VERSION ""

NS_ :

BS_:

BU_:

BO_ 2365446142 EJM1: 8 Vector__XXX
 SG_ Joystick1Button13PressedStatus : 62|2@1+ (1,0) [0|3] "" Vector__XXX
 SG_ Joystick1Button14PressedStatus : 60|2@1+ (1,0) [0|3] "" Vector__XXX
 SG_ Joystick1Button15PressedStatus : 58|2@1+ (1,0) [0|3] "" Vector__XXX
 SG_ Joystick1Button16PressedStatus : 56|2@1+ (1,0) [0|3] "" Vector__XXX
 SG_ Joystick1GripXAxisPosition : 6|10@1+ (0.1,0) [0|102] "%" Vector__XXX
 SG_ Joystick1GripYAxisPosition : 22|10@1+ (0.1,0) [0|102] "%" Vector__XXX
 SG_ Joystick1ThetaAxisPosition : 38|10@1+ (0.1,0) [0|102] "%" Vector__XXX
 SG_ Jst1GpYAxsLvFwdPstvPstStts : 20|2@1+ (1,0) [0|3] "" Vector__XXX
 SG_ Jst1TtAxsCtCwsNtvPstStts : 34|2@1+ (1,0) [0|3] "" Vector__XXX
 SG_ Jstk1GrpXAxsDtntPstnStts : 54|2@1+ (1,0) [0|3] "" Vector__XXX
 SG_ Jstk1GrpXAxsLvrLftNgtvPstnStts : 2|2@1+ (1,0) [0|3] "" Vector__XXX
 SG_ Jstk1GrpXAxsLvrRghtPstvPstnStts : 4|2@1+ (1,0) [0|3] "" Vector__XXX
 SG_ Jstk1GrpXAxsNtrlPstnStts : 0|2@1+ (1,0) [0|3] "" Vector__XXX
 SG_ Jstk1GrpYAxsDtntPstnStts : 52|2@1+ (1,0) [0|3] "" Vector__XXX
 SG_ Jstk1GrpYAxsLvrBkNgtvPstnStts : 18|2@1+ (1,0) [0|3] "" Vector__XXX
 SG_ Jstk1GrpYAxsNtrlPstnStts : 16|2@1+ (1,0) [0|3] "" Vector__XXX
 SG_ Jstk1ThtAxsClkwsPstvPstnStts : 36|2@1+ (1,0) [0|3] "" Vector__XXX
 SG_ Jstk1ThtAxsDtntPstnStts : 50|2@1+ (1,0) [0|3] "" Vector__XXX
 SG_ Jstk1ThtAxsNtrlPstnStts : 32|2@1+ (1,0) [0|3] "" Vector__XXX

BO_ 2365446398 BJM2: 8 Vector__XXX
 SG_ Joystick2Button10PressedStatus : 60|2@1+ (1,0) [0|3] "" Vector__XXX
 SG_ Joystick2Button11PressedStatus : 58|2@1+ (1,0) [0|3] "" Vector__XXX
 SG_ Joystick2Button12PressedStatus : 56|2@1+ (1,0) [0|3] "" Vector__XXX
 SG_ Joystick2Button1PressedStatus : 46|2@1+ (1,0) [0|3] "" Vector__XXX
 SG_ Joystick2Button2PressedStatus : 44|2@1+ (1,0) [0|3] "" Vector__XXX
 SG_ Joystick2Button3PressedStatus : 42|2@1+ (1,0) [0|3] "" Vector__XXX
 SG_ Joystick2Button4PressedStatus : 40|2@1+ (1,0) [0|3] "" Vector__XXX
 SG_ Joystick2Button5PressedStatus : 54|2@1+ (1,0) [0|3] "" Vector__XXX
 SG_ Joystick2Button6PressedStatus : 52|2@1+ (1,0) [0|3] "" Vector__XXX
 SG_ Joystick2Button7PressedStatus : 50|2@1+ (1,0) [0|3] "" Vector__XXX
 SG_ Joystick2Button8PressedStatus : 48|2@1+ (1,0) [0|3] "" Vector__XXX
 SG_ Joystick2Button9PressedStatus : 62|2@1+ (1,0) [0|3] "" Vector__XXX
 SG_ Joystick2XAxisPosition : 6|10@1+ (0.1,0) [0|102] "%" Vector__XXX
 SG_ Joystick2YAxisPosition : 22|10@1+ (0.1,0) [0|102] "%" Vector__XXX
 SG_ Jstk2XAxsDtntPstnStts : 38|2@1+ (1,0) [0|3] "" Vector__XXX
 SG_ Jstk2XAxsLvrLftNgtvPstnStts : 2|2@1+ (1,0) [0|3] "" Vector__XXX
 SG_ Jstk2XAxsLvrRghtPstvPstnStts : 4|2@1+ (1,0) [0|3] "" Vector__XXX
 SG_ Jstk2XAxsNtrlPstnStts : 0|2@1+ (1,0) [0|3] "" Vector__XXX
 SG_ Jstk2YAxsDtntPstnStts : 36|2@1+ (1,0) [0|3] "" Vector__XXX
 SG_ Jstk2YAxsLvrBkNgtvPstnStts : 18|2@1+ (1,0) [0|3] "" Vector__XXX
 SG_ Jstk2YAxsLvrFrwrdPstvPstnStts : 20|2@1+ (1,0) [0|3] "" Vector__XXX
 SG_ Jstk2YAxsNtrlPstnStts : 16|2@1+ (1,0) [0|3] "" Vector__XXX

BO_ 2365446654 EJM2: 8 Vector__XXX
 SG_ Joystick2Button13PressedStatus : 62|2@1+ (1,0) [0|3] "" Vector__XXX
 SG_ Joystick2Button14PressedStatus : 60|2@1+ (1,0) [0|3] "" Vector__XXX
 SG_ Joystick2Button15PressedStatus : 58|2@1+ (1,0) [0|3] "" Vector__XXX
 SG_ Joystick2Button16PressedStatus : 56|2@1+ (1,0) [0|3] "" Vector__XXX
 SG_ Joystick2GripXAxisPosition : 6|10@1+ (0.1,0) [0|102] "%" Vector__XXX
 SG_ Joystick2GripYAxisPosition : 22|10@1+ (0.1,0) [0|102] "%" Vector__XXX
 SG_ Joystick2ThetaAxisPosition : 38|10@1+ (0.1,0) [0|102] "%" Vector__XXX
 SG_ Jst2GpYAxsLvFwdPstvPstStts : 20|2@1+ (1,0) [0|3] "" Vector__XXX
 SG_ Jst2TtAxsCtCwsNtvPstStts : 34|2@1+ (1,0) [0|3] "" Vector__XXX
 SG_ Jstk2GrpXAxsDtntPstnStts : 54|2@1+ (1,0) [0|3] "" Vector__XXX
 SG_ Jstk2GrpXAxsLvrLftNgtvPstnStts : 2|2@1+ (1,0) [0|3] "" Vector__XXX
 SG_ Jstk2GrpXAxsLvrRghtPstvPstnStts : 4|2@1+ (1,0) [0|3] "" Vector__XXX
 SG_ Jstk2GrpXAxsNtrlPstnStts : 0|2@1+ (1,0) [0|3] "" Vector__XXX
 SG_ Jstk2GrpYAxsDtntPstnStts : 52|2@1+ (1,0) [0|3] "" Vector__XXX
 SG_ Jstk2GrpYAxsLvrBkNgtvPstnStts : 18|2@1+ (1,0) [0|3] "" Vector__XXX
 SG_ Jstk2GrpYAxsNtrlPstnStts : 16|2@1+ (1,0) [0|3] "" Vector__XXX
 SG_ Jstk2ThtAxsClkwsPstvPstnStts : 36|2@1+ (1,0) [0|3] "" Vector__XXX
 SG_ Jstk2ThtAxsDtntPstnStts : 50|2@1+ (1,0) [0|3] "" Vector__XXX
 SG_ Jstk2ThtAxsNtrlPstnStts : 32|2@1+ (1,0) [0|3] "" Vector__XXX

BO_ 2365446910 BJM3: 8 Vector__XXX
 SG_ Joystick3Button10PressedStatus : 60|2@1+ (1,0) [0|3] "" Vector__XXX
 SG_ Joystick3Button11PressedStatus : 58|2@1+ (1,0) [0|3] "" Vector__XXX
 SG_ Joystick3Button12PressedStatus : 56|2@1+ (1,0) [0|3] "" Vector__XXX
 SG_ Joystick3Button1PressedStatus : 46|2@1+ (1,0) [0|3] "" Vector__XXX
 SG_ Joystick3Button2PressedStatus : 44|2@1+ (1,0) [0|3] "" Vector__XXX
 SG_ Joystick3Button3PressedStatus : 42|2@1+ (1,0) [0|3] "" Vector__XXX
 SG_ Joystick3Button4PressedStatus : 40|2@1+ (1,0) [0|3] "" Vector__XXX
 SG_ Joystick3Button5PressedStatus : 54|2@1+ (1,0) [0|3] "" Vector__XXX
 SG_ Joystick3Button6PressedStatus : 52|2@1+ (1,0) [0|3] "" Vector__XXX
 SG_ Joystick3Button7PressedStatus : 50|2@1+ (1,0) [0|3] "" Vector__XXX
 SG_ Joystick3Button8PressedStatus : 48|2@1+ (1,0) [0|3] "" Vector__XXX
 SG_ Joystick3Button9PressedStatus : 62|2@1+ (1,0) [0|3] "" Vector__XXX
 SG_ Joystick3XAxisPosition : 6|10@1+ (0.1,0) [0|102] "%" Vector__XXX
 SG_ Joystick3YAxisPosition : 22|10@1+ (0.1,0) [0|102] "%" Vector__XXX
 SG_ Jstk3XAxsDtntPstnStts : 38|2@1+ (1,0) [0|3] "" Vector__XXX
 SG_ Jstk3XAxsLvrLftNgtvPstnStts : 2|2@1+ (1,0) [0|3] "" Vector__XXX
 SG_ Jstk3XAxsLvrRghtPstvPstnStts : 4|2@1+ (1,0) [0|3] "" Vector__XXX
 SG_ Jstk3XAxsNtrlPstnStts : 0|2@1+ (1,0) [0|3] "" Vector__XXX
 SG_ Jstk3YAxsDtntPstnStts : 36|2@1+ (1,0) [0|3] "" Vector__XXX
 SG_ Jstk3YAxsLvrBkNgtvPstnStts : 18|2@1+ (1,0) [0|3] "" Vector__XXX
 SG_ Jstk3YAxsLvrFrwrdPstvPstnStts : 20|2@1+ (1,0) [0|3] "" Vector__XXX
 SG_ Jstk3YAxsNtrlPstnStts : 16|2@1+ (1,0) [0|3] "" Vector__XXX

BO_ 2365447166 EJM3: 8 Vector__XXX
 SG_ Joystick3Button13PressedStatus : 62|2@1+ (1,0) [0|3] "" Vector__XXX
 SG_ Joystick3Button14PressedStatus : 60|2@1+ (1,0) [0|3] "" Vector__XXX
 SG_ Joystick3Button15PressedStatus : 58|2@1+ (1,0) [0|3] "" Vector__XXX
 SG_ Joystick3Button16PressedStatus : 56|2@1+ (1,0) [0|3] "" Vector__XXX
 SG_ Joystick3GripXAxisPosition : 6|10@1+ (0.1,0) [0|102] "%" Vector__XXX
 SG_ Joystick3GripYAxisPosition : 22|10@1+ (0.1,0) [0|102] "%" Vector__XXX
 SG_ Joystick3ThetaAxisPosition : 38|10@1+ (0.1,0) [0|102] "%" Vector__XXX
 SG_ Jst3GpYAxsLvFwdPstvPstStts : 20|2@1+ (1,0) [0|3] "" Vector__XXX
 SG_ Jst3TtAxsCtCwsNtvPstStts : 34|2@1+ (1,0) [0|3] "" Vector__XXX
 SG_ Jstk3GrpXAxsDtntPstnStts : 54|2@1+ (1,0) [0|3] "" Vector__XXX
 SG_ Jstk3GrpXAxsLvrLftNgtvPstnStts : 2|2@1+ (1,0) [0|3] "" Vector__XXX
 SG_ Jstk3GrpXAxsLvrRghtPstvPstnStts : 4|2@1+ (1,0) [0|3] "" Vector__XXX
 SG_ Jstk3GrpXAxsNtrlPstnStts : 0|2@1+ (1,0) [0|3] "" Vector__XXX
 SG_ Jstk3GrpYAxsDtntPstnStts : 52|2@1+ (1,0) [0|3] "" Vector__XXX
 SG_ Jstk3GrpYAxsLvrBkNgtvPstnStts : 18|2@1+ (1,0) [0|3] "" Vector__XXX
 SG_ Jstk3GrpYAxsNtrlPstnStts : 16|2@1+ (1,0) [0|3] "" Vector__XXX
 SG_ Jstk3ThtAxsClkwsPstvPstnStts : 36|2@1+ (1,0) [0|3] "" Vector__XXX
 SG_ Jstk3ThtAxsDtntPstnStts : 50|2@1+ (1,0) [0|3] "" Vector__XXX
 SG_ Jstk3ThtAxsNtrlPstnStts : 32|2@1+ (1,0) [0|3] "" Vector__XXX

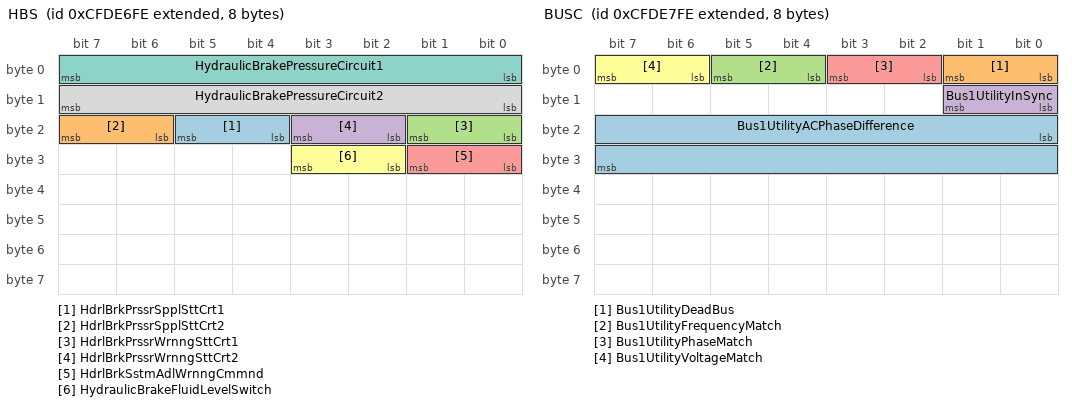
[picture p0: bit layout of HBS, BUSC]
BO_ 2365449982 HBS: 8 Vector__XXX
 SG_ HdrlBrkPrssrSpplSttCrt1 : 20|2@1+ (1,0) [0|3] "" Vector__XXX
 SG_ HdrlBrkPrssrSpplSttCrt2 : 22|2@1+ (1,0) [0|3] "" Vector__XXX
 SG_ HdrlBrkPrssrWrnngSttCrt1 : 16|2@1+ (1,0) [0|3] "" Vector__XXX
 SG_ HdrlBrkPrssrWrnngSttCrt2 : 18|2@1+ (1,0) [0|3] "" Vector__XXX
 SG_ HdrlBrkSstmAdlWrnngCmmnd : 24|2@1+ (1,0) [0|3] "" Vector__XXX
 SG_ HydraulicBrakeFluidLevelSwitch : 26|2@1+ (1,0) [0|3] "" Vector__XXX
 SG_ HydraulicBrakePressureCircuit1 : 0|8@1+ (100,0) [0|25000] "kPa" Vector__XXX
 SG_ HydraulicBrakePressureCircuit2 : 8|8@1+ (100,0) [0|25000] "kPa" Vector__XXX

BO_ 2365450238 BUSC: 8 Vector__XXX
 SG_ Bus1UtilityACPhaseDifference : 16|16@1+ (0.0078125,-200) [-200|301.99] "deg" Vector__XXX
 SG_ Bus1UtilityDeadBus : 0|2@1+ (1,0) [0|3] "" Vector__XXX
 SG_ Bus1UtilityFrequencyMatch : 4|2@1+ (1,0) [0|3] "" Vector__XXX
 SG_ Bus1UtilityInSync : 8|2@1+ (1,0) [0|3] "" Vector__XXX
 SG_ Bus1UtilityPhaseMatch : 2|2@1+ (1,0) [0|3] "" Vector__XXX
 SG_ Bus1UtilityVoltageMatch : 6|2@1+ (1,0) [0|3] "" Vector__XXX

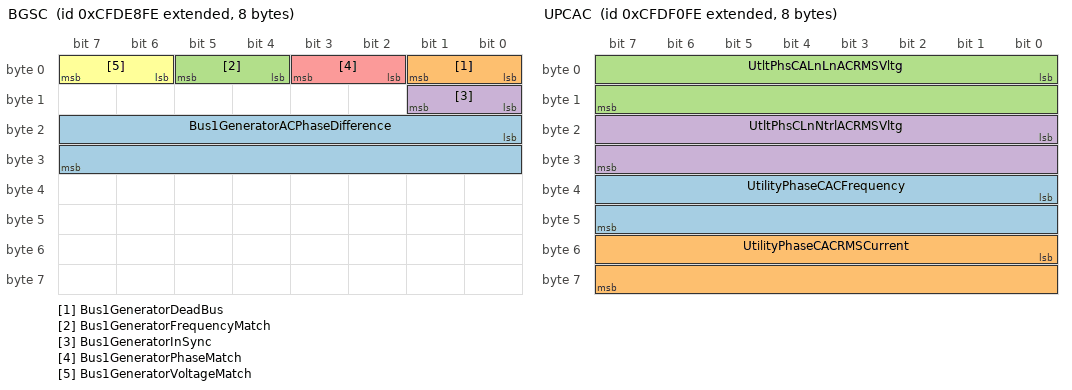
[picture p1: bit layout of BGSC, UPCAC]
BO_ 2365450494 BGSC: 8 Vector__XXX
 SG_ Bus1GeneratorACPhaseDifference : 16|16@1+ (0.0078125,-200) [-200|301.99] "deg" Vector__XXX
 SG_ Bus1GeneratorDeadBus : 0|2@1+ (1,0) [0|3] "" Vector__XXX
 SG_ Bus1GeneratorFrequencyMatch : 4|2@1+ (1,0) [0|3] "" Vector__XXX
 SG_ Bus1GeneratorInSync : 8|2@1+ (1,0) [0|3] "" Vector__XXX
 SG_ Bus1GeneratorPhaseMatch : 2|2@1+ (1,0) [0|3] "" Vector__XXX
 SG_ Bus1GeneratorVoltageMatch : 6|2@1+ (1,0) [0|3] "" Vector__XXX

BO_ 2365450750 BPCAC: 8 Vector__XXX
 SG_ Bs1PhsCLnNtrlACRMSVltg : 16|16@1+ (1,0) [0|64255] "V" Vector__XXX
 SG_ Bus1PhaseCACFrequency : 32|16@1+ (0.0078125,0) [0|501.9921875] "Hz" Vector__XXX
 SG_ Bus1PhaseCALineLineACRMSVoltage : 0|16@1+ (1,0) [0|64255] "V" Vector__XXX

BO_ 2365451006 BPBAC: 8 Vector__XXX
 SG_ Bs1PhsBLnNtrlACRMSVltg : 16|16@1+ (1,0) [0|64255] "V" Vector__XXX
 SG_ Bus1PhaseBACFrequency : 32|16@1+ (0.0078125,0) [0|501.9921875] "Hz" Vector__XXX
 SG_ Bus1PhaseBCLineLineACRMSVoltage : 0|16@1+ (1,0) [0|64255] "V" Vector__XXX

BO_ 2365451262 BPAAC: 8 Vector__XXX
 SG_ Bs1PhsALnNtrlACRMSVltg : 16|16@1+ (1,0) [0|64255] "V" Vector__XXX
 SG_ Bus1PhaseAACFrequency : 32|16@1+ (0.0078125,0) [0|501.9921875] "Hz" Vector__XXX
 SG_ Bus1PhaseABLineLineACRMSVoltage : 0|16@1+ (1,0) [0|64255] "V" Vector__XXX

BO_ 2365451518 BAAC: 8 Vector__XXX
 SG_ Bs1AvrgLnNtrlACRMSVltg : 16|16@1+ (1,0) [0|64255] "V" Vector__XXX
 SG_ Bus1AverageACFrequency : 32|16@1+ (0.0078125,0) [0|501.9921875] "Hz" Vector__XXX
 SG_ Bus1AverageLineLineACRMSVoltage : 0|16@1+ (1,0) [0|64255] "V" Vector__XXX

BO_ 2365451774 UTACE: 8 Vector__XXX
 SG_ UtilityTotalkWHoursExport : 0|32@1+ (1,0) [0|4211081215] "kWh" Vector__XXX
 SG_ UtilityTotalkWHoursImport : 32|32@1+ (1,0) [0|4211081215] "kWh" Vector__XXX

BO_ 2365452030 UPCACR: 8 Vector__XXX
 SG_ UtilityPhaseCPowerFactor : 32|16@1+ (0.00006103515625,-1) [-1|2.921814] "" Vector__XXX
 SG_ UtilityPhaseCPowerFactorLagging : 48|2@1+ (1,0) [0|3] "" Vector__XXX
 SG_ UtilityPhaseCReactivePower : 0|32@1+ (1,-2000000000) [-2000000000|2211081215] "VAr" Vector__XXX

BO_ 2365452286 UPCACP: 8 Vector__XXX
 SG_ UtilityPhaseCApparentPower : 32|32@1+ (1,-2000000000) [-2000000000|2211081215] "VA" Vector__XXX
 SG_ UtilityPhaseCRealPower : 0|32@1+ (1,-2000000000) [-2000000000|2211081215] "W" Vector__XXX

BO_ 2365452542 UPCAC: 8 Vector__XXX
 SG_ UtilityPhaseCACFrequency : 32|16@1+ (0.0078125,0) [0|501.9921875] "Hz" Vector__XXX
 SG_ UtilityPhaseCACRMSCurrent : 48|16@1+ (1,0) [0|64255] "A" Vector__XXX
 SG_ UtltPhsCALnLnACRMSVltg : 0|16@1+ (1,0) [0|64255] "V" Vector__XXX
 SG_ UtltPhsCLnNtrlACRMSVltg : 16|16@1+ (1,0) [0|64255] "V" Vector__XXX

BO_ 2365452798 UPBACR: 8 Vector__XXX
 SG_ UtilityPhaseBPowerFactor : 32|16@1+ (0.00006103515625,-1) [-1|2.921814] "" Vector__XXX
 SG_ UtilityPhaseBPowerFactorLagging : 48|2@1+ (1,0) [0|3] "" Vector__XXX
 SG_ UtilityPhaseBReactivePower : 0|32@1+ (1,-2000000000) [-2000000000|2211081215] "VAr" Vector__XXX

BO_ 2365453054 UPBACP: 8 Vector__XXX
 SG_ UtilityPhaseBApparentPower : 32|32@1+ (1,-2000000000) [-2000000000|2211081215] "VA" Vector__XXX
 SG_ UtilityPhaseBRealPower : 0|32@1+ (1,-2000000000) [-2000000000|2211081215] "W" Vector__XXX

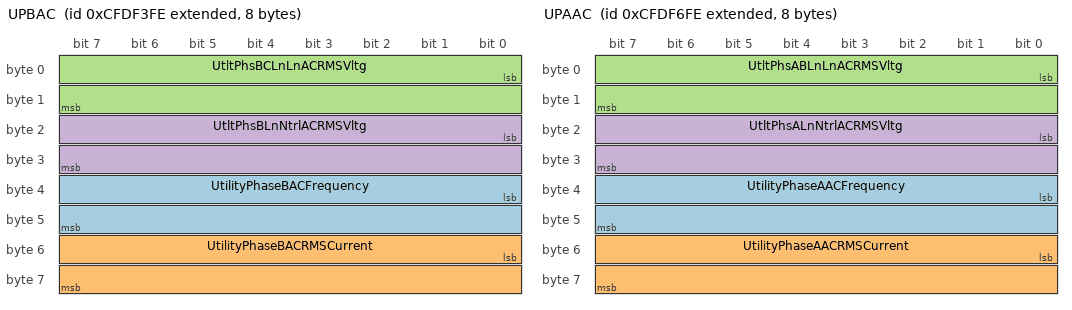
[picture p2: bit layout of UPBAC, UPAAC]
BO_ 2365453310 UPBAC: 8 Vector__XXX
 SG_ UtilityPhaseBACFrequency : 32|16@1+ (0.0078125,0) [0|501.9921875] "Hz" Vector__XXX
 SG_ UtilityPhaseBACRMSCurrent : 48|16@1+ (1,0) [0|64255] "A" Vector__XXX
 SG_ UtltPhsBCLnLnACRMSVltg : 0|16@1+ (1,0) [0|64255] "V" Vector__XXX
 SG_ UtltPhsBLnNtrlACRMSVltg : 16|16@1+ (1,0) [0|64255] "V" Vector__XXX

BO_ 2365453566 UPACCR: 8 Vector__XXX
 SG_ UtilityPhaseAPowerFactor : 32|16@1+ (0.00006103515625,-1) [-1|2.921814] "" Vector__XXX
 SG_ UtilityPhaseAPowerFactorLagging : 48|2@1+ (1,0) [0|3] "" Vector__XXX
 SG_ UtilityPhaseAReactivePower : 0|32@1+ (1,-2000000000) [-2000000000|2211081215] "VAr" Vector__XXX

BO_ 2365453822 UPAACP: 8 Vector__XXX
 SG_ UtilityPhaseAApparentPower : 32|32@1+ (1,-2000000000) [-2000000000|2211081215] "VA" Vector__XXX
 SG_ UtilityPhaseARealPower : 0|32@1+ (1,-2000000000) [-2000000000|2211081215] "W" Vector__XXX

BO_ 2365454078 UPAAC: 8 Vector__XXX
 SG_ UtilityPhaseAACFrequency : 32|16@1+ (0.0078125,0) [0|501.9921875] "Hz" Vector__XXX
 SG_ UtilityPhaseAACRMSCurrent : 48|16@1+ (1,0) [0|64255] "A" Vector__XXX
 SG_ UtltPhsABLnLnACRMSVltg : 0|16@1+ (1,0) [0|64255] "V" Vector__XXX
 SG_ UtltPhsALnNtrlACRMSVltg : 16|16@1+ (1,0) [0|64255] "V" Vector__XXX

BO_ 2365454334 UTACR: 8 Vector__XXX
 SG_ UtilityOverallPowerFactor : 32|16@1+ (0.00006103515625,-1) [-1|2.921814] "" Vector__XXX
 SG_ UtilityTotalReactivePower : 0|32@1+ (1,-2000000000) [-2000000000|2211081215] "VAr" Vector__XXX
 SG_ UtltOvrllPwrFtrLggng : 48|2@1+ (1,0) [0|3] "" Vector__XXX

BO_ 2365454590 UTACP: 8 Vector__XXX
 SG_ UtilityTotalApparentPower : 32|32@1+ (1,-2000000000) [-2000000000|2211081215] "VA" Vector__XXX
 SG_ UtilityTotalRealPower : 0|32@1+ (1,-2000000000) [-2000000000|2211081215] "W" Vector__XXX

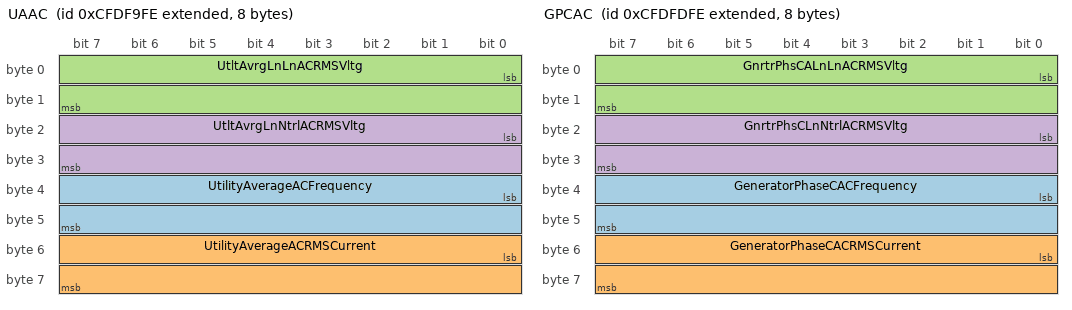
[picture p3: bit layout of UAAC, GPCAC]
BO_ 2365454846 UAAC: 8 Vector__XXX
 SG_ UtilityAverageACFrequency : 32|16@1+ (0.0078125,0) [0|501.9921875] "Hz" Vector__XXX
 SG_ UtilityAverageACRMSCurrent : 48|16@1+ (1,0) [0|64255] "A" Vector__XXX
 SG_ UtltAvrgLnLnACRMSVltg : 0|16@1+ (1,0) [0|64255] "V" Vector__XXX
 SG_ UtltAvrgLnNtrlACRMSVltg : 16|16@1+ (1,0) [0|64255] "V" Vector__XXX

BO_ 2365455102 GTACE: 8 Vector__XXX
 SG_ GeneratorTotalkWHoursExport : 0|32@1+ (1,0) [0|4211081215] "kWh" Vector__XXX
 SG_ GeneratorTotalkWHoursImport : 32|32@1+ (1,0) [0|4211081215] "kWh" Vector__XXX

BO_ 2365455358 GPCACR: 8 Vector__XXX
 SG_ GeneratorPhaseCPowerFactor : 32|16@1+ (0.00006103515625,-1) [-1|2.921814] "" Vector__XXX
 SG_ GeneratorPhaseCReactivePower : 0|32@1+ (1,-2000000000) [-2000000000|2211081215] "VAr" Vector__XXX
 SG_ GnrtrPhsCPwrFtrLggng : 48|2@1+ (1,0) [0|3] "" Vector__XXX

BO_ 2365455614 GPCACP: 8 Vector__XXX
 SG_ GeneratorPhaseCApparentPower : 32|32@1+ (1,-2000000000) [-2000000000|2211081215] "VA" Vector__XXX
 SG_ GeneratorPhaseCRealPower : 0|32@1+ (1,-2000000000) [-2000000000|2211081215] "W" Vector__XXX

BO_ 2365455870 GPCAC: 8 Vector__XXX
 SG_ GeneratorPhaseCACFrequency : 32|16@1+ (0.0078125,0) [0|501.9921875] "Hz" Vector__XXX
 SG_ GeneratorPhaseCACRMSCurrent : 48|16@1+ (1,0) [0|64255] "A" Vector__XXX
 SG_ GnrtrPhsCALnLnACRMSVltg : 0|16@1+ (1,0) [0|64255] "V" Vector__XXX
 SG_ GnrtrPhsCLnNtrlACRMSVltg : 16|16@1+ (1,0) [0|64255] "V" Vector__XXX

BO_ 2365456126 GPBACRP: 8 Vector__XXX
 SG_ GeneratorPhaseBPowerFactor : 32|16@1+ (0.00006103515625,-1) [-1|2.921814] "" Vector__XXX
 SG_ GeneratorPhaseBReactivePower : 0|32@1+ (1,-2000000000) [-2000000000|2211081215] "VAr" Vector__XXX
 SG_ GnrtrPhsBPwrFtrLggng : 48|2@1+ (1,0) [0|3] "" Vector__XXX

BO_ 2365456382 GPBACP: 8 Vector__XXX
 SG_ GeneratorPhaseBApparentPower : 32|32@1+ (1,-2000000000) [-2000000000|2211081215] "VA" Vector__XXX
 SG_ GeneratorPhaseBRealPower : 0|32@1+ (1,-2000000000) [-2000000000|2211081215] "W" Vector__XXX

BO_ 2365456894 GPAACR: 8 Vector__XXX
 SG_ GeneratorPhaseAPowerFactor : 32|16@1+ (0.00006103515625,-1) [-1|2.921814] "" Vector__XXX
 SG_ GeneratorPhaseAReactivePower : 0|32@1+ (1,-2000000000) [-2000000000|2211081215] "VAr" Vector__XXX
 SG_ GnrtrPhsAPwrFtrLggng : 48|2@1+ (1,0) [0|3] "" Vector__XXX

BO_ 2365457150 GPAACP: 8 Vector__XXX
 SG_ GeneratorPhaseAApparentPower : 32|32@1+ (1,-2000000000) [-2000000000|2211081215] "VA" Vector__XXX
 SG_ GeneratorPhaseARealPower : 0|32@1+ (1,-2000000000) [-2000000000|2211081215] "W" Vector__XXX

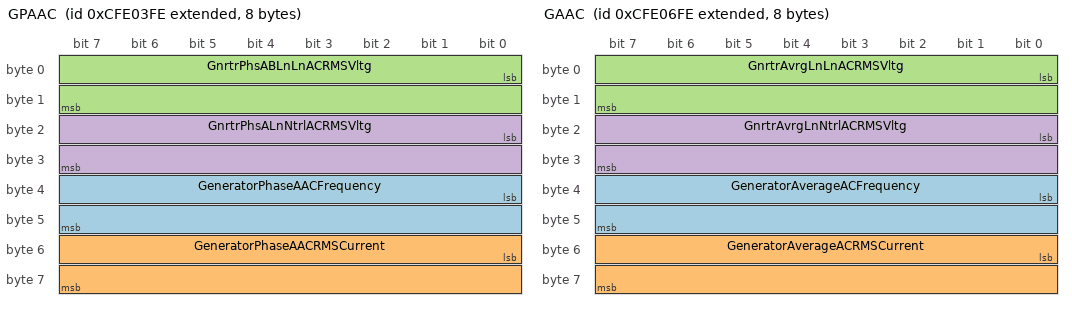
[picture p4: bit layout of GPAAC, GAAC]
BO_ 2365457406 GPAAC: 8 Vector__XXX
 SG_ GeneratorPhaseAACFrequency : 32|16@1+ (0.0078125,0) [0|501.9921875] "Hz" Vector__XXX
 SG_ GeneratorPhaseAACRMSCurrent : 48|16@1+ (1,0) [0|64255] "A" Vector__XXX
 SG_ GnrtrPhsABLnLnACRMSVltg : 0|16@1+ (1,0) [0|64255] "V" Vector__XXX
 SG_ GnrtrPhsALnNtrlACRMSVltg : 16|16@1+ (1,0) [0|64255] "V" Vector__XXX

BO_ 2365457662 GTACR: 8 Vector__XXX
 SG_ GeneratorOverallPowerFactor : 32|16@1+ (0.00006103515625,-1) [-1|2.921814] "" Vector__XXX
 SG_ GeneratorTotalReactivePower : 0|32@1+ (1,-2000000000) [-2000000000|2211081215] "VAr" Vector__XXX
 SG_ GnrtrOvrllPwrFtrLggng : 48|2@1+ (1,0) [0|3] "" Vector__XXX

BO_ 2365457918 GTACP: 8 Vector__XXX
 SG_ GeneratorTotalApparentPower : 32|32@1+ (1,-2000000000) [-2000000000|2211081215] "VA" Vector__XXX
 SG_ GeneratorTotalRealPower : 0|32@1+ (1,-2000000000) [-2000000000|2211081215] "W" Vector__XXX

BO_ 2365458174 GAAC: 8 Vector__XXX
 SG_ GeneratorAverageACFrequency : 32|16@1+ (0.0078125,0) [0|501.9921875] "Hz" Vector__XXX
 SG_ GeneratorAverageACRMSCurrent : 48|16@1+ (1,0) [0|64255] "A" Vector__XXX
 SG_ GnrtrAvrgLnLnACRMSVltg : 0|16@1+ (1,0) [0|64255] "V" Vector__XXX
 SG_ GnrtrAvrgLnNtrlACRMSVltg : 16|16@1+ (1,0) [0|64255] "V" Vector__XXX

BO_ 2365473278 LCMD: 8 Vector__XXX
 SG_ AlternateBeamHeadLightCommand : 2|2@1+ (1,0) [0|3] "" Vector__XXX
 SG_ BackUpLightandAlarmHornCommand : 16|2@1+ (1,0) [0|3] "" Vector__XXX
 SG_ CenterStopLightCommand : 18|2@1+ (1,0) [0|3] "" Vector__XXX
 SG_ HighBeamHeadLightCommand : 6|2@1+ (1,0) [0|3] "" Vector__XXX
 SG_ ImplementClearanceLightCommand : 24|2@1+ (1,0) [0|3] "" Vector__XXX
 SG_ ImplementMarkerLightCommand : 28|2@1+ (1,0) [0|3] "" Vector__XXX
 SG_ ImplementOEMOption1LightCommand : 50|2@1+ (1,0) [0|3] "" Vector__XXX
 SG_ ImplementOEMOption2LightCommand : 48|2@1+ (1,0) [0|3] "" Vector__XXX
 SG_ ImplementRearWorkLightCommand : 62|2@1+ (1,0) [0|3] "" Vector__XXX
 SG_ ImplmntLftFngWrkLghtCmmnd : 60|2@1+ (1,0) [0|3] "" Vector__XXX
 SG_ ImplmntLftFrwrdWrkLghtCmmnd : 54|2@1+ (1,0) [0|3] "" Vector__XXX
 SG_ ImplmntRghtFngWrkLghtCmmnd : 52|2@1+ (1,0) [0|3] "" Vector__XXX
 SG_ ImplmntRghtFrwrdWrkLghtCmmnd : 58|2@1+ (1,0) [0|3] "" Vector__XXX
 SG_ LeftStopLightCommand : 22|2@1+ (1,0) [0|3] "" Vector__XXX
 SG_ LeftTurnSignalLightsCommand : 14|2@1+ (1,0) [0|3] "" Vector__XXX
 SG_ LightingDataRequestCommand : 56|2@1+ (1,0) [0|3] "" Vector__XXX
 SG_ LowBeamHeadLightCommand : 4|2@1+ (1,0) [0|3] "" Vector__XXX
 SG_ RearFogLightCommand : 32|2@1+ (1,0) [0|3] "" Vector__XXX
 SG_ RightStopLightCommand : 20|2@1+ (1,0) [0|3] "" Vector__XXX
 SG_ RightTurnSignalLightsCommand : 12|2@1+ (1,0) [0|3] "" Vector__XXX
 SG_ RotatingBeaconLightCommand : 10|2@1+ (1,0) [0|3] "" Vector__XXX
 SG_ RunningLightCommand : 0|2@1+ (1,0) [0|3] "" Vector__XXX
 SG_ TractorClearanceLightCommand : 26|2@1+ (1,0) [0|3] "" Vector__XXX
 SG_ TractorFrontFogLightsCommand : 8|2@1+ (1,0) [0|3] "" Vector__XXX
 SG_ TractorMarkerLightCommand : 30|2@1+ (1,0) [0|3] "" Vector__XXX
 SG_ TrtrFrntHghMntdWrkLghtsCmmnd : 46|2@1+ (1,0) [0|3] "" Vector__XXX
 SG_ TrtrFrntLwMntdWrkLghtsCmmnd : 44|2@1+ (1,0) [0|3] "" Vector__XXX
 SG_ TrtrRrHghMntdWrkLghtsCmmnd : 38|2@1+ (1,0) [0|3] "" Vector__XXX
 SG_ TrtrRrLwMntdWrkLghtsCmmnd : 36|2@1+ (1,0) [0|3] "" Vector__XXX
 SG_ TrtrSdHghMntdWrkLghtsCmmnd : 42|2@1+ (1,0) [0|3] "" Vector__XXX
 SG_ TrtrSdLwMntdWrkLghtsCmmnd : 40|2@1+ (1,0) [0|3] "" Vector__XXX
 SG_ TrtrUndrsdMntdWrkLghtsCmmnd : 34|2@1+ (1,0) [0|3] "" Vector__XXX

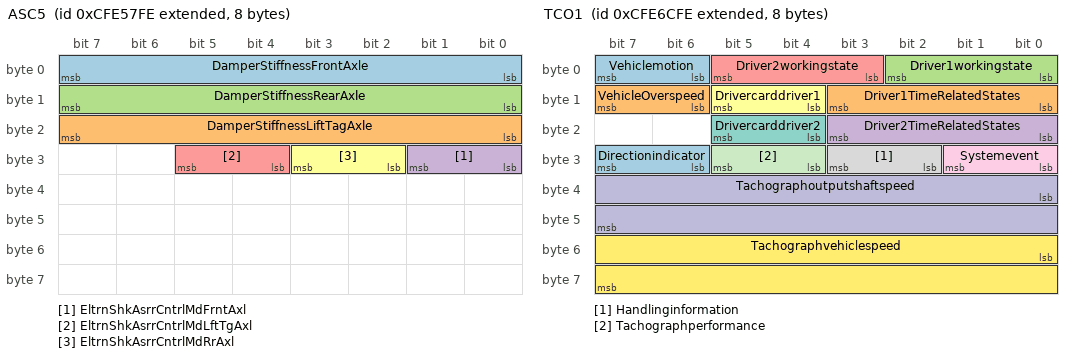
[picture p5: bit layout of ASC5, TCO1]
BO_ 2365478910 ASC5: 8 Vector__XXX
 SG_ DamperStiffnessFrontAxle : 0|8@1+ (0.4,0) [0|100] "%" Vector__XXX
 SG_ DamperStiffnessLiftTagAxle : 16|8@1+ (0.4,0) [0|100] "%" Vector__XXX
 SG_ DamperStiffnessRearAxle : 8|8@1+ (0.4,0) [0|100] "%" Vector__XXX
 SG_ EltrnShkAsrrCntrlMdFrntAxl : 24|2@1+ (1,0) [0|3] "" Vector__XXX
 SG_ EltrnShkAsrrCntrlMdLftTgAxl : 28|2@1+ (1,0) [0|3] "" Vector__XXX
 SG_ EltrnShkAsrrCntrlMdRrAxl : 26|2@1+ (1,0) [0|3] "" Vector__XXX

BO_ 2365479678 ASC1: 8 Vector__XXX
 SG_ AboveNominalLevelFrontAxle : 12|2@1+ (1,0) [0|3] "" Vector__XXX
 SG_ AboveNominalLevelRearAxle : 14|2@1+ (1,0) [0|3] "" Vector__XXX
 SG_ AllwLvlCntrlDrngBrkngStts : 52|2@1+ (1,0) [0|3] "" Vector__XXX
 SG_ BelowNominalLevelFrontAxle : 8|2@1+ (1,0) [0|3] "" Vector__XXX
 SG_ BelowNominalLevelRearAxle : 10|2@1+ (1,0) [0|3] "" Vector__XXX
 SG_ DoorRelease : 36|2@1+ (1,0) [0|3] "" Vector__XXX
 SG_ FrontAxleinBumperRange : 40|2@1+ (1,0) [0|3] "" Vector__XXX
 SG_ KneelingInformation : 24|4@1+ (1,0) [0|15] "" Vector__XXX
 SG_ LevelControlMode : 28|4@1+ (1,0) [0|15] "" Vector__XXX
 SG_ LiftAxle1Position : 38|2@1+ (1,0) [0|3] "" Vector__XXX
 SG_ LiftAxle2Position : 46|2@1+ (1,0) [0|3] "" Vector__XXX
 SG_ LiftingControlModeFrontAxle : 20|2@1+ (1,0) [0|3] "" Vector__XXX
 SG_ LiftingControlModeRearAxle : 22|2@1+ (1,0) [0|3] "" Vector__XXX
 SG_ LoweringControlModeFrontAxle : 16|2@1+ (1,0) [0|3] "" Vector__XXX
 SG_ LoweringControlModeRearAxle : 18|2@1+ (1,0) [0|3] "" Vector__XXX
 SG_ Memorylevel : 60|4@1+ (1,0) [0|15] "" Vector__XXX
 SG_ NominalLevelFrontAxle : 0|4@1+ (1,0) [0|15] "" Vector__XXX
 SG_ NominalLevelRearAxle : 4|4@1+ (1,0) [0|15] "" Vector__XXX
 SG_ RearAxleinBumperRange : 42|2@1+ (1,0) [0|3] "" Vector__XXX
 SG_ SecurityDevice : 32|2@1+ (1,0) [0|3] "" Vector__XXX
 SG_ SpdDpndntLvlCntrlStts : 54|2@1+ (1,0) [0|3] "" Vector__XXX
 SG_ SspnsnCntrlRfslInfrmtn : 56|4@1+ (1,0) [0|15] "" Vector__XXX
 SG_ SuspensionRemoteControl1 : 48|2@1+ (1,0) [0|3] "" Vector__XXX
 SG_ SuspensionRemotecontrol2 : 50|2@1+ (1,0) [0|3] "" Vector__XXX
 SG_ VehicleMotionInhibit : 34|2@1+ (1,0) [0|3] "" Vector__XXX

BO_ 2365484286 TCO1: 8 Vector__XXX
 SG_ Directionindicator : 30|2@1+ (1,0) [0|3] "" Vector__XXX
 SG_ Driver1TimeRelatedStates : 8|4@1+ (1,0) [0|15] "" Vector__XXX
 SG_ Driver1workingstate : 0|3@1+ (1,0) [0|7] "" Vector__XXX
 SG_ Driver2TimeRelatedStates : 16|4@1+ (1,0) [0|15] "" Vector__XXX
 SG_ Driver2workingstate : 3|3@1+ (1,0) [0|7] "" Vector__XXX
 SG_ Drivercarddriver1 : 12|2@1+ (1,0) [0|3] "" Vector__XXX
 SG_ Drivercarddriver2 : 20|2@1+ (1,0) [0|3] "" Vector__XXX
 SG_ Handlinginformation : 26|2@1+ (1,0) [0|3] "" Vector__XXX
 SG_ Systemevent : 24|2@1+ (1,0) [0|3] "" Vector__XXX
 SG_ Tachographoutputshaftspeed : 32|16@1+ (0.125,0) [0|8031.875] "rpm" Vector__XXX
 SG_ Tachographperformance : 28|2@1+ (1,0) [0|3] "" Vector__XXX
 SG_ Tachographvehiclespeed : 48|16@1+ (0.00390625,0) [0|250.996] "km/h" Vector__XXX
 SG_ Vehiclemotion : 6|2@1+ (1,0) [0|3] "" Vector__XXX
 SG_ VehicleOverspeed : 14|2@1+ (1,0) [0|3] "" Vector__XXX

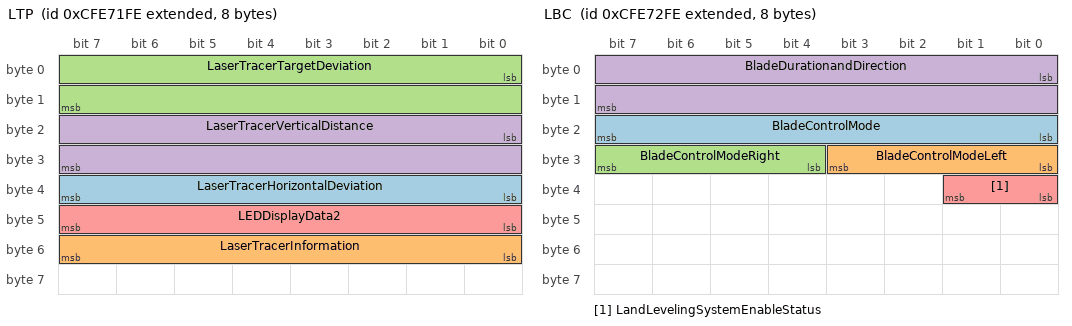
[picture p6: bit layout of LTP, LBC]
BO_ 2365485566 LTP: 8 Vector__XXX
 SG_ LaserTracerHorizontalDeviation : 32|8@1+ (1,0) [0|250] "%" Vector__XXX
 SG_ LaserTracerInformation : 48|8@1+ (1,0) [0|255] "" Vector__XXX
 SG_ LaserTracerTargetDeviation : 0|16@1+ (0.1,-3200) [-3200|3225.5] "mm" Vector__XXX
 SG_ LaserTracerVerticalDistance : 16|16@1+ (0.1,0) [0|6425.5] "mm" Vector__XXX
 SG_ LEDDisplayData2 : 40|8@1+ (1,0) [0|255] "" Vector__XXX

BO_ 2365485822 LBC: 8 Vector__XXX
 SG_ BladeControlMode : 16|8@1+ (1,0) [0|255] "" Vector__XXX
 SG_ BladeControlModeLeft : 24|4@1+ (1,0) [0|15] "" Vector__XXX
 SG_ BladeControlModeRight : 28|4@1+ (1,0) [0|15] "" Vector__XXX
 SG_ BladeDurationandDirection : 0|16@1+ (0.1,-3276.8) [-3276.8|3148.7] "s" Vector__XXX
 SG_ LandLevelingSystemEnableStatus : 32|2@1+ (1,0) [0|3] "" Vector__XXX

BO_ 2365486078 LMP: 8 Vector__XXX
 SG_ MastPosition : 0|16@1+ (0.1,-3200) [-3200|3225.5] "mm" Vector__XXX

BO_ 2365486334 LSP: 8 Vector__XXX
 SG_ BldHghtStPntHghRsltn : 16|32@1+ (0.0000001,-209.7152) [-209.7152|211.3929215] "m" Vector__XXX
 SG_ ModifyLevelingSystemSetPoint : 0|16@1+ (0.1,-3200) [-3200|3225.5] "mm" Vector__XXX

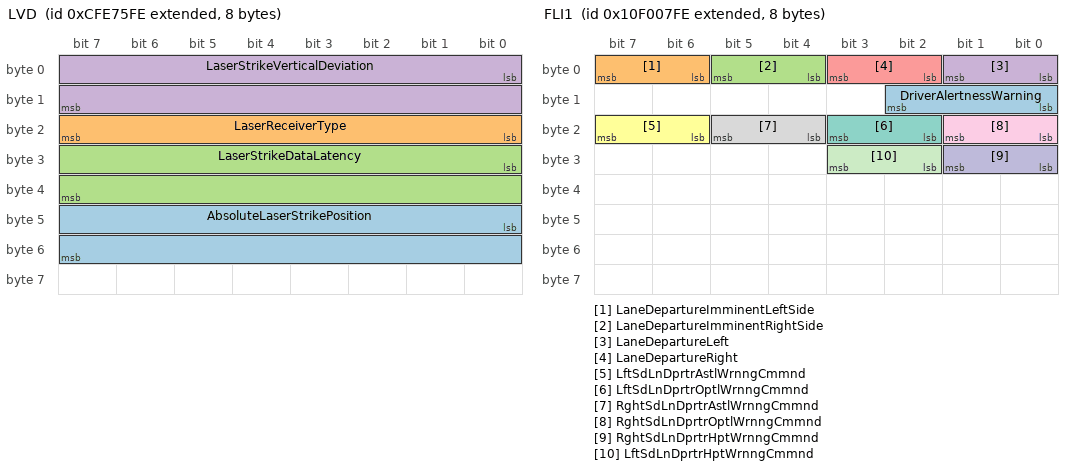
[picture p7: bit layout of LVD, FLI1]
BO_ 2365486590 LVD: 8 Vector__XXX
 SG_ AbsoluteLaserStrikePosition : 40|16@1+ (0.1,0) [0|6425.5] "mm" Vector__XXX
 SG_ LaserReceiverType : 16|8@1+ (1,0) [0|250] "count" Vector__XXX
 SG_ LaserStrikeDataLatency : 24|16@1+ (0.0000512,0) [0|3.289856] "s" Vector__XXX
 SG_ LaserStrikeVerticalDeviation : 0|16@1+ (0.1,-3200) [-3200|3225.5] "mm" Vector__XXX

BO_ 2431649790 FLI1: 8 Vector__XXX
 SG_ DriverAlertnessWarning : 8|3@1+ (1,0) [0|7] "" Vector__XXX
 SG_ LaneDepartureImminentLeftSide : 6|2@1+ (1,0) [0|3] "" Vector__XXX
 SG_ LaneDepartureImminentRightSide : 4|2@1+ (1,0) [0|3] "" Vector__XXX
 SG_ LaneDepartureLeft : 0|2@1+ (1,0) [0|3] "" Vector__XXX
 SG_ LaneDepartureRight : 2|2@1+ (1,0) [0|3] "" Vector__XXX
 SG_ LftSdLnDprtrAstlWrnngCmmnd : 22|2@1+ (1,0) [0|3] "" Vector__XXX
 SG_ LftSdLnDprtrOptlWrnngCmmnd : 18|2@1+ (1,0) [0|3] "" Vector__XXX
 SG_ RghtSdLnDprtrAstlWrnngCmmnd : 20|2@1+ (1,0) [0|3] "" Vector__XXX
 SG_ RghtSdLnDprtrOptlWrnngCmmnd : 16|2@1+ (1,0) [0|3] "" Vector__XXX
 SG_ RghtSdLnDprtrHptWrnngCmmnd : 24|2@1+ (1,0) [0|3] "" Vector__XXX
 SG_ LftSdLnDprtrHptWrnngCmmnd : 26|2@1+ (1,0) [0|3] "" Vector__XXX

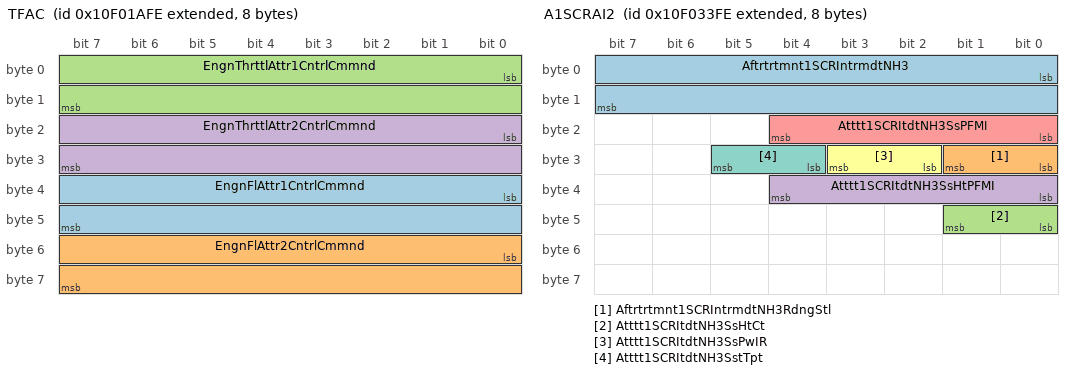
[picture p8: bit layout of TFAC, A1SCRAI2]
BO_ 2431654654 TFAC: 8 Vector__XXX
 SG_ EngnFlAttr1CntrlCmmnd : 32|16@1+ (0.0025,0) [0|160.6375] "%" Vector__XXX
 SG_ EngnFlAttr2CntrlCmmnd : 48|16@1+ (0.0025,0) [0|160.6375] "%" Vector__XXX
 SG_ EngnThrttlAttr1CntrlCmmnd : 0|16@1+ (0.0025,0) [0|160.6375] "%" Vector__XXX
 SG_ EngnThrttlAttr2CntrlCmmnd : 16|16@1+ (0.0025,0) [0|160.6375] "%" Vector__XXX

BO_ 2431661054 A1SCRAI2: 8 Vector__XXX
 SG_ Aftrtrtmnt1SCRIntrmdtNH3 : 0|16@1+ (0.1,-200) [-200|6225.5] "ppm" Vector__XXX
 SG_ Aftrtrtmnt1SCRIntrmdtNH3RdngStl : 24|2@1+ (1,0) [0|3] "" Vector__XXX
 SG_ Atttt1SCRItdtNH3SsHtCt : 40|2@1+ (1,0) [0|3] "" Vector__XXX
 SG_ Atttt1SCRItdtNH3SsHtPFMI : 32|5@1+ (1,0) [0|31] "binary" Vector__XXX
 SG_ Atttt1SCRItdtNH3SsPFMI : 16|5@1+ (1,0) [0|31] "binary" Vector__XXX
 SG_ Atttt1SCRItdtNH3SsPwIR : 26|2@1+ (1,0) [0|3] "" Vector__XXX
 SG_ Atttt1SCRItdtNH3SstTpt : 28|2@1+ (1,0) [0|3] "" Vector__XXX

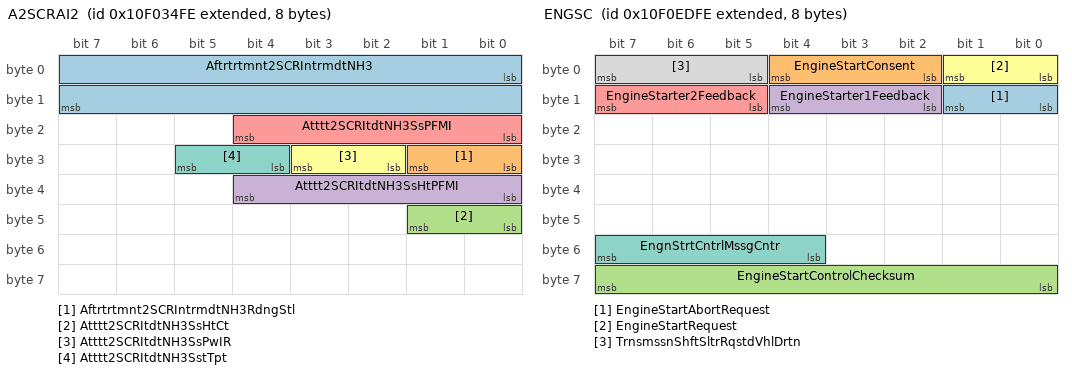
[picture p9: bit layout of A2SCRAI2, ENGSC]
BO_ 2431661310 A2SCRAI2: 8 Vector__XXX
 SG_ Aftrtrtmnt2SCRIntrmdtNH3 : 0|16@1+ (0.1,-200) [-200|6225.5] "ppm" Vector__XXX
 SG_ Aftrtrtmnt2SCRIntrmdtNH3RdngStl : 24|2@1+ (1,0) [0|3] "" Vector__XXX
 SG_ Atttt2SCRItdtNH3SsHtCt : 40|2@1+ (1,0) [0|3] "" Vector__XXX
 SG_ Atttt2SCRItdtNH3SsHtPFMI : 32|5@1+ (1,0) [0|31] "binary" Vector__XXX
 SG_ Atttt2SCRItdtNH3SsPFMI : 16|5@1+ (1,0) [0|31] "binary" Vector__XXX
 SG_ Atttt2SCRItdtNH3SsPwIR : 26|2@1+ (1,0) [0|3] "" Vector__XXX
 SG_ Atttt2SCRItdtNH3SstTpt : 28|2@1+ (1,0) [0|3] "" Vector__XXX

BO_ 2431708670 ENGSC: 8 Vector__XXX
 SG_ EngineStartAbortRequest : 8|2@1+ (1,0) [0|3] "" Vector__XXX
 SG_ EngineStartConsent : 2|3@1+ (1,0) [0|7] "" Vector__XXX
 SG_ EngineStartControlChecksum : 56|8@1+ (1,0) [0|255] "count" Vector__XXX
 SG_ EngineStarter1Feedback : 10|3@1+ (1,0) [0|7] "" Vector__XXX
 SG_ EngineStarter2Feedback : 13|3@1+ (1,0) [0|7] "" Vector__XXX
 SG_ EngineStartRequest : 0|2@1+ (1,0) [0|3] "" Vector__XXX
 SG_ EngnStrtCntrlMssgCntr : 52|4@1+ (1,0) [0|15] "" Vector__XXX
 SG_ TrnsmssnShftSltrRqstdVhlDrtn : 5|3@1+ (1,0) [0|7] "" Vector__XXX

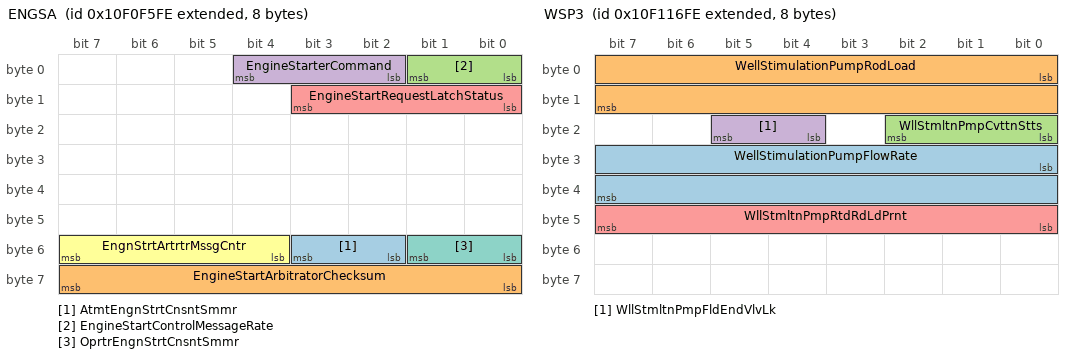
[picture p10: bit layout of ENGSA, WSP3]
BO_ 2431710718 ENGSA: 8 Vector__XXX
 SG_ AtmtEngnStrtCnsntSmmr : 50|2@1+ (1,0) [0|3] "" Vector__XXX
 SG_ EngineStartArbitratorChecksum : 56|8@1+ (1,0) [0|255] "count" Vector__XXX
 SG_ EngineStartControlMessageRate : 0|2@1+ (1,0) [0|3] "" Vector__XXX
 SG_ EngineStarterCommand : 2|3@1+ (1,0) [0|7] "" Vector__XXX
 SG_ EngineStartRequestLatchStatus : 8|4@1+ (1,0) [0|15] "" Vector__XXX
 SG_ EngnStrtArtrtrMssgCntr : 52|4@1+ (1,0) [0|15] "" Vector__XXX
 SG_ OprtrEngnStrtCnsntSmmr : 48|2@1+ (1,0) [0|3] "" Vector__XXX

BO_ 2431717886 GFP3: 8 Vector__XXX
 SG_ EngnFlVlv1DffrntlPrssrHghRsltn : 0|16@1+ (0.0078125,-100) [-100|401.99] "kPa" Vector__XXX
 SG_ EngnGssFlSpplFltrDffrntlPrssr : 16|16@1+ (0.0078125,-100) [-100|401.99] "kPa" Vector__XXX
 SG_ EngnGssFlSpplFltrIntkPrssr : 32|16@1+ (0.5,0) [0|32127.5] "kPa" Vector__XXX

BO_ 2431719166 WSP3: 8 Vector__XXX
 SG_ WellStimulationPumpFlowRate : 24|16@1+ (0.5,0) [0|32127.5] "l/min" Vector__XXX
 SG_ WellStimulationPumpRodLoad : 0|16@1+ (5,0) [0|321275] "kN" Vector__XXX
 SG_ WllStmltnPmpCvttnStts : 16|3@1+ (1,0) [0|7] "" Vector__XXX
 SG_ WllStmltnPmpFldEndVlvLk : 20|2@1+ (1,0) [0|3] "" Vector__XXX
 SG_ WllStmltnPmpRtdRdLdPrnt : 40|8@1+ (0.5,0) [0|125] "%" Vector__XXX

BO_ 2432471038 AF3: 8 Vector__XXX
 SG_ EngnFlVprzr1DshrgTmprtr : 16|8@1+ (1,-40) [-40|210] "degC" Vector__XXX
 SG_ EngnGssFlSpplPrssr1ExtnddRng : 0|16@1+ (0.00390625,0) [0|250.996] "MPa" Vector__XXX
 SG_ GssFlAmltrTmprtr : 24|8@1+ (1,-40) [-40|210] "degC" Vector__XXX
 SG_ EGssFSppPssRtCtCd : 32|16@1+ (0.0025,0) [0|160.6375] "%" Vector__XXX

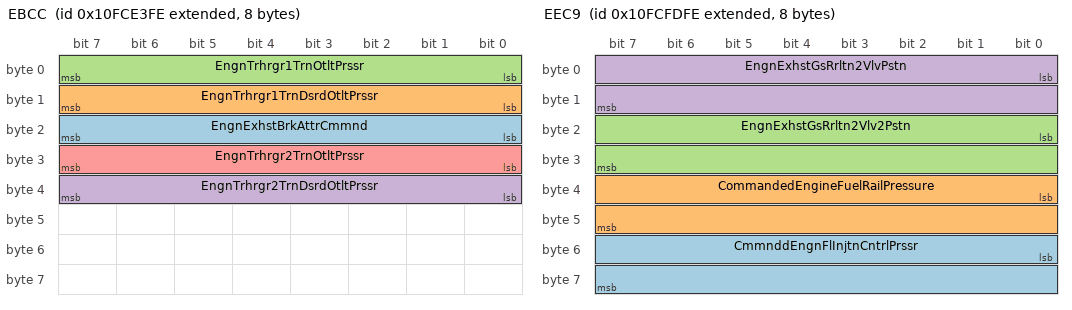
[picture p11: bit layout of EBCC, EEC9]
BO_ 2432492542 EBCC: 8 Vector__XXX
 SG_ EngnExhstBrkAttrCmmnd : 16|8@1+ (0.4,0) [0|100] "%" Vector__XXX
 SG_ EngnTrhrgr1TrnDsrdOtltPrssr : 8|8@1+ (2,0) [0|500] "kPa" Vector__XXX
 SG_ EngnTrhrgr1TrnOtltPrssr : 0|8@1+ (2,0) [0|500] "kPa" Vector__XXX
 SG_ EngnTrhrgr2TrnDsrdOtltPrssr : 32|8@1+ (2,0) [0|500] "kPa" Vector__XXX
 SG_ EngnTrhrgr2TrnOtltPrssr : 24|8@1+ (2,0) [0|500] "kPa" Vector__XXX

BO_ 2432499198 EEC9: 8 Vector__XXX
 SG_ CmmnddEngnFlInjtnCntrlPrssr : 48|16@1+ (0.00390625,0) [0|250.996] "MPa" Vector__XXX
 SG_ CommandedEngineFuelRailPressure : 32|16@1+ (0.00390625,0) [0|250.996] "MPa" Vector__XXX
 SG_ EngnExhstGsRrltn2Vlv2Pstn : 16|16@1+ (0.0025,0) [0|160.6375] "%" Vector__XXX
 SG_ EngnExhstGsRrltn2VlvPstn : 0|16@1+ (0.0025,0) [0|160.6375] "%" Vector__XXX

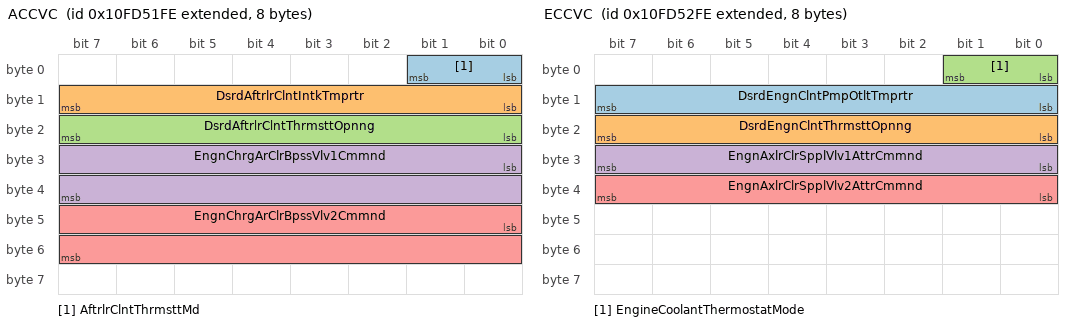
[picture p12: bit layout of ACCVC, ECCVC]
BO_ 2432520702 ACCVC: 8 Vector__XXX
 SG_ AftrlrClntThrmsttMd : 0|2@1+ (1,0) [0|3] "" Vector__XXX
 SG_ DsrdAftrlrClntIntkTmprtr : 8|8@1+ (1,-40) [-40|210] "degC" Vector__XXX
 SG_ DsrdAftrlrClntThrmsttOpnng : 16|8@1+ (0.4,0) [0|100] "%" Vector__XXX
 SG_ EngnChrgArClrBpssVlv1Cmmnd : 24|16@1+ (0.0025,0) [0|160.6375] "%" Vector__XXX
 SG_ EngnChrgArClrBpssVlv2Cmmnd : 40|16@1+ (0.0025,0) [0|160.6375] "%" Vector__XXX

BO_ 2432520958 ECCVC: 8 Vector__XXX
 SG_ DsrdEngnClntPmpOtltTmprtr : 8|8@1+ (1,-40) [-40|210] "degC" Vector__XXX
 SG_ DsrdEngnClntThrmsttOpnng : 16|8@1+ (0.4,0) [0|100] "%" Vector__XXX
 SG_ EngineCoolantThermostatMode : 0|2@1+ (1,0) [0|3] "" Vector__XXX
 SG_ EngnAxlrClrSpplVlv1AttrCmmnd : 24|8@1+ (0.4,0) [0|100] "%" Vector__XXX
 SG_ EngnAxlrClrSpplVlv2AttrCmmnd : 32|8@1+ (0.4,0) [0|100] "%" Vector__XXX

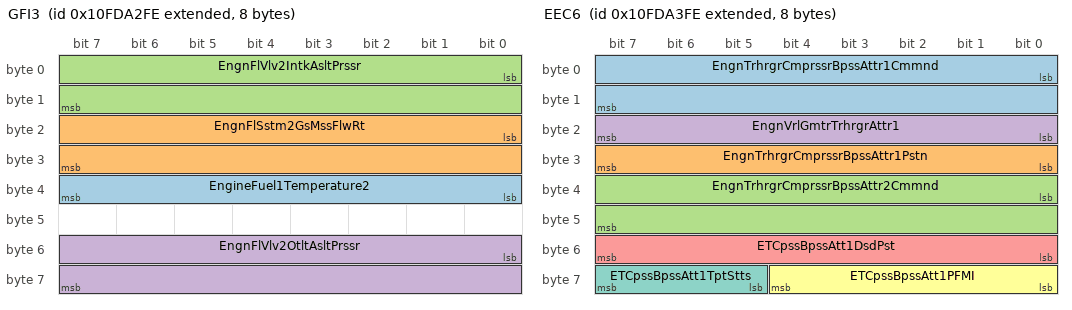
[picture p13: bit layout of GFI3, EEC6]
BO_ 2432541438 GFI3: 8 Vector__XXX
 SG_ EngineFuel1Temperature2 : 32|8@1+ (1,-40) [-40|210] "degC" Vector__XXX
 SG_ EngnFlSstm2GsMssFlwRt : 16|16@1+ (0.05,0) [0|3212.75] "kg/h" Vector__XXX
 SG_ EngnFlVlv2IntkAsltPrssr : 0|16@1+ (0.1,0) [0|6425.5] "kPa" Vector__XXX
 SG_ EngnFlVlv2OtltAsltPrssr : 48|16@1+ (0.1,0) [0|6425.5] "kPa" Vector__XXX

BO_ 2432541694 EEC6: 8 Vector__XXX
 SG_ EngnTrhrgrCmprssrBpssAttr1Cmmnd : 0|16@1+ (0.0025,0) [0|160.6375] "%" Vector__XXX
 SG_ EngnTrhrgrCmprssrBpssAttr1Pstn : 24|8@1+ (0.4,0) [0|100] "%" Vector__XXX
 SG_ EngnTrhrgrCmprssrBpssAttr2Cmmnd : 32|16@1+ (0.0025,0) [0|160.6375] "%" Vector__XXX
 SG_ EngnVrlGmtrTrhrgrAttr1 : 16|8@1+ (0.4,0) [0|100] "%" Vector__XXX
 SG_ ETCpssBpssAtt1DsdPst : 48|8@1+ (0.4,0) [0|100] "%" Vector__XXX
 SG_ ETCpssBpssAtt1PFMI : 56|5@1+ (1,0) [0|31] "binary" Vector__XXX
 SG_ ETCpssBpssAtt1TptStts : 61|3@1+ (1,0) [0|7] "" Vector__XXX

BO_ 2432593918 ACC1: 8 Vector__XXX
 SG_ ACCDistanceAlertSignal : 52|2@1+ (1,0) [0|3] "" Vector__XXX
 SG_ ACCSystemShutoffWarning : 50|2@1+ (1,0) [0|3] "" Vector__XXX
 SG_ ACCTargetDetected : 48|2@1+ (1,0) [0|3] "" Vector__XXX
 SG_ AdaptiveCruiseControlMode : 24|3@1+ (1,0) [0|7] "" Vector__XXX
 SG_ AdaptiveCruiseControlSetSpeed : 16|8@1+ (1,0) [0|250] "km/h" Vector__XXX
 SG_ Adptvrsntrlstdstnmd : 27|3@1+ (1,0) [0|7] "" Vector__XXX
 SG_ Distancetoforwardvehicle : 8|8@1+ (1,0) [0|250] "m" Vector__XXX
 SG_ ForwardCollisionWarning : 54|2@1+ (1,0) [0|3] "" Vector__XXX
 SG_ Roadcurvature : 32|16@1+ (0.0078125,-250) [-250|251.992] "1/km" Vector__XXX
 SG_ Speedofforwardvehicle : 0|8@1+ (1,0) [0|250] "km/h" Vector__XXX

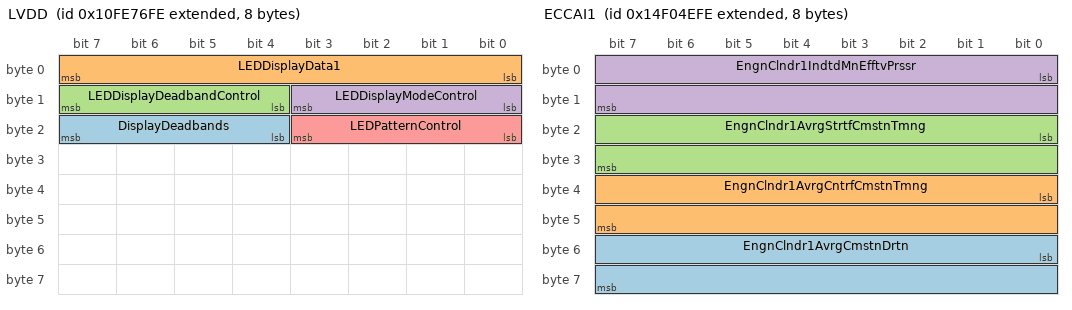
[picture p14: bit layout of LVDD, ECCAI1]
BO_ 2432595710 LVDD: 8 Vector__XXX
 SG_ DisplayDeadbands : 20|4@1+ (1,0) [0|15] "" Vector__XXX
 SG_ LEDDisplayData1 : 0|8@1+ (1,0) [0|255] "" Vector__XXX
 SG_ LEDDisplayDeadbandControl : 12|4@1+ (1,0) [0|15] "" Vector__XXX
 SG_ LEDDisplayModeControl : 8|4@1+ (1,0) [0|15] "" Vector__XXX
 SG_ LEDPatternControl : 16|4@1+ (1,0) [0|15] "" Vector__XXX

BO_ 2498776830 ECCAI1: 8 Vector__XXX
 SG_ EngnClndr1AvrgCmstnDrtn : 48|16@1+ (0.0078125,0) [0|501.99] "deg" Vector__XXX
 SG_ EngnClndr1AvrgCntrfCmstnTmng : 32|16@1+ (0.0078125,-250) [-250|250.992] "deg" Vector__XXX
 SG_ EngnClndr1AvrgStrtfCmstnTmng : 16|16@1+ (0.0078125,-250) [-250|250.992] "deg" Vector__XXX
 SG_ EngnClndr1IndtdMnEfftvPrssr : 0|16@1+ (0.0001220703125,-1) [-1|6.84362793] "MPa" Vector__XXX

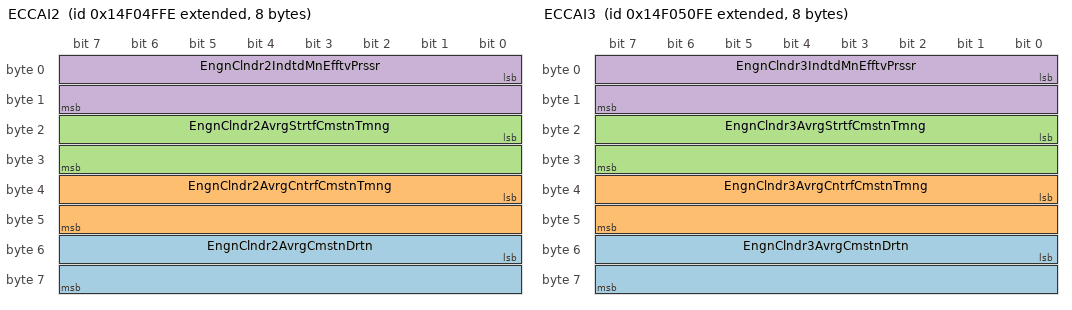
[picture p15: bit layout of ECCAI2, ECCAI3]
BO_ 2498777086 ECCAI2: 8 Vector__XXX
 SG_ EngnClndr2AvrgCmstnDrtn : 48|16@1+ (0.0078125,0) [0|501.99] "deg" Vector__XXX
 SG_ EngnClndr2AvrgCntrfCmstnTmng : 32|16@1+ (0.0078125,-250) [-250|250.992] "deg" Vector__XXX
 SG_ EngnClndr2AvrgStrtfCmstnTmng : 16|16@1+ (0.0078125,-250) [-250|250.992] "deg" Vector__XXX
 SG_ EngnClndr2IndtdMnEfftvPrssr : 0|16@1+ (0.0001220703125,-1) [-1|6.84362793] "MPa" Vector__XXX

BO_ 2498777342 ECCAI3: 8 Vector__XXX
 SG_ EngnClndr3AvrgCmstnDrtn : 48|16@1+ (0.0078125,0) [0|501.99] "deg" Vector__XXX
 SG_ EngnClndr3AvrgCntrfCmstnTmng : 32|16@1+ (0.0078125,-250) [-250|250.992] "deg" Vector__XXX
 SG_ EngnClndr3AvrgStrtfCmstnTmng : 16|16@1+ (0.0078125,-250) [-250|250.992] "deg" Vector__XXX
 SG_ EngnClndr3IndtdMnEfftvPrssr : 0|16@1+ (0.0001220703125,-1) [-1|6.84362793] "MPa" Vector__XXX

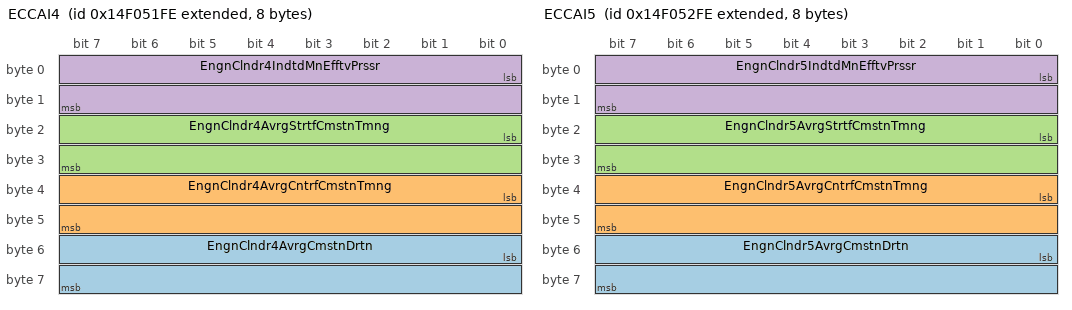
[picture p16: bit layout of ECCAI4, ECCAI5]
BO_ 2498777598 ECCAI4: 8 Vector__XXX
 SG_ EngnClndr4AvrgCmstnDrtn : 48|16@1+ (0.0078125,0) [0|501.99] "deg" Vector__XXX
 SG_ EngnClndr4AvrgCntrfCmstnTmng : 32|16@1+ (0.0078125,-250) [-250|250.992] "deg" Vector__XXX
 SG_ EngnClndr4AvrgStrtfCmstnTmng : 16|16@1+ (0.0078125,-250) [-250|250.992] "deg" Vector__XXX
 SG_ EngnClndr4IndtdMnEfftvPrssr : 0|16@1+ (0.0001220703125,-1) [-1|6.84362793] "MPa" Vector__XXX

BO_ 2498777854 ECCAI5: 8 Vector__XXX
 SG_ EngnClndr5AvrgCmstnDrtn : 48|16@1+ (0.0078125,0) [0|501.99] "deg" Vector__XXX
 SG_ EngnClndr5AvrgCntrfCmstnTmng : 32|16@1+ (0.0078125,-250) [-250|250.992] "deg" Vector__XXX
 SG_ EngnClndr5AvrgStrtfCmstnTmng : 16|16@1+ (0.0078125,-250) [-250|250.992] "deg" Vector__XXX
 SG_ EngnClndr5IndtdMnEfftvPrssr : 0|16@1+ (0.0001220703125,-1) [-1|6.84362793] "MPa" Vector__XXX

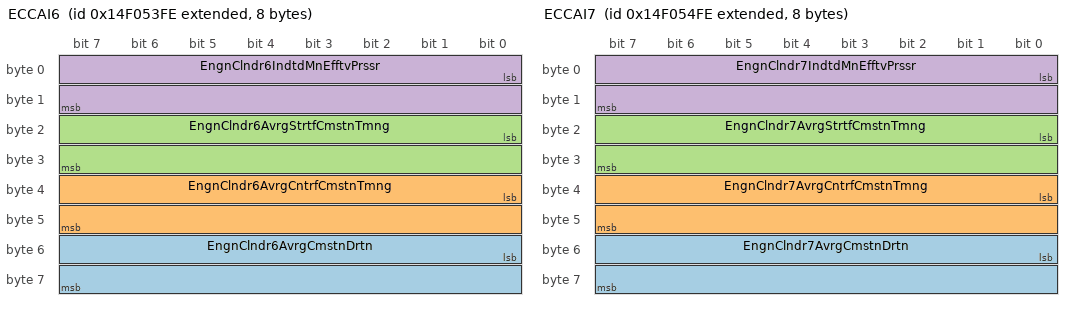
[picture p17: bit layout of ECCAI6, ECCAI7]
BO_ 2498778110 ECCAI6: 8 Vector__XXX
 SG_ EngnClndr6AvrgCmstnDrtn : 48|16@1+ (0.0078125,0) [0|501.99] "deg" Vector__XXX
 SG_ EngnClndr6AvrgCntrfCmstnTmng : 32|16@1+ (0.0078125,-250) [-250|250.992] "deg" Vector__XXX
 SG_ EngnClndr6AvrgStrtfCmstnTmng : 16|16@1+ (0.0078125,-250) [-250|250.992] "deg" Vector__XXX
 SG_ EngnClndr6IndtdMnEfftvPrssr : 0|16@1+ (0.0001220703125,-1) [-1|6.84362793] "MPa" Vector__XXX

BO_ 2498778366 ECCAI7: 8 Vector__XXX
 SG_ EngnClndr7AvrgCmstnDrtn : 48|16@1+ (0.0078125,0) [0|501.99] "deg" Vector__XXX
 SG_ EngnClndr7AvrgCntrfCmstnTmng : 32|16@1+ (0.0078125,-250) [-250|250.992] "deg" Vector__XXX
 SG_ EngnClndr7AvrgStrtfCmstnTmng : 16|16@1+ (0.0078125,-250) [-250|250.992] "deg" Vector__XXX
 SG_ EngnClndr7IndtdMnEfftvPrssr : 0|16@1+ (0.0001220703125,-1) [-1|6.84362793] "MPa" Vector__XXX

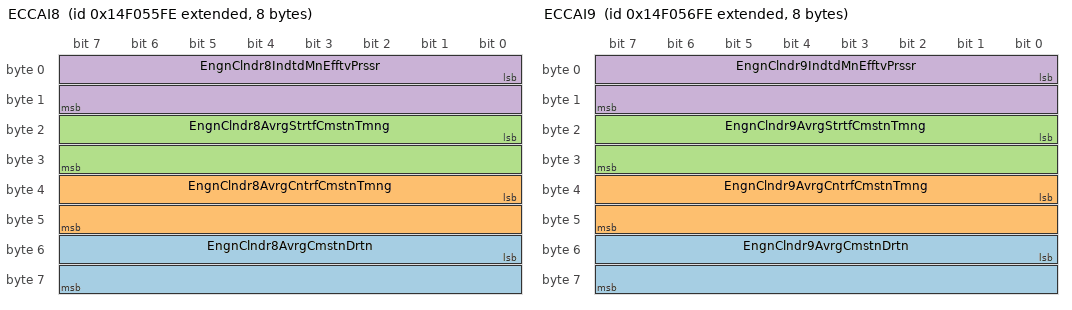
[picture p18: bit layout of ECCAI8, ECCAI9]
BO_ 2498778622 ECCAI8: 8 Vector__XXX
 SG_ EngnClndr8AvrgCmstnDrtn : 48|16@1+ (0.0078125,0) [0|501.99] "deg" Vector__XXX
 SG_ EngnClndr8AvrgCntrfCmstnTmng : 32|16@1+ (0.0078125,-250) [-250|250.992] "deg" Vector__XXX
 SG_ EngnClndr8AvrgStrtfCmstnTmng : 16|16@1+ (0.0078125,-250) [-250|250.992] "deg" Vector__XXX
 SG_ EngnClndr8IndtdMnEfftvPrssr : 0|16@1+ (0.0001220703125,-1) [-1|6.84362793] "MPa" Vector__XXX

BO_ 2498778878 ECCAI9: 8 Vector__XXX
 SG_ EngnClndr9AvrgCmstnDrtn : 48|16@1+ (0.0078125,0) [0|501.99] "deg" Vector__XXX
 SG_ EngnClndr9AvrgCntrfCmstnTmng : 32|16@1+ (0.0078125,-250) [-250|250.992] "deg" Vector__XXX
 SG_ EngnClndr9AvrgStrtfCmstnTmng : 16|16@1+ (0.0078125,-250) [-250|250.992] "deg" Vector__XXX
 SG_ EngnClndr9IndtdMnEfftvPrssr : 0|16@1+ (0.0001220703125,-1) [-1|6.84362793] "MPa" Vector__XXX

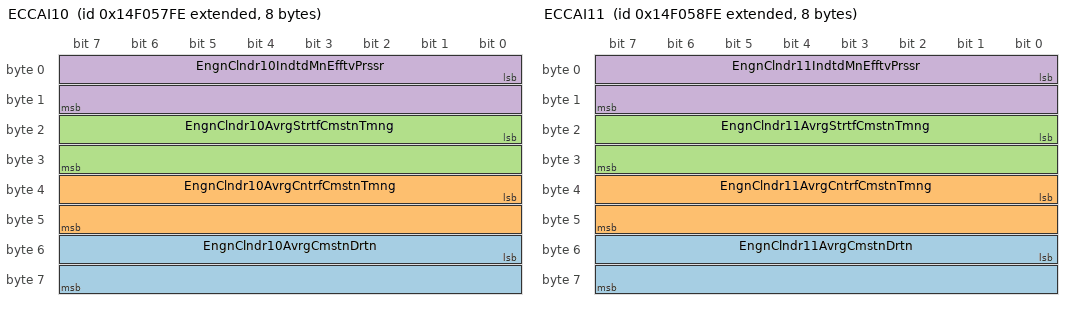
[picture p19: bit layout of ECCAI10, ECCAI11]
BO_ 2498779134 ECCAI10: 8 Vector__XXX
 SG_ EngnClndr10AvrgCmstnDrtn : 48|16@1+ (0.0078125,0) [0|501.99] "deg" Vector__XXX
 SG_ EngnClndr10AvrgCntrfCmstnTmng : 32|16@1+ (0.0078125,-250) [-250|250.992] "deg" Vector__XXX
 SG_ EngnClndr10AvrgStrtfCmstnTmng : 16|16@1+ (0.0078125,-250) [-250|250.992] "deg" Vector__XXX
 SG_ EngnClndr10IndtdMnEfftvPrssr : 0|16@1+ (0.0001220703125,-1) [-1|6.84362793] "MPa" Vector__XXX

BO_ 2498779390 ECCAI11: 8 Vector__XXX
 SG_ EngnClndr11AvrgCmstnDrtn : 48|16@1+ (0.0078125,0) [0|501.99] "deg" Vector__XXX
 SG_ EngnClndr11AvrgCntrfCmstnTmng : 32|16@1+ (0.0078125,-250) [-250|250.992] "deg" Vector__XXX
 SG_ EngnClndr11AvrgStrtfCmstnTmng : 16|16@1+ (0.0078125,-250) [-250|250.992] "deg" Vector__XXX
 SG_ EngnClndr11IndtdMnEfftvPrssr : 0|16@1+ (0.0001220703125,-1) [-1|6.84362793] "MPa" Vector__XXX

BO_ 2498779646 ECCAI12: 8 Vector__XXX
 SG_ EngnClndr12AvrgCmstnDrtn : 48|16@1+ (0.0078125,0) [0|501.99] "deg" Vector__XXX
 SG_ EngnClndr12AvrgCntrfCmstnTmng : 32|16@1+ (0.0078125,-250) [-250|250.992] "deg" Vector__XXX
 SG_ EngnClndr12AvrgStrtfCmstnTmng : 16|16@1+ (0.0078125,-250) [-250|250.992] "deg" Vector__XXX
 SG_ EngnClndr12IndtdMnEfftvPrssr : 0|16@1+ (0.0001220703125,-1) [-1|6.84362793] "MPa" Vector__XXX

BO_ 2498779902 ECCAI13: 8 Vector__XXX
 SG_ EngnClndr13AvrgCmstnDrtn : 48|16@1+ (0.0078125,0) [0|501.99] "deg" Vector__XXX
 SG_ EngnClndr13AvrgCntrfCmstnTmng : 32|16@1+ (0.0078125,-250) [-250|250.992] "deg" Vector__XXX
 SG_ EngnClndr13AvrgStrtfCmstnTmng : 16|16@1+ (0.0078125,-250) [-250|250.992] "deg" Vector__XXX
 SG_ EngnClndr13IndtdMnEfftvPrssr : 0|16@1+ (0.0001220703125,-1) [-1|6.84362793] "MPa" Vector__XXX

BO_ 2498780158 ECCAI14: 8 Vector__XXX
 SG_ EngnClndr14AvrgCmstnDrtn : 48|16@1+ (0.0078125,0) [0|501.99] "deg" Vector__XXX
 SG_ EngnClndr14AvrgCntrfCmstnTmng : 32|16@1+ (0.0078125,-250) [-250|250.992] "deg" Vector__XXX
 SG_ EngnClndr14AvrgStrtfCmstnTmng : 16|16@1+ (0.0078125,-250) [-250|250.992] "deg" Vector__XXX
 SG_ EngnClndr14IndtdMnEfftvPrssr : 0|16@1+ (0.0001220703125,-1) [-1|6.84362793] "MPa" Vector__XXX

BO_ 2498780414 ECCAI15: 8 Vector__XXX
 SG_ EngnClndr15AvrgCmstnDrtn : 48|16@1+ (0.0078125,0) [0|501.99] "deg" Vector__XXX
 SG_ EngnClndr15AvrgCntrfCmstnTmng : 32|16@1+ (0.0078125,-250) [-250|250.992] "deg" Vector__XXX
 SG_ EngnClndr15AvrgStrtfCmstnTmng : 16|16@1+ (0.0078125,-250) [-250|250.992] "deg" Vector__XXX
 SG_ EngnClndr15IndtdMnEfftvPrssr : 0|16@1+ (0.0001220703125,-1) [-1|6.84362793] "MPa" Vector__XXX

BO_ 2498780670 ECCAI16: 8 Vector__XXX
 SG_ EngnClndr16AvrgCmstnDrtn : 48|16@1+ (0.0078125,0) [0|501.99] "deg" Vector__XXX
 SG_ EngnClndr16AvrgCntrfCmstnTmng : 32|16@1+ (0.0078125,-250) [-250|250.992] "deg" Vector__XXX
 SG_ EngnClndr16AvrgStrtfCmstnTmng : 16|16@1+ (0.0078125,-250) [-250|250.992] "deg" Vector__XXX
 SG_ EngnClndr16IndtdMnEfftvPrssr : 0|16@1+ (0.0001220703125,-1) [-1|6.84362793] "MPa" Vector__XXX

BO_ 2498780926 ECCAI17: 8 Vector__XXX
 SG_ EngnClndr17AvrgCmstnDrtn : 48|16@1+ (0.0078125,0) [0|501.99] "deg" Vector__XXX
 SG_ EngnClndr17AvrgCntrfCmstnTmng : 32|16@1+ (0.0078125,-250) [-250|250.992] "deg" Vector__XXX
 SG_ EngnClndr17AvrgStrtfCmstnTmng : 16|16@1+ (0.0078125,-250) [-250|250.992] "deg" Vector__XXX
 SG_ EngnClndr17IndtdMnEfftvPrssr : 0|16@1+ (0.0001220703125,-1) [-1|6.84362793] "MPa" Vector__XXX

BO_ 2498781182 ECCAI18: 8 Vector__XXX
 SG_ EngnClndr18AvrgCmstnDrtn : 48|16@1+ (0.0078125,0) [0|501.99] "deg" Vector__XXX
 SG_ EngnClndr18AvrgCntrfCmstnTmng : 32|16@1+ (0.0078125,-250) [-250|250.992] "deg" Vector__XXX
 SG_ EngnClndr18AvrgStrtfCmstnTmng : 16|16@1+ (0.0078125,-250) [-250|250.992] "deg" Vector__XXX
 SG_ EngnClndr18IndtdMnEfftvPrssr : 0|16@1+ (0.0001220703125,-1) [-1|6.84362793] "MPa" Vector__XXX

BO_ 2498781438 ECCAI19: 8 Vector__XXX
 SG_ EngnClndr19AvrgCmstnDrtn : 48|16@1+ (0.0078125,0) [0|501.99] "deg" Vector__XXX
 SG_ EngnClndr19AvrgCntrfCmstnTmng : 32|16@1+ (0.0078125,-250) [-250|250.992] "deg" Vector__XXX
 SG_ EngnClndr19AvrgStrtfCmstnTmng : 16|16@1+ (0.0078125,-250) [-250|250.992] "deg" Vector__XXX
 SG_ EngnClndr19IndtdMnEfftvPrssr : 0|16@1+ (0.0001220703125,-1) [-1|6.84362793] "MPa" Vector__XXX

BO_ 2498781694 ECCAI20: 8 Vector__XXX
 SG_ EngnClndr20AvrgCmstnDrtn : 48|16@1+ (0.0078125,0) [0|501.99] "deg" Vector__XXX
 SG_ EngnClndr20AvrgCntrfCmstnTmng : 32|16@1+ (0.0078125,-250) [-250|250.992] "deg" Vector__XXX
 SG_ EngnClndr20AvrgStrtfCmstnTmng : 16|16@1+ (0.0078125,-250) [-250|250.992] "deg" Vector__XXX
 SG_ EngnClndr20IndtdMnEfftvPrssr : 0|16@1+ (0.0001220703125,-1) [-1|6.84362793] "MPa" Vector__XXX

CM_ BO_ 2365446142 "Extended Joystick Message 1";
CM_ SG_ 2365446142 Joystick1Button13PressedStatus "Joystick 1 Button 13 Pressed Status: Reports when the joystick button has been pressed.00b = Button not pressed01b = Button pressed10b = Error Indicator11b = Not Available";
CM_ SG_ 2365446142 Joystick1Button14PressedStatus "Joystick 1 Button 14 Pressed Status: Reports when the joystick button has been pressed.00b = Button not pressed01b = Button pressed10b = Error Indicator11b = Not Available";
CM_ SG_ 2365446142 Joystick1Button15PressedStatus "Joystick 1 Button 15 Pressed Status: Reports when the joystick button has been pressed.00b = Button not pressed01b = Button pressed10b = Error Indicator11b = Not Available";
CM_ SG_ 2365446142 Joystick1Button16PressedStatus "Joystick 1 Button 16 Pressed Status: Reports when the joystick button has been pressed.00b = Button not pressed01b = Button pressed10b = Error Indicator11b = Not Available";
CM_ SG_ 2365446142 Joystick1GripXAxisPosition "Joystick 1 Grip X-Axis Position: The position of the joystick grip in the relative motion of travel from the neutral position.  Position value of 0 is Neutral and position value 1000 (100%) is the end of linear zone.  Value of 1022 indicates an error...";
CM_ SG_ 2365446142 Joystick1GripYAxisPosition "Joystick 1 Grip Y-Axis Position: The position of the joystick grip in the relative motion of travel from the neutral position.  Position value of 0 is Neutral and position value 1000 (100%) is the end of linear zone.  Value of 1022 indicates an error...";
CM_ SG_ 2365446142 Joystick1ThetaAxisPosition "Joystick 1 Theta-Axis Position: The position of the joystick in the relative motion of travel from the neutral position.  Position value of 0 is Neutral and position value 1000 (100%) is the end of linear zone.  Value of 1022 indicates an error has o...";
CM_ SG_ 2365446142 Jst1GpYAxsLvFwdPstvPstStts "Joystick 1 Grip Y-Axis Lever Forward Positive Position Status: Reports when the current joystick grip position is on the positive travel side (forward, right, clockwise, up) relative to the neutral position for that axis of travel. 00b = Not on Posit...";
CM_ SG_ 2365446142 Jst1TtAxsCtCwsNtvPstStts "Joystick 1 Theta-Axis Counter Clockwise Negative Position Status: Reports when the current joystick position is on the negative travel side (back, left, counterclockwise, down) relative to the neutral position for that axis of travel. 00b = Not on ne...";
CM_ SG_ 2365446142 Jstk1GrpXAxsDtntPstnStts "Joystick 1 Grip X-Axis Detent Position Status: Reports when the current joystick grip position is in the detent position for that axis of travel.00b = Not in the Detent Position01b = In the Detent Position10b = Error Indicator11b = Not Available...";
CM_ SG_ 2365446142 Jstk1GrpXAxsLvrLftNgtvPstnStts "Joystick 1 Grip X-Axis Lever Left Negative Position Status: Reports when the current joystick grip position is on the negative travel side (back, left, counterclockwise, down) relative to the neutral position for that axis of travel. 00b = Not on neg...";
CM_ SG_ 2365446142 Jstk1GrpXAxsLvrRghtPstvPstnStts "Joystick 1 Grip X-Axis Lever Right Positive Position Status: Reports when the current joystick grip position is on the positive travel side (forward, right, clockwise, up) relative to the neutral position for that axis of travel. 00b = Not on Positiv...";
CM_ SG_ 2365446142 Jstk1GrpXAxsNtrlPstnStts "Joystick 1 Grip X-Axis Neutral Position Status: Reports when the current joystick grip position is in the neutral position for that axis of travel.  The neutral position measurement must be determined from some mechanism other than the axis position ...";
CM_ SG_ 2365446142 Jstk1GrpYAxsDtntPstnStts "Joystick 1 Grip Y-Axis Detent Position Status: Reports when the current joystick grip position is in the detent position for that axis of travel.00b = Not in the Detent Position01b = In the Detent Position10b = Error Indicator11b = Not Available...";
CM_ SG_ 2365446142 Jstk1GrpYAxsLvrBkNgtvPstnStts "Joystick 1 Grip Y-Axis Lever Back Negative Position Status: Reports when the current joystick grip position is on the negative travel side (back, left, counterclockwise, down) relative to the neutral position for that axis of travel. 00b = Not on neg...";
CM_ SG_ 2365446142 Jstk1GrpYAxsNtrlPstnStts "Joystick 1 Grip Y-Axis Neutral Position Status: Reports when the current joystick grip position is in the neutral position for that axis of travel.  The neutral position measurement must be determined from some mechanism other than the axis position ...";
CM_ SG_ 2365446142 Jstk1ThtAxsClkwsPstvPstnStts "Joystick 1 Theta-Axis Clockwise Positive Position Status: Reports when the current joystick position is on the positive travel side (forward, right, clockwise, up) relative to the neutral position for that axis of travel. 00b = Not on Positive side o...";
CM_ SG_ 2365446142 Jstk1ThtAxsDtntPstnStts "Joystick 1 Theta-Axis Detent Position Status: Reports when the current joystick position is in the detent position for that axis of travel.00b = Not in the Detent Position01b = In the Detent Position10b = Error Indicator11b = Not Available";
CM_ SG_ 2365446142 Jstk1ThtAxsNtrlPstnStts "Joystick 1 Theta-Axis Neutral Position Status: Reports when the current joystick position is in the neutral position for that axis of travel.  The neutral position measurement must be determined from some mechanism other than the axis position measur...";
CM_ BO_ 2365446398 "Basic Joystick Message 2";
CM_ SG_ 2365446398 Joystick2Button10PressedStatus "Joystick 2 Button 10 Pressed Status: Reports when the joystick button has been pressed.00b = Button not pressed01b = Button pressed10b = Error Indicator11b = Not Available";
CM_ SG_ 2365446398 Joystick2Button11PressedStatus "Joystick 2 Button 11 Pressed Status: Reports when the joystick button has been pressed.00b = Button not pressed01b = Button pressed10b = Error Indicator11b = Not Available";
CM_ SG_ 2365446398 Joystick2Button12PressedStatus "Joystick 2 Button 12 Pressed Status: Reports when the joystick button has been pressed.00b = Button not pressed01b = Button pressed10b = Error Indicator11b = Not Available";
CM_ SG_ 2365446398 Joystick2Button1PressedStatus "Joystick 2 Button 1 Pressed Status: Reports when the joystick button has been pressed.00b = Button not pressed01b = Button pressed10b = Error Indicator11b = Not Available";
CM_ SG_ 2365446398 Joystick2Button2PressedStatus "Joystick 2 Button 2 Pressed Status: Reports when the joystick button has been pressed.00b = Button not pressed01b = Button pressed10b = Error Indicator11b = Not Available";
CM_ SG_ 2365446398 Joystick2Button3PressedStatus "Joystick 2 Button 3 Pressed Status: Reports when the joystick button has been pressed.00b = Button not pressed01b = Button pressed10b = Error Indicator11b = Not Available";
CM_ SG_ 2365446398 Joystick2Button4PressedStatus "Joystick 2 Button 4 Pressed Status: Reports when the joystick button has been pressed.00b = Button not pressed01b = Button pressed10b = Error Indicator11b = Not Available";
CM_ SG_ 2365446398 Joystick2Button5PressedStatus "Joystick 2 Button 5 Pressed Status: Reports when the joystick button has been pressed.00b = Button not pressed01b = Button pressed10b = Error Indicator11b = Not Available";
CM_ SG_ 2365446398 Joystick2Button6PressedStatus "Joystick 2 Button 6 Pressed Status: Reports when the joystick button has been pressed.00b = Button not pressed01b = Button pressed10b = Error Indicator11b = Not Available";
CM_ SG_ 2365446398 Joystick2Button7PressedStatus "Joystick 2 Button 7 Pressed Status: Reports when the joystick button has been pressed.00b = Button not pressed01b = Button pressed10b = Error Indicator11b = Not Available";
CM_ SG_ 2365446398 Joystick2Button8PressedStatus "Joystick 2 Button 8 Pressed Status: Reports when the joystick button has been pressed.00b = Button not pressed01b = Button pressed10b = Error Indicator11b = Not Available";
CM_ SG_ 2365446398 Joystick2Button9PressedStatus "Joystick 2 Button 9 Pressed Status: Reports when the joystick button has been pressed.00b = Button not pressed01b = Button pressed10b = Error Indicator11b = Not Available";
CM_ SG_ 2365446398 Joystick2XAxisPosition "Joystick 2 X-Axis Position: The position of the joystick in the relative motion of travel from the neutral position.  Position value of 0 is Neutral and position value 1000 (100%) is the end of linear zone.  Value of 1022 indicates an error has occur...";
CM_ SG_ 2365446398 Joystick2YAxisPosition "Joystick 2 Y-Axis Position: The position of the joystick in the relative motion of travel from the neutral position.  Position value of 0 is Neutral and position value 1000 (100%) is the end of linear zone.  Value of 1022 indicates an error has occur...";
CM_ SG_ 2365446398 Jstk2XAxsDtntPstnStts "Joystick 2 X-Axis Detent Position Status: Reports when the current joystick position is in the detent position for that axis of travel.00b = Not in the Detent Position01b = In the Detent Position10b = Error Indicator11b = Not Available";
CM_ SG_ 2365446398 Jstk2XAxsLvrLftNgtvPstnStts "Joystick 2 X-Axis Lever Left Negative Position Status: Reports when the current joystick position is on the negative travel side (back, left, counterclockwise, down) relative to the neutral position for that axis of travel. 00b = Not on negative side...";
CM_ SG_ 2365446398 Jstk2XAxsLvrRghtPstvPstnStts "Joystick 2 X-Axis Lever Right Positive Position Status: Reports when the current joystick position is on the positive travel side (forward, right, clockwise, up) relative to the neutral position for that axis of travel. 00b = Not on Positive side of ...";
CM_ SG_ 2365446398 Jstk2XAxsNtrlPstnStts "Joystick 2 X-Axis Neutral Position Status: Reports when the current joystick position is in the neutral position for that axis of travel.  The neutral position measurement must be determined from some mechanism other than the axis position measuremen...";
CM_ SG_ 2365446398 Jstk2YAxsDtntPstnStts "Joystick 2 Y-Axis Detent Position Status: Reports when the current joystick position is in the detent position for that axis of travel.00b = Not in the Detent Position01b = In the Detent Position10b = Error Indicator11b = Not Available";
CM_ SG_ 2365446398 Jstk2YAxsLvrBkNgtvPstnStts "Joystick 2 Y-Axis Lever Back Negative Position Status: Reports when the current joystick position is on the negative travel side (back, left, counterclockwise, down) relative to the neutral position for that axis of travel. 00b = Not on negative side...";
CM_ SG_ 2365446398 Jstk2YAxsLvrFrwrdPstvPstnStts "Joystick 2 Y-Axis Lever Forward Positive Position Status: Reports when the current joystick position is on the positive travel side (forward, right, clockwise, up) relative to the neutral position for that axis of travel. 00b = Not on Positive side o...";
CM_ SG_ 2365446398 Jstk2YAxsNtrlPstnStts "Joystick 2 Y-Axis Neutral Position Status: Reports when the current joystick position is in the neutral position for that axis of travel.  The neutral position measurement must be determined from some mechanism other than the axis position measuremen...";
CM_ BO_ 2365446654 "Extended Joystick Message 2";
CM_ SG_ 2365446654 Joystick2Button13PressedStatus "Joystick 2 Button 13 Pressed Status: Reports when the joystick button has been pressed.00b = Button not pressed01b = Button pressed10b = Error Indicator11b = Not Available";
CM_ SG_ 2365446654 Joystick2Button14PressedStatus "Joystick 2 Button 14 Pressed Status: Reports when the joystick button has been pressed.00b = Button not pressed01b = Button pressed10b = Error Indicator11b = Not Available";
CM_ SG_ 2365446654 Joystick2Button15PressedStatus "Joystick 2 Button 15 Pressed Status: Reports when the joystick button has been pressed.00b = Button not pressed01b = Button pressed10b = Error Indicator11b = Not Available";
CM_ SG_ 2365446654 Joystick2Button16PressedStatus "Joystick 2 Button 16 Pressed Status: Reports when the joystick button has been pressed.00b = Button not pressed01b = Button pressed10b = Error Indicator11b = Not Available";
CM_ SG_ 2365446654 Joystick2GripXAxisPosition "Joystick 2 Grip X-Axis Position: The position of the joystick grip in the relative motion of travel from the neutral position.  Position value of 0 is Neutral and position value 1000 (100%) is the end of linear zone.  Value of 1022 indicates an error...";
CM_ SG_ 2365446654 Joystick2GripYAxisPosition "Joystick 2 Grip Y-Axis Position: The position of the joystick grip in the relative motion of travel from the neutral position.  Position value of 0 is Neutral and position value 1000 (100%) is the end of linear zone.  Value of 1022 indicates an error...";
CM_ SG_ 2365446654 Joystick2ThetaAxisPosition "Joystick 2 Theta-Axis Position: The position of the joystick in the relative motion of travel from the neutral position.  Position value of 0 is Neutral and position value 1000 (100%) is the end of linear zone.  Value of 1022 indicates an error has o...";
CM_ SG_ 2365446654 Jst2GpYAxsLvFwdPstvPstStts "Joystick 2 Grip Y-Axis Lever Forward Positive Position Status: Reports when the current joystick grip position is on the positive travel side (forward, right, clockwise, up) relative to the neutral position for that axis of travel. 00b = Not on Posit...";
CM_ SG_ 2365446654 Jst2TtAxsCtCwsNtvPstStts "Joystick 2 Theta-Axis Counter Clockwise Negative Position Status: Reports when the current joystick position is on the negative travel side (back, left, counterclockwise, down) relative to the neutral position for that axis of travel. 00b = Not on ne...";
CM_ SG_ 2365446654 Jstk2GrpXAxsDtntPstnStts "Joystick 2 Grip X-Axis Detent Position Status: Reports when the current joystick grip position is in the detent position for that axis of travel.00b = Not in the Detent Position01b = In the Detent Position10b = Error Indicator11b = Not Available...";
CM_ SG_ 2365446654 Jstk2GrpXAxsLvrLftNgtvPstnStts "Joystick 2 Grip X-Axis Lever Left Negative Position Status: Reports when the current joystick grip position is on the negative travel side (back, left, counterclockwise, down) relative to the neutral position for that axis of travel. 00b = Not on neg...";
CM_ SG_ 2365446654 Jstk2GrpXAxsLvrRghtPstvPstnStts "Joystick 2 Grip X-Axis Lever Right Positive Position Status: Reports when the current joystick grip position is on the positive travel side (forward, right, clockwise, up) relative to the neutral position for that axis of travel. 00b = Not on Positiv...";
CM_ SG_ 2365446654 Jstk2GrpXAxsNtrlPstnStts "Joystick 2 Grip X-Axis Neutral Position Status: Reports when the current joystick grip position is in the neutral position for that axis of travel.  The neutral position measurement must be determined from some mechanism other than the axis position ...";
CM_ SG_ 2365446654 Jstk2GrpYAxsDtntPstnStts "Joystick 2 Grip Y-Axis Detent Position Status: Reports when the current joystick grip position is in the detent position for that axis of travel.00b = Not in the Detent Position01b = In the Detent Position10b = Error Indicator11b = Not Available...";
CM_ SG_ 2365446654 Jstk2GrpYAxsLvrBkNgtvPstnStts "Joystick 2 Grip Y-Axis Lever Back Negative Position Status: Reports when the current joystick grip position is on the negative travel side (back, left, counterclockwise, down) relative to the neutral position for that axis of travel. 00b = Not on neg...";
CM_ SG_ 2365446654 Jstk2GrpYAxsNtrlPstnStts "Joystick 2 Grip Y-Axis Neutral Position Status: Reports when the current joystick grip position is in the neutral position for that axis of travel.  The neutral position measurement must be determined from some mechanism other than the axis position ...";
CM_ SG_ 2365446654 Jstk2ThtAxsClkwsPstvPstnStts "Joystick 2 Theta-Axis Clockwise Positive Position Status: Reports when the current joystick position is on the positive travel side (forward, right, clockwise, up) relative to the neutral position for that axis of travel. 00b = Not on Positive side o...";
CM_ SG_ 2365446654 Jstk2ThtAxsDtntPstnStts "Joystick 2 Theta-Axis Detent Position Status: Reports when the current joystick position is in the detent position for that axis of travel.00b = Not in the Detent Position01b = In the Detent Position10b = Error Indicator11b = Not Available";
CM_ SG_ 2365446654 Jstk2ThtAxsNtrlPstnStts "Joystick 2 Theta-Axis Neutral Position Status: Reports when the current joystick position is in the neutral position for that axis of travel.  The neutral position measurement must be determined from some mechanism other than the axis position measur...";
CM_ BO_ 2365446910 "Basic Joystick Message 3";
CM_ SG_ 2365446910 Joystick3Button10PressedStatus "Joystick 3 Button 10 Pressed Status: Reports when the joystick button has been pressed.00b = Button not pressed01b = Button pressed10b = Error Indicator11b = Not Available";
CM_ SG_ 2365446910 Joystick3Button11PressedStatus "Joystick 3 Button 11 Pressed Status: Reports when the joystick button has been pressed.00b = Button not pressed01b = Button pressed10b = Error Indicator11b = Not Available";
CM_ SG_ 2365446910 Joystick3Button12PressedStatus "Joystick 3 Button 12 Pressed Status: Reports when the joystick button has been pressed.00b = Button not pressed01b = Button pressed10b = Error Indicator11b = Not Available";
CM_ SG_ 2365446910 Joystick3Button1PressedStatus "Joystick 3 Button 1 Pressed Status: Reports when the joystick button has been pressed.00b = Button not pressed01b = Button pressed10b = Error Indicator11b = Not Available";
CM_ SG_ 2365446910 Joystick3Button2PressedStatus "Joystick 3 Button 2 Pressed Status: Reports when the joystick button has been pressed.00b = Button not pressed01b = Button pressed10b = Error Indicator11b = Not Available";
CM_ SG_ 2365446910 Joystick3Button3PressedStatus "Joystick 3 Button 3 Pressed Status: Reports when the joystick button has been pressed.00b = Button not pressed01b = Button pressed10b = Error Indicator11b = Not Available";
CM_ SG_ 2365446910 Joystick3Button4PressedStatus "Joystick 3 Button 4 Pressed Status: Reports when the joystick button has been pressed.00b = Button not pressed01b = Button pressed10b = Error Indicator11b = Not Available";
CM_ SG_ 2365446910 Joystick3Button5PressedStatus "Joystick 3 Button 5 Pressed Status: Reports when the joystick button has been pressed.00b = Button not pressed01b = Button pressed10b = Error Indicator11b = Not Available";
CM_ SG_ 2365446910 Joystick3Button6PressedStatus "Joystick 3 Button 6 Pressed Status: Reports when the joystick button has been pressed.00b = Button not pressed01b = Button pressed10b = Error Indicator11b = Not Available";
CM_ SG_ 2365446910 Joystick3Button7PressedStatus "Joystick 3 Button 7 Pressed Status: Reports when the joystick button has been pressed.00b = Button not pressed01b = Button pressed10b = Error Indicator11b = Not Available";
CM_ SG_ 2365446910 Joystick3Button8PressedStatus "Joystick 3 Button 8 Pressed Status: Reports when the joystick button has been pressed.00b = Button not pressed01b = Button pressed10b = Error Indicator11b = Not Available";
CM_ SG_ 2365446910 Joystick3Button9PressedStatus "Joystick 3 Button 9 Pressed Status: Reports when the joystick button has been pressed.00b = Button not pressed01b = Button pressed10b = Error Indicator11b = Not Available";
CM_ SG_ 2365446910 Joystick3XAxisPosition "Joystick 3 X-Axis Position: The position of the joystick in the relative motion of travel from the neutral position.  Position value of 0 is Neutral and position value 1000 (100%) is the end of linear zone.  Value of 1022 indicates an error has occur...";
CM_ SG_ 2365446910 Joystick3YAxisPosition "Joystick 3 Y-Axis Position: The position of the joystick in the relative motion of travel from the neutral position.  Position value of 0 is Neutral and position value 1000 (100%) is the end of linear zone.  Value of 1022 indicates an error has occur...";
CM_ SG_ 2365446910 Jstk3XAxsDtntPstnStts "Joystick 3 X-Axis Detent Position Status: Reports when the current joystick position is in the detent position for that axis of travel.00b = Not in the Detent Position01b = In the Detent Position10b = Error Indicator11b = Not Available";
CM_ SG_ 2365446910 Jstk3XAxsLvrLftNgtvPstnStts "Joystick 3 X-Axis Lever Left Negative Position Status: Reports when the current joystick position is on the negative travel side (back, left, counterclockwise, down) relative to the neutral position for that axis of travel. 00b = Not on negative side...";
CM_ SG_ 2365446910 Jstk3XAxsLvrRghtPstvPstnStts "Joystick 3 X-Axis Lever Right Positive Position Status: Reports when the current joystick position is on the positive travel side (forward, right, clockwise, up) relative to the neutral position for that axis of travel. 00b = Not on Positive side of ...";
CM_ SG_ 2365446910 Jstk3XAxsNtrlPstnStts "Joystick 3 X-Axis Neutral Position Status: Reports when the current joystick position is in the neutral position for that axis of travel.  The neutral position measurement must be determined from some mechanism other than the axis position measuremen...";
CM_ SG_ 2365446910 Jstk3YAxsDtntPstnStts "Joystick 3 Y-Axis Detent Position Status: Reports when the current joystick position is in the detent position for that axis of travel.00b = Not in the Detent Position01b = In the Detent Position10b = Error Indicator11b = Not Available";
CM_ SG_ 2365446910 Jstk3YAxsLvrBkNgtvPstnStts "Joystick 3 Y-Axis Lever Back Negative Position Status: Reports when the current joystick position is on the negative travel side (back, left, counterclockwise, down) relative to the neutral position for that axis of travel. 00b = Not on negative side...";
CM_ SG_ 2365446910 Jstk3YAxsLvrFrwrdPstvPstnStts "Joystick 3 Y-Axis Lever Forward Positive Position Status: Reports when the current joystick position is on the positive travel side (forward, right, clockwise, up) relative to the neutral position for that axis of travel. 00b = Not on Positive side o...";
CM_ SG_ 2365446910 Jstk3YAxsNtrlPstnStts "Joystick 3 Y-Axis Neutral Position Status: Reports when the current joystick position is in the neutral position for that axis of travel.  The neutral position measurement must be determined from some mechanism other than the axis position measuremen...";
CM_ BO_ 2365447166 "Extended Joystick Message 3";
CM_ SG_ 2365447166 Joystick3Button13PressedStatus "Joystick 3 Button 13 Pressed Status: Reports when the joystick button has been pressed.00b = Button not pressed01b = Button pressed10b = Error Indicator11b = Not Available";
CM_ SG_ 2365447166 Joystick3Button14PressedStatus "Joystick 3 Button 14 Pressed Status: Reports when the joystick button has been pressed.00b = Button not pressed01b = Button pressed10b = Error Indicator11b = Not Available";
CM_ SG_ 2365447166 Joystick3Button15PressedStatus "Joystick 3 Button 15 Pressed Status: Reports when the joystick button has been pressed.00b = Button not pressed01b = Button pressed10b = Error Indicator11b = Not Available";
CM_ SG_ 2365447166 Joystick3Button16PressedStatus "Joystick 3 Button 16 Pressed Status: Reports when the joystick button has been pressed.00b = Button not pressed01b = Button pressed10b = Error Indicator11b = Not Available";
CM_ SG_ 2365447166 Joystick3GripXAxisPosition "Joystick 3 Grip X-Axis Position: The position of the joystick grip in the relative motion of travel from the neutral position.  Position value of 0 is Neutral and position value 1000 (100%) is the end of linear zone.  Value of 1022 indicates an error...";
CM_ SG_ 2365447166 Joystick3GripYAxisPosition "Joystick 3 Grip Y-Axis Position: The position of the joystick grip in the relative motion of travel from the neutral position.  Position value of 0 is Neutral and position value 1000 (100%) is the end of linear zone.  Value of 1022 indicates an error...";
CM_ SG_ 2365447166 Joystick3ThetaAxisPosition "Joystick 3 Theta-Axis Position: The position of the joystick in the relative motion of travel from the neutral position.  Position value of 0 is Neutral and position value 1000 (100%) is the end of linear zone.  Value of 1022 indicates an error has o...";
CM_ SG_ 2365447166 Jst3GpYAxsLvFwdPstvPstStts "Joystick 3 Grip Y-Axis Lever Forward Positive Position Status: Reports when the current joystick grip position is on the positive travel side (forward, right, clockwise, up) relative to the neutral position for that axis of travel. 00b = Not on Posit...";
CM_ SG_ 2365447166 Jst3TtAxsCtCwsNtvPstStts "Joystick 3 Theta-Axis Counter Clockwise Negative Position Status: Reports when the current joystick position is on the negative travel side (back, left, counterclockwise, down) relative to the neutral position for that axis of travel. 00b = Not on ne...";
CM_ SG_ 2365447166 Jstk3GrpXAxsDtntPstnStts "Joystick 3 Grip X-Axis Detent Position Status: Reports when the current joystick grip position is in the detent position for that axis of travel.00b = Not in the Detent Position01b = In the Detent Position10b = Error Indicator11b = Not Available...";
CM_ SG_ 2365447166 Jstk3GrpXAxsLvrLftNgtvPstnStts "Joystick 3 Grip X-Axis Lever Left Negative Position Status: Reports when the current joystick grip position is on the negative travel side (back, left, counterclockwise, down) relative to the neutral position for that axis of travel. 00b = Not on neg...";
CM_ SG_ 2365447166 Jstk3GrpXAxsLvrRghtPstvPstnStts "Joystick 3 Grip X-Axis Lever Right Positive Position Status: Reports when the current joystick grip position is on the positive travel side (forward, right, clockwise, up) relative to the neutral position for that axis of travel. 00b = Not on Positiv...";
CM_ SG_ 2365447166 Jstk3GrpXAxsNtrlPstnStts "Joystick 3 Grip X-Axis Neutral Position Status: Reports when the current joystick grip position is in the neutral position for that axis of travel.  The neutral position measurement must be determined from some mechanism other than the axis position ...";
CM_ SG_ 2365447166 Jstk3GrpYAxsDtntPstnStts "Joystick 3 Grip Y-Axis Detent Position Status: Reports when the current joystick grip position is in the detent position for that axis of travel.00b = Not in the Detent Position01b = In the Detent Position10b = Error Indicator11b = Not Available...";
CM_ SG_ 2365447166 Jstk3GrpYAxsLvrBkNgtvPstnStts "Joystick 3 Grip Y-Axis Lever Back Negative Position Status: Reports when the current joystick grip position is on the negative travel side (back, left, counterclockwise, down) relative to the neutral position for that axis of travel. 00b = Not on neg...";
CM_ SG_ 2365447166 Jstk3GrpYAxsNtrlPstnStts "Joystick 3 Grip Y-Axis Neutral Position Status: Reports when the current joystick grip position is in the neutral position for that axis of travel.  The neutral position measurement must be determined from some mechanism other than the axis position ...";
CM_ SG_ 2365447166 Jstk3ThtAxsClkwsPstvPstnStts "Joystick 3 Theta-Axis Clockwise Positive Position Status: Reports when the current joystick position is on the positive travel side (forward, right, clockwise, up) relative to the neutral position for that axis of travel. 00b = Not on Positive side o...";
CM_ SG_ 2365447166 Jstk3ThtAxsDtntPstnStts "Joystick 3 Theta-Axis Detent Position Status: Reports when the current joystick position is in the detent position for that axis of travel.00b = Not in the Detent Position01b = In the Detent Position10b = Error Indicator11b = Not Available";
CM_ SG_ 2365447166 Jstk3ThtAxsNtrlPstnStts "Joystick 3 Theta-Axis Neutral Position Status: Reports when the current joystick position is in the neutral position for that axis of travel.  The neutral position measurement must be determined from some mechanism other than the axis position measur...";
CM_ BO_ 2365449982 "Hydraulic Braking System";
CM_ SG_ 2365449982 HdrlBrkPrssrSpplSttCrt1 "Hydraulic Brake Pressure Supply State Circuit 1: Signal which indicates whether the hydraulic brake pressure supply of circuit 1 is reliable; that is, able to support continued braking.00b = Supply is not reliable01b = Supply is reliable10b = Error i...";
CM_ SG_ 2365449982 HdrlBrkPrssrSpplSttCrt2 "Hydraulic Brake Pressure Supply State Circuit 2: Signal which indicates whether the hydraulic brake pressure supply of circuit 2 is reliable; that is, able to support continued braking.00b = Supply is not reliable01b = Supply is reliable10b = Error i...";
CM_ SG_ 2365449982 HdrlBrkPrssrWrnngSttCrt1 "Hydraulic Brake Pressure Warning State Circuit 1: Signal which indicates whether the hydraulic brake pressure of circuit 1 is below the warning level00b = Pressure level sufficient01b = Pressure level below warning level10b = Error indicator11b = Not...";
CM_ SG_ 2365449982 HdrlBrkPrssrWrnngSttCrt2 "Hydraulic Brake Pressure Warning State Circuit 2: Signal which indicates whether the hydraulic brake pressure of circuit 2 is below the warning level00b = Pressure level sufficient01b = Pressure level below warning level10b = Error indicator11b = Not...";
CM_ SG_ 2365449982 HdrlBrkSstmAdlWrnngCmmnd "Hydraulic Brake System Audible Warning Command: Signal which commands an audible warning by the hydraulic braking system.00b = Audible warning off01b = Audible warning on10b = Reserved11b = Don't care";
CM_ SG_ 2365449982 HydraulicBrakeFluidLevelSwitch "Hydraulic Brake Fluid Level Switch: Signal which indicates whether the hydraulic fluid level in the reservoir(s) is sufficient.00b = Fluid level is not sufficient01b = Fluid level is sufficient10b = Error indicator11b = Not available";
CM_ SG_ 2365449982 HydraulicBrakePressureCircuit1 "Hydraulic Brake Pressure Circuit 1: Gage hydraulic pressure in circuit 1 of the hydraulic brake system";
CM_ SG_ 2365449982 HydraulicBrakePressureCircuit2 "Hydraulic Brake Pressure Circuit 2: Gage hydraulic pressure in circuit 2 of the hydraulic brake system";
CM_ BO_ 2365450238 "Bus #1/Utility Sync Check Status";
CM_ SG_ 2365450238 Bus1UtilityACPhaseDifference "Bus #1/Utility AC Phase Difference: The phase difference between the Bus #1 voltage and Utility voltage.";
CM_ SG_ 2365450238 Bus1UtilityDeadBus "Bus #1/Utility Dead Bus: Indicator of whether Bus #1 is considered dead for closing to the utility. This indicator will be based on parameters such as Bus #1 Voltage and dead bus threshold values.00b = Bus is not dead01b = Bus is dead10b = Error11b =...";
CM_ SG_ 2365450238 Bus1UtilityFrequencyMatch "Bus #1/Utility Frequency Match: Indicator of whether frequency difference between Bus #1 and Utility is adequate for paralleling. This indicator will be based on the measured AC frequencies qualified using parameters such as Frequency Tolerance, Phas...";
CM_ SG_ 2365450238 Bus1UtilityInSync "Bus #1/Utility In Sync: Indicator of whether Bus #1 and Utility are properly synchronized for paralleling. This indicator will be based on parameters such as Voltage Match, Frequency Match, and Phase Match.00b = Not synchronized01b = Synchronized10b ...";
CM_ SG_ 2365450238 Bus1UtilityPhaseMatch "Bus #1/Utility Phase Match: Indicator of whether phase difference between Bus #1 and Utility is adequate for paralleling. This indicator will be based on the measured AC phase difference qualified using parameters such as Phase Tolerance and Dwell Ti...";
CM_ SG_ 2365450238 Bus1UtilityVoltageMatch "Bus #1/Utility Voltage Match: Indicator of whether voltage difference between Bus #1 and Utility is adequate for paralleling. This indicator will be based on the measured AC voltages qualified using parameters such as Voltage Tolerance.00b = Voltages...";
CM_ BO_ 2365450494 "Bus #1/Generator Sync Check Status";
CM_ SG_ 2365450494 Bus1GeneratorACPhaseDifference "Bus #1/Generator AC Phase Difference: The phase difference between the Bus #1 voltage and Generator voltage.";
CM_ SG_ 2365450494 Bus1GeneratorDeadBus "Bus #1/Generator Dead Bus: Indicator of whether Bus #1 is considered dead for closing to the generator. This indicator will be based on parameters such as Bus #1 Voltage and dead bus threshold values.00b = Bus is not dead01b = Bus is dead10b = Error1...";
CM_ SG_ 2365450494 Bus1GeneratorFrequencyMatch "Bus #1/Generator Frequency Match: Indicator of whether frequency difference between Bus #1 and Generator is adequate for paralleling. This indicator will be based on the measured AC frequencies qualified using parameters such as Frequency Tolerance, ...";
CM_ SG_ 2365450494 Bus1GeneratorInSync "Bus #1/Generator In Sync: Indicator of whether Bus #1 and Generator are properly synchronized for paralleling. This indicator will be based on parameters such as Voltage Match, Frequency Match, and Phase Match.00b = Not synchronized01b = Synchronized...";
CM_ SG_ 2365450494 Bus1GeneratorPhaseMatch "Bus #1/Generator Phase Match: Indicator of whether phase difference between Bus #1 and Generator is adequate for paralleling. This indicator will be based on the measured AC phase difference qualified using parameters such as Phase Tolerance and Dwel...";
CM_ SG_ 2365450494 Bus1GeneratorVoltageMatch "Bus #1/Generator Voltage Match: Indicator of whether voltage difference between Bus #1 and Generator is adequate for paralleling. This indicator will be based on the measured AC voltages qualified using parameters such as Voltage Tolerance.00b = Volt...";
CM_ BO_ 2365450750 "Bus #1 Phase C  Basic AC Quantities";
CM_ SG_ 2365450750 Bs1PhsCLnNtrlACRMSVltg "Bus #1 Phase C Line-Neutral AC RMS Voltage: Line to Neutral RMS voltage measured at bus #1 phase C.";
CM_ SG_ 2365450750 Bus1PhaseCACFrequency "Bus #1 Phase C AC Frequency: AC frequency measured at bus #1 phase C.";
CM_ SG_ 2365450750 Bus1PhaseCALineLineACRMSVoltage "Bus #1 Phase CA Line-Line AC RMS Voltage: Line to Line RMS voltage measured at bus #1 phase CA.";
CM_ BO_ 2365451006 "Bus #1 Phase B  Basic AC Quantities";
CM_ SG_ 2365451006 Bs1PhsBLnNtrlACRMSVltg "Bus #1 Phase B Line-Neutral AC RMS Voltage: Line to Neutral RMS voltage measured at bus #1 phase B.";
CM_ SG_ 2365451006 Bus1PhaseBACFrequency "Bus #1 Phase B AC Frequency: AC frequency measured at bus #1 phase B.";
CM_ SG_ 2365451006 Bus1PhaseBCLineLineACRMSVoltage "Bus #1 Phase BC Line-Line AC RMS Voltage: Line to Line RMS voltage measured at bus #1 phase BC.";
CM_ BO_ 2365451262 "Bus #1 Phase A  Basic AC Quantities";
CM_ SG_ 2365451262 Bs1PhsALnNtrlACRMSVltg "Bus #1 Phase A Line-Neutral AC RMS Voltage: Line to Neutral RMS voltage measured at bus #1 phase A.";
CM_ SG_ 2365451262 Bus1PhaseAACFrequency "Bus #1 Phase A AC Frequency: AC frequency measured at bus #1 phase A.";
CM_ SG_ 2365451262 Bus1PhaseABLineLineACRMSVoltage "Bus #1 Phase AB Line-Line AC RMS Voltage: Line to Line RMS voltage measured at bus #1 phase AB.";
CM_ BO_ 2365451518 "Bus #1 Average Basic AC Quantities";
CM_ SG_ 2365451518 Bs1AvrgLnNtrlACRMSVltg "Bus #1 Average Line-Neutral AC RMS Voltage: The average Line to Neutral AC RMS voltage measured at bus #1 .";
CM_ SG_ 2365451518 Bus1AverageACFrequency "Bus #1 Average AC Frequency: Average AC frequency measured at bus #1.";
CM_ SG_ 2365451518 Bus1AverageLineLineACRMSVoltage "Bus #1 Average Line-Line AC RMS Voltage: Average Line to Line RMS voltage measured at bus #1 .";
CM_ BO_ 2365451774 "Utility Total AC Energy";
CM_ SG_ 2365451774 UtilityTotalkWHoursExport "Utility Total kW Hours Export: The total kilowatt-hours that have been exported by the utility incomer.";
CM_ SG_ 2365451774 UtilityTotalkWHoursImport "Utility Total kW Hours Import: The total kilowatt-hours that have been imported by the utility incomer.";
CM_ BO_ 2365452030 "Utility Phase C AC Reactive Power";
CM_ SG_ 2365452030 UtilityPhaseCPowerFactor "Utility Phase C Power Factor: The power factor of phases C of the utility incomer.";
CM_ SG_ 2365452030 UtilityPhaseCPowerFactorLagging "Utility Phase C Power Factor Lagging: Lead/lag status for utility incomer phase C power factor.00b = Leading01b = Lagging10b = Error11b = Not Available or Not Installed";
CM_ SG_ 2365452030 UtilityPhaseCReactivePower "Utility Phase C Reactive Power: The reactive power delivered by phase C of the utility incomer";
CM_ BO_ 2365452286 "Utility Phase C AC Power";
CM_ SG_ 2365452286 UtilityPhaseCApparentPower "Utility Phase C Apparent Power: The apparent power delivered by phase C of the utility incomer.";
CM_ SG_ 2365452286 UtilityPhaseCRealPower "Utility Phase C Real Power: The real power delivered by phase C of the utility incomer.";
CM_ BO_ 2365452542 "Utility Phase C AC Basic Quantities";
CM_ SG_ 2365452542 UtilityPhaseCACFrequency "Utility Phase C AC Frequency: AC frequency measured at the utility incomer phase C.";
CM_ SG_ 2365452542 UtilityPhaseCACRMSCurrent "Utility Phase C AC RMS Current: RMS current measured at the utility incomer phase C.";
CM_ SG_ 2365452542 UtltPhsCALnLnACRMSVltg "Utility Phase CA Line-Line AC RMS Voltage: Line to Line RMS voltage measured at the utility incomer phase CA.";
CM_ SG_ 2365452542 UtltPhsCLnNtrlACRMSVltg "Utility Phase C Line-Neutral AC RMS Voltage: Line to Neutral RMS voltage measured at the utility incomer phase C.";
CM_ BO_ 2365452798 "Utility Phase B AC Reactive Power";
CM_ SG_ 2365452798 UtilityPhaseBPowerFactor "Utility Phase B Power Factor: The power factor of phases B of the utility incomer.";
CM_ SG_ 2365452798 UtilityPhaseBPowerFactorLagging "Utility Phase B Power Factor Lagging: Lead/lag status for utility incomer phase B power factor.00b = Leading01b = Lagging10b = Error11b = Not Available or Not Installed";
CM_ SG_ 2365452798 UtilityPhaseBReactivePower "Utility Phase B Reactive Power: The reactive power delivered by phase B of the utility incomer";
CM_ BO_ 2365453054 "Utility Phase B AC Power";
CM_ SG_ 2365453054 UtilityPhaseBApparentPower "Utility Phase B Apparent Power: The apparent power delivered by phase B of the utility incomer.";
CM_ SG_ 2365453054 UtilityPhaseBRealPower "Utility Phase B Real Power: The real power delivered by phase B of the utility incomer.";
CM_ BO_ 2365453310 "Utility Phase B AC Basic Quantities";
CM_ SG_ 2365453310 UtilityPhaseBACFrequency "Utility Phase B AC Frequency: AC frequency measured at the utility incomer phase B.";
CM_ SG_ 2365453310 UtilityPhaseBACRMSCurrent "Utility Phase B AC RMS Current: RMS current measured at the utility incomer phase B.";
CM_ SG_ 2365453310 UtltPhsBCLnLnACRMSVltg "Utility Phase BC Line-Line AC RMS Voltage: Line to Line RMS voltage measured at the utility incomer phase BC.";
CM_ SG_ 2365453310 UtltPhsBLnNtrlACRMSVltg "Utility Phase B Line-Neutral AC RMS Voltage: Line to Neutral RMS voltage measured at the utility incomer phase B.";
CM_ BO_ 2365453566 "Utility Phase A AC Reactive Power";
CM_ SG_ 2365453566 UtilityPhaseAPowerFactor "Utility Phase A Power Factor: The power factor of phase A of the utility incomer.";
CM_ SG_ 2365453566 UtilityPhaseAPowerFactorLagging "Utility Phase A Power Factor Lagging: Lead/lag status for utility incomer phase A power factor.00b = Leading01b = Lagging10b = Error11b = Not Available or Not Installed";
CM_ SG_ 2365453566 UtilityPhaseAReactivePower "Utility Phase A Reactive Power: The reactive power delivered by phase A of the utility incomer";
CM_ BO_ 2365453822 "Utility Phase A AC Power";
CM_ SG_ 2365453822 UtilityPhaseAApparentPower "Utility Phase A Apparent Power: The apparent power delivered by phase A of the utility incomer.";
CM_ SG_ 2365453822 UtilityPhaseARealPower "Utility Phase A Real Power: The real power delivered by phase A of the utility incomer.";
CM_ BO_ 2365454078 "Utility Phase A Basic AC Quantities";
CM_ SG_ 2365454078 UtilityPhaseAACFrequency "Utility Phase A AC Frequency: AC frequency measured at the utility incomer phase A.";
CM_ SG_ 2365454078 UtilityPhaseAACRMSCurrent "Utility Phase A AC RMS Current: RMS current measured at the utility incomer phase A.";
CM_ SG_ 2365454078 UtltPhsABLnLnACRMSVltg "Utility Phase AB Line-Line AC RMS Voltage: Line to Line RMS voltage measured at the utility incomer phase AB.";
CM_ SG_ 2365454078 UtltPhsALnNtrlACRMSVltg "Utility Phase A Line-Neutral AC RMS Voltage: Line to Neutral RMS voltage measured at the utility incomer phase A.";
CM_ BO_ 2365454334 "Utility Total AC Reactive Power";
CM_ SG_ 2365454334 UtilityOverallPowerFactor "Utility Overall Power Factor: The average power factor of the utility incomer.";
CM_ SG_ 2365454334 UtilityTotalReactivePower "Utility Total Reactive Power: The total reactive power delivered by the utility incomer";
CM_ SG_ 2365454334 UtltOvrllPwrFtrLggng "Utility Overall Power Factor Lagging: Lead/lag status for utility incomer average power factor.00b = Leading01b = Lagging10b = Error11b = Not Available or Not Installed";
CM_ BO_ 2365454590 "Utility Total AC Power";
CM_ SG_ 2365454590 UtilityTotalApparentPower "Utility Total Apparent Power: The total apparent power delivered by the utility incomer.";
CM_ SG_ 2365454590 UtilityTotalRealPower "Utility Total Real Power: Total real power delivered by the utility incomer.";
CM_ BO_ 2365454846 "Utility Average Basic AC Quantities";
CM_ SG_ 2365454846 UtilityAverageACFrequency "Utility Average AC Frequency: Average AC frequency measured at the utility incomer.";
CM_ SG_ 2365454846 UtilityAverageACRMSCurrent "Utility Average AC RMS Current: Average RMS current measured at the utility incomer.";
CM_ SG_ 2365454846 UtltAvrgLnLnACRMSVltg "Utility Average Line-Line AC RMS Voltage: Average Line to Line RMS voltage measured at the utility incomer .";
CM_ SG_ 2365454846 UtltAvrgLnNtrlACRMSVltg "Utility Average Line-Neutral AC RMS Voltage: The average Line to Neutral AC RMS voltage measured at the utility incomer .";
CM_ BO_ 2365455102 "Generator Total AC Energy";
CM_ SG_ 2365455102 GeneratorTotalkWHoursExport "Generator Total kW Hours Export: The total kilowatt-hours that have been exported by the generator.";
CM_ SG_ 2365455102 GeneratorTotalkWHoursImport "Generator Total kW Hours Import: The total kilowatt-hours that have been imported by the generator.";
CM_ BO_ 2365455358 "Generator Phase C AC Reactive Power";
CM_ SG_ 2365455358 GeneratorPhaseCPowerFactor "Generator Phase C Power Factor: The power factor of phases C of the generator.";
CM_ SG_ 2365455358 GeneratorPhaseCReactivePower "Generator Phase C Reactive Power: The reactive power delivered by phase C of the generator";
CM_ SG_ 2365455358 GnrtrPhsCPwrFtrLggng "Generator Phase C Power Factor Lagging: Lead/lag status for generator phase C power factor.00b = Leading01b = Lagging10b = Error11b = Not Available or Not Installed";
CM_ BO_ 2365455614 "Generator Phase C AC Power";
CM_ SG_ 2365455614 GeneratorPhaseCApparentPower "Generator Phase C Apparent Power: The apparent power delivered by phase C of the generator.";
CM_ SG_ 2365455614 GeneratorPhaseCRealPower "Generator Phase C Real Power: The real power delivered by phase C of the generator.";
CM_ BO_ 2365455870 "Generator Phase C Basic AC Quantities";
CM_ SG_ 2365455870 GeneratorPhaseCACFrequency "Generator Phase C AC Frequency: AC frequency measured at the generator phase C output.";
CM_ SG_ 2365455870 GeneratorPhaseCACRMSCurrent "Generator Phase C AC RMS Current: RMS current measured at the generator phase C output.";
CM_ SG_ 2365455870 GnrtrPhsCALnLnACRMSVltg "Generator Phase CA Line-Line AC RMS Voltage: Line to Line RMS voltage measured at the generator phase CA output.";
CM_ SG_ 2365455870 GnrtrPhsCLnNtrlACRMSVltg "Generator Phase C Line-Neutral AC RMS Voltage: Line to Neutral RMS voltage measured at the generator phase C output.";
CM_ BO_ 2365456126 "Generator Phase B AC Reactive Power";
CM_ SG_ 2365456126 GeneratorPhaseBPowerFactor "Generator Phase B Power Factor: The power factor of phases B of the generator.";
CM_ SG_ 2365456126 GeneratorPhaseBReactivePower "Generator Phase B Reactive Power: The reactive power delivered by phase B of the generator";
CM_ SG_ 2365456126 GnrtrPhsBPwrFtrLggng "Generator Phase B Power Factor Lagging: Lead/lag status for generator phase B power factor.00b = Leading01b = Lagging10b = Error11b = Not Available or Not Installed";
CM_ BO_ 2365456382 "Generator Phase B AC Power";
CM_ SG_ 2365456382 GeneratorPhaseBApparentPower "Generator Phase B Apparent Power: The apparent power delivered by phase B of the generator.";
CM_ SG_ 2365456382 GeneratorPhaseBRealPower "Generator Phase B Real Power: The real power delivered by phase B of the generator.";
CM_ BO_ 2365456894 "Generator Phase A AC Reactive Power";
CM_ SG_ 2365456894 GeneratorPhaseAPowerFactor "Generator Phase A Power Factor: The power factor of phase A of the generator.";
CM_ SG_ 2365456894 GeneratorPhaseAReactivePower "Generator Phase A Reactive Power: The reactive power delivered by phase A of the generator";
CM_ SG_ 2365456894 GnrtrPhsAPwrFtrLggng "Generator Phase A Power Factor Lagging: Lead/lag status for generator phase A power factor.00b = Leading01b = Lagging10b = Error11b = Not Available or Not Installed";
CM_ BO_ 2365457150 "Generator Phase A AC Power";
CM_ SG_ 2365457150 GeneratorPhaseAApparentPower "Generator Phase A Apparent Power: The apparent power delivered by phase A of the generator.";
CM_ SG_ 2365457150 GeneratorPhaseARealPower "Generator Phase A Real Power: The real power delivered by phase A of the generator.";
CM_ BO_ 2365457406 "Generator Phase A Basic AC Quantities";
CM_ SG_ 2365457406 GeneratorPhaseAACFrequency "Generator Phase A AC Frequency: AC frequency measured at the generator phase A output.";
CM_ SG_ 2365457406 GeneratorPhaseAACRMSCurrent "Generator Phase A AC RMS Current: RMS current measured at the generator phase A output.";
CM_ SG_ 2365457406 GnrtrPhsABLnLnACRMSVltg "Generator Phase AB Line-Line AC RMS Voltage: Line to Line RMS voltage measured at the generator phase AB output.";
CM_ SG_ 2365457406 GnrtrPhsALnNtrlACRMSVltg "Generator Phase A Line-Neutral AC RMS Voltage: Line to Neutral RMS voltage measured at the generator phase A output.";
CM_ BO_ 2365457662 "Generator Total AC Reactive Power";
CM_ SG_ 2365457662 GeneratorOverallPowerFactor "Generator Overall Power Factor: The average power factor of the generator.";
CM_ SG_ 2365457662 GeneratorTotalReactivePower "Generator Total Reactive Power: The total reactive power delivered by the generator";
CM_ SG_ 2365457662 GnrtrOvrllPwrFtrLggng "Generator Overall Power Factor Lagging: Lead/lag status for generator average power factor.00b = Leading01b = Lagging10b = Error11b = Not Available or Not Installed";
CM_ BO_ 2365457918 "Generator Total AC Power";
CM_ SG_ 2365457918 GeneratorTotalApparentPower "Generator Total Apparent Power: The total apparent power delivered by the generator.";
CM_ SG_ 2365457918 GeneratorTotalRealPower "Generator Total Real Power: Total real power delivered by the generator.";
CM_ BO_ 2365458174 "Generator Average Basic AC Quantities";
CM_ SG_ 2365458174 GeneratorAverageACFrequency "Generator Average AC Frequency: Average AC frequency measured at the generator output.";
CM_ SG_ 2365458174 GeneratorAverageACRMSCurrent "Generator Average AC RMS Current: Average RMS current measured at the generator output.";
CM_ SG_ 2365458174 GnrtrAvrgLnLnACRMSVltg "Generator Average Line-Line AC RMS Voltage: Average Line to Line RMS voltage measured at the generator output.";
CM_ SG_ 2365458174 GnrtrAvrgLnNtrlACRMSVltg "Generator Average Line-Neutral AC RMS Voltage: The average Line to Neutral AC RMS voltage measured at the Generator output.";
CM_ BO_ 2365473278 "Lighting Command";
CM_ SG_ 2365473278 AlternateBeamHeadLightCommand "Alternate Beam Head Light Command: Command to activate or de-activate the tractor alternate head lights (only low beam is available on alternate head lights).  The alternate position lights are intended for use with loader and snow plows that tend to...";
CM_ SG_ 2365473278 BackUpLightandAlarmHornCommand "Back Up Light and Alarm Horn Command: Command to activate or de-activate the back up lights and/ or associated alarm if required00b = De-activate01b = Activate10b = Reserved11b = Don't Care";
CM_ SG_ 2365473278 CenterStopLightCommand "Center Stop Light Command: Command to activate or de-activate the tractor and implement center stop light00b = De-activate01b = Activate10b = Reserved11b = Don't Care";
CM_ SG_ 2365473278 HighBeamHeadLightCommand "High Beam Head Light Command: Command to activate or de-activate the tractor high beam head light lamps. 00b = De-activate01b = Activate10b = Reserved11b = Don't Care";
CM_ SG_ 2365473278 ImplementClearanceLightCommand "Implement Clearance Light Command: Command to activate or de-activate the implement high mounted clearance and lights.  00b = De-activate01b = Activate10b = Reserved11b = Don't Care";
CM_ SG_ 2365473278 ImplementMarkerLightCommand "Implement Marker Light Command: Command to activate or de-activate implement front position lights, rear red tail lights, side amber running lights, license plate lights and instrument and switch back lights.  00b = De-activate01b = Activate10b = Res...";
CM_ SG_ 2365473278 ImplementOEMOption1LightCommand "Implement OEM Option 1 Light Command: Command to activate or de-activate an implement OEM option 1 light.  This is provided to meet special needs on implements, such as tank inspection or filling lights.00b = De-activate01b = Activate10b = Reserved11...";
CM_ SG_ 2365473278 ImplementOEMOption2LightCommand "Implement OEM Option 2 Light Command: Command to activate or de-activate an implement OEM option 2 light.  This is provided to meet special needs on implements, such as tank inspection or filling lights.00b = De-activate01b = Activate10b = Reserved11...";
CM_ SG_ 2365473278 ImplementRearWorkLightCommand "Implement Rear Work Light Command: Command to activate or de-activate implement rear work lights.  (This is also the same as Reversing Lights for truck applications.)  00b = De-activate01b = Activate10b = Reserved11b = Don't Care";
CM_ SG_ 2365473278 ImplmntLftFngWrkLghtCmmnd "Implement Left Facing Work Light Command: Command to activate or de-activate the left facing work lights toward the left end of the implement.00b = De-activate01b = Activate10b = Reserved11b = Don't Care";
CM_ SG_ 2365473278 ImplmntLftFrwrdWrkLghtCmmnd "Implement Left Forward Work Light Command: Command to activate or de-activate work lights mounted on an implement to illuminate beyond left end of the implement.00b = De-activate01b = Activate10b = Reserved11b = Don't Care";
CM_ SG_ 2365473278 ImplmntRghtFngWrkLghtCmmnd "Implement Right Facing Work Light Command: Command to activate or de-activate work lights mounted on an implement to illuminate beyond right end of the implement.00b = De-activate01b = Activate10b = Reserved11b = Don't Care";
CM_ SG_ 2365473278 ImplmntRghtFrwrdWrkLghtCmmnd "Implement Right Forward Work Light Command: Command to activate or de-activate the forward facing work lights toward the right end of the implement.00b = De-activate01b = Activate10b = Reserved11b = Don't Care";
CM_ SG_ 2365473278 LeftStopLightCommand "Left Stop Light Command: Command to activate or de-activate the tractor and implement left stop lights00b = De-activate01b = Activate10b = Reserved11b = Don't Care";
CM_ SG_ 2365473278 LeftTurnSignalLightsCommand "Left Turn Signal Lights Command: Command to activate or de-activate left turn signal lights on the tractor and all connected implements00b = De-activate01b = Activate10b = Reserved11b = Don't Care";
CM_ SG_ 2365473278 LightingDataRequestCommand "Lighting Data Request Command: Command to provide a response of the light state00b = De-activate01b = Activate10b = Reserved11b = Don't Care";
CM_ SG_ 2365473278 LowBeamHeadLightCommand "Low Beam Head Light Command: Command to activate or de-activate the tractor low beam head light lamps. 00b = De-activate01b = Activate10b = Reserved11b = Don't Care";
CM_ SG_ 2365473278 RearFogLightCommand "Rear Fog Light Command: Command to activate or de-activate tractor or implement rear fog lights.  00b = De-activate01b = Activate10b = Reserved11b = Don't Care";
CM_ SG_ 2365473278 RightStopLightCommand "Right Stop Light Command: Command to activate or de-activate the tractor and implement right stop light00b = De-activate01b = Activate10b = Reserved11b = Don't Care";
CM_ SG_ 2365473278 RightTurnSignalLightsCommand "Right Turn Signal Lights Command: Command to activate or de-activate right turn signal lights on the tractor and all connected implements00b = De-activate01b = Activate10b = Reserved11b = Don't Care";
CM_ SG_ 2365473278 RotatingBeaconLightCommand "Rotating Beacon Light Command: Command to activate or de-activate slow moving vehicle indicator lights on tractor and/or implements.  Activation of the slow moving vehicle lights implies that the controller should manipulate the lighting as appropria...";
CM_ SG_ 2365473278 RunningLightCommand "Running Light Command: Command to activate or de-activate the tractor or powered vehicle running lights.  Usually only used for on road vehicles.00b = De-activate01b = Activate10b = Reserved11b = Don't Care";
CM_ SG_ 2365473278 TractorClearanceLightCommand "Tractor Clearance Light Command: Command to activate or de-activate the tractor high mounted clearance and center ID lights00b = De-activate01b = Activate10b = Reserved11b = Don't Care";
CM_ SG_ 2365473278 TractorFrontFogLightsCommand "Tractor Front Fog Lights Command: Command to activate or de-activate tractor front fog lights.00b = De-activate01b = Activate10b = Reserved11b = Don't Care";
CM_ SG_ 2365473278 TractorMarkerLightCommand "Tractor Marker Light Command: Command to activate or de-activate tractor and implement front position lights, rear red tail lights, side amber running lights, license plate lights and instrument and switch back lights.  00b = De-activate01b = Activat...";
CM_ SG_ 2365473278 TrtrFrntHghMntdWrkLghtsCmmnd "Tractor Front High Mounted Work Lights Command: Command to activate or de-activate the tractor front high mounted work lights.00b = De-activate01b = Activate10b = Reserved11b = Don't Care";
CM_ SG_ 2365473278 TrtrFrntLwMntdWrkLghtsCmmnd "Tractor Front Low Mounted Work Lights Command: Command to activate or de-activate the tractor front low mounted work lights.00b = De-activate01b = Activate10b = Reserved11b = Don't Care";
CM_ SG_ 2365473278 TrtrRrHghMntdWrkLghtsCmmnd "Tractor Rear High Mounted Work Lights Command: Command to activate or de-activate the tractor rear high  mounted work lights.00b = De-activate01b = Activate10b = Reserved11b = Don't Care";
CM_ SG_ 2365473278 TrtrRrLwMntdWrkLghtsCmmnd "Tractor Rear Low Mounted Work Lights Command: Command to activate or de-activate the tractor rear low  mounted work lights.00b = De-activate01b = Activate10b = Reserved11b = Don't Care";
CM_ SG_ 2365473278 TrtrSdHghMntdWrkLghtsCmmnd "Tractor Side High Mounted Work Lights Command: Command to activate or de-activate the tractor side high mounted work lights.00b = De-activate01b = Activate10b = Reserved11b = Don't Care";
CM_ SG_ 2365473278 TrtrSdLwMntdWrkLghtsCmmnd "Tractor Side Low Mounted Work Lights Command: Command to activate or de-activate the tractor side low mounted work lights.00b = De-activate01b = Activate10b = Reserved11b = Don't Care";
CM_ SG_ 2365473278 TrtrUndrsdMntdWrkLghtsCmmnd "Tractor Underside Mounted Work Lights Command: Command to activate or de-activate the tractor underside mounted work lights.00b = De-activate01b = Activate10b = Reserved11b = Don't Care";
CM_ BO_ 2365478910 "Air Suspension Control 5";
CM_ SG_ 2365478910 DamperStiffnessFrontAxle "Damper Stiffness Front Axle: Damper stiffness information of the shock absorber control at the front axle";
CM_ SG_ 2365478910 DamperStiffnessLiftTagAxle "Damper Stiffness Lift / Tag Axle: Damper stiffness information of the shock absorber control at the lift of tag axle";
CM_ SG_ 2365478910 DamperStiffnessRearAxle "Damper Stiffness Rear Axle: Damper stiffness information of the shock absorber control at the rear axle";
CM_ SG_ 2365478910 EltrnShkAsrrCntrlMdFrntAxl "Electronic Shock Absorber Control Mode -  Front Axle: Signal which indicates the current mode of operation of the electronic shock absorber control at the front axle.00b = Normal operation dampers passive01b = Normal operation dampers active10b = Err...";
CM_ SG_ 2365478910 EltrnShkAsrrCntrlMdLftTgAxl "Electronic Shock Absorber Control Mode - Lift/Tag Axle: Signal which indicates the current mode of operation of the electronic shock absorber control at the lift/tag axle.00b = Normal operation dampers passive01b = Normal operation dampers active10b ...";
CM_ SG_ 2365478910 EltrnShkAsrrCntrlMdRrAxl "Electronic Shock Absorber Control Mode - Rear Axle: Signal which indicates the current mode of operation of the electronic shock absorber control at the rear axle.00b = Normal operation dampers passive01b = Normal operation dampers active10b = Error1...";
CM_ BO_ 2365479678 "Air Suspension Control 1";
CM_ SG_ 2365479678 AboveNominalLevelFrontAxle "Above Nominal Level Front Axle: Signal which indicates whether the actual height of the front axle is above the nominal (desired) level of the front axle. For explanations of nominal level see SPN 1734 - Nominal Level Front Axle.00b = Not above01b = ...";
CM_ SG_ 2365479678 AboveNominalLevelRearAxle "Above Nominal Level Rear Axle: Signal which indicates whether the actual height of the rear axle is above the nominal (desired) level of the rear axle. For explanations of nominal level see parameter SPN 1734 - Nominal Level Front Axle.00b = Not abov...";
CM_ SG_ 2365479678 AllwLvlCntrlDrngBrkngStts "Allow Level Control During Braking Status: This parameter indicates if the function Allow Level Control During Braking is active. Functions is activated by SPN 5293.00b = Deactivated01b = Activated10b = Reserved11b = Don't care/take no action...";
CM_ SG_ 2365479678 BelowNominalLevelFrontAxle "Below Nominal Level Front Axle: Signal which indicates whether the actual height of the front axle is below the nominal (desired) level for the front axle. For explanations of nominal level see parameter SPN 1734 - Nominal Level Front Axle.00b = Not ...";
CM_ SG_ 2365479678 BelowNominalLevelRearAxle "Below Nominal Level Rear Axle: Signal which indicates whether the actual height of the rear axle is below the nominal (desired) level for the rear axle. For explanations of nominal level see SPN 1734 - Nominal Level Front Axle.00b = Not below01b = Be...";
CM_ SG_ 2365479678 DoorRelease "Door Release: Signal which indicates that the doors may be opened. [Please note: doors instead of door!]In case a kneeling request is active the ASC indicates during lowering the vehicle doors shall not be opened as a security information until the k...";
CM_ SG_ 2365479678 FrontAxleinBumperRange "Front Axle in Bumper Range: Signal which indicates that the vehicle height at the front axle (SPNs 1721 and 1722) is within the bumper range.00b = Actual level out of bumper range01b = Actual level within bumper range10b = Error11b = Not available...";
CM_ SG_ 2365479678 KneelingInformation "Kneeling Information: Signal which indicates the actual level change in case of kneeling function0000b = Not active,(i.e. the kneeling function is not active)0001b = Lowering active,(i.e. the vehicle is lowered due to a kneeling request)0010b = Kneel...";
CM_ SG_ 2365479678 LevelControlMode "Level Control Mode: Signal which indicates the actual control mode of the air suspension system0000b = Normal operation; i.e. the system performs a pure control of the vehicle height0001b = Traction help (load transfer); i.e. the driven axle is loade...";
CM_ SG_ 2365479678 LiftAxle1Position "Lift Axle 1 Position: Signal which indicates the position / load condition of lift axle / tag axle 1.   Numbering of lift/tag axles starts at front axle.  See SPN 6843 for more detail.00b = Lift axle position down / tag axle laden01b = Lift axle posi...";
CM_ SG_ 2365479678 LiftAxle2Position "Lift Axle 2 Position: Signal which indicates the position / load condition of lift axle / tag axle #2.   Numbering of lift/tag axles starts at front axle.  See SPN 6844 for more detail.00b = Lift axle position down / tag axle laden01b = Lift axle pos...";
CM_ SG_ 2365479678 LiftingControlModeFrontAxle "Lifting Control Mode Front Axle: Signal which indicates the actual lifting level change at the front axle00b = Lifting not active01b = Lifting active10b = Error11b = Not available";
CM_ SG_ 2365479678 LiftingControlModeRearAxle "Lifting Control Mode Rear Axle: Signal which indicates the actual lifting level change at the rear axle00b = Lifting not active01b = Lifting active10b = Error11b = Not available";
CM_ SG_ 2365479678 LoweringControlModeFrontAxle "Lowering Control Mode Front Axle: Signal which indicates the actual lowering level change at the front axle00b = Lowering not active01b = Lowering active10b = Error11b = Not available";
CM_ SG_ 2365479678 LoweringControlModeRearAxle "Lowering Control Mode Rear Axle: Signal which indicates the actual lowering level change at the rear axle00b = Lowering not active01b = Lowering active10b = Error11b = Not available";
CM_ SG_ 2365479678 Memorylevel "Memory level: Signal which indicates that the air suspension control has memory levels selected or stored.Response to memory level request in ASC2 (byte 8.5). If the request was executed the respective status will be set. If the request was not execu...";
CM_ SG_ 2365479678 NominalLevelFrontAxle "Nominal Level Front Axle: Signal which indicates the nominal (desired) height of the front axle to be controlled by the suspension system.These heights are discrete levels.  They are the upper level, lower level, normal level 1, normal level 2, norma...";
CM_ SG_ 2365479678 NominalLevelRearAxle "Nominal Level Rear Axle: Signal which indicates the nominal (desired) height of the rear axle to be controlled by the suspension system.For further explanations see SPN 1734 - Nominal Level Front Axle.0000b = Level not specified,(i.e. the nominal lev...";
CM_ SG_ 2365479678 RearAxleinBumperRange "Rear Axle in Bumper Range: Signal which indicates that the vehicle height at the rear axle (SPNs 1723 and 1724) is within the bumper range.00b = Actual level out of bumper range01b = Actual level within bumper range10b = Error11b = Not available...";
CM_ SG_ 2365479678 SecurityDevice "Security Device: The signal which indicates the status of the security device.  An example of a security device is a curbstone feeler installed beneath the doors of a bus. If the security device becomes active during kneeling the kneeling process (lo...";
CM_ SG_ 2365479678 SpdDpndntLvlCntrlStts "Speed Dependant Level Control Status: This parameter indicates if the function Speed Dependant Level Control is active. The function is activated by SPN 5295.00b = Inactive01b = Active10b = Reserved11b = Don't' care/take no action";
CM_ SG_ 2365479678 SspnsnCntrlRfslInfrmtn "Suspension Control Refusal Information: Signal which indicates that the air suspension control cannot perform a request due to the operating conditions. It also provides a reason for the refusal.0000b = Actual request not refused0001b = Axle load lim...";
CM_ SG_ 2365479678 SuspensionRemoteControl1 "Suspension Remote Control 1: Signal which indicates that the suspension system is controlled by remote control #1. Remote control is an external unit to operate the suspension system.00b = Not active01b = Active10b = Error11b = Not available...";
CM_ SG_ 2365479678 SuspensionRemotecontrol2 "Suspension Remote control 2: Signal which indicates that the suspension system is controlled by remote control #2. Remote control is an external unit to operate the suspension system.00b = Not active01b = Active10b = Error11b = Not available...";
CM_ SG_ 2365479678 VehicleMotionInhibit "Vehicle Motion Inhibit: Signal which indicates whether vehicle motion is inhibited.00b = Vehicle may be moved01b = Vehicle motion is inhibited10b = Error11b = Not available";
CM_ BO_ 2365484286 "Tachograph";
CM_ SG_ 2365484286 Directionindicator "Direction indicator: Indicates the direction of the vehicle.00b = Forward01b = Reverse10b = Error11b = Not available";
CM_ SG_ 2365484286 Driver1TimeRelatedStates "Driver 1 Time Related States: Indicates if the driver approaches or exceeds working time limits (or other limits).  0000b = Normal/No limits reached0001b = Limit #1 – 15 min before 4 ½ h0010b = Limit #2 – 4 ½ h reached0011b = Limit #3 – 15 min before...";
CM_ SG_ 2365484286 Driver1workingstate "Driver 1 working state: State of work of the driver.  000b = Rest - sleeping001b = Driver available – short break010b = Work – loading, unloading, working in an office011b = Drive – behind wheel 100b = Reserved101b = Reserved110b = Error111b = Not av...";
CM_ SG_ 2365484286 Driver2TimeRelatedStates "Driver 2 Time Related States: Indicates if the driver approaches or exceeds working time limits (or other limits).  0000b = Normal/No limits reached0001b = Limit #1 – 15 min before 4 ½ h0010b = Limit #2 – 4 ½ h reached0011b = Limit #3 – 15 min before...";
CM_ SG_ 2365484286 Driver2workingstate "Driver 2 working state: State of work of the driver.  000b = Rest - sleeping001b = Driver available – short break010b = Work – loading, unloading, working in an office011b = Drive – behind wheel 100b = Reserved101b = Reserved110b = Error111b = Not av...";
CM_ SG_ 2365484286 Drivercarddriver1 "Driver card, driver 1: Indicates the presence of a driver card00b = Driver card not present01b = Driver card present10b = Error11b = Not available";
CM_ SG_ 2365484286 Drivercarddriver2 "Driver card, driver 2: Indicates the presence of a driver card00b = Driver card not present01b = Driver card present10b = Error11b = Not available";
CM_ SG_ 2365484286 Handlinginformation "Handling information: Indicates that handling information is present.  Information could include no printer paper, no driver card, etc.00b = No handling information01b = Handling information10b = Error11b = Not available";
CM_ SG_ 2365484286 Systemevent "System event: Indicates that a tachograph event has occurred.  This may include power supply interruption, interruption of the speed sensor, incorrect data on the driver card, driving without a driver card, illegal removal of a driver card, insertion...";
CM_ SG_ 2365484286 Tachographoutputshaftspeed "Tachograph output shaft speed: Calculated speed of the transmission output shaft.";
CM_ SG_ 2365484286 Tachographperformance "Tachograph performance: Indicates the tachograph performance; including electronic or mechanical analysis, instrument analysis, speed sensor analysis, mass storage analysis, and printer analysis.00b = Normal performance01b = Performance analysis10b =...";
CM_ SG_ 2365484286 Tachographvehiclespeed "Tachograph vehicle speed: Speed of the vehicle registered by the tachograph.";
CM_ SG_ 2365484286 Vehiclemotion "Vehicle motion: Indicates whether motion of the vehicle is detected or not.00b = Vehicle motion not detected01b = Vehicle motion detected10b = Error11b = Not available";
CM_ SG_ 2365484286 VehicleOverspeed "Vehicle Overspeed: Indicates whether the vehicle is exceeding the legal speed limit set in the tachograph.00b = No overspeed01b = Overspeed10b = Error11b = Not available";
CM_ BO_ 2365485566 "Laser Tracer Position";
CM_ SG_ 2365485566 LaserTracerHorizontalDeviation "Laser Tracer Horizontal Deviation: The calculated percent deviation between the target distance and the center of the laser tracer.The values 0 to 99% indicates target is left of center, 101 to 200% indicates  target is right of center, 100% indicate...";
CM_ SG_ 2365485566 LaserTracerInformation "Laser Tracer Information: Provides the status of the laser tracer to the operator. 00000001b = Laser power is on00000010b = Laser is ready00000100b = Valid target (1 = yes)00001000b = Previous pass (1 = yes)00010000b = Stringline (1 = yes)00100000b =...";
CM_ SG_ 2365485566 LaserTracerTargetDeviation "Laser Tracer Target Deviation: The calculated distance for the laser target to the current laser tracer reference point.Negative values are below setpoint, positive values are above setpoint, zero is on grade.Parameter specific parameter: FE03h indic...";
CM_ SG_ 2365485566 LaserTracerVerticalDistance "Laser Tracer Vertical Distance: The elevation of the laser tracer sensor in a laser leveling system.";
CM_ SG_ 2365485566 LEDDisplayData2 "LED Display Data #2: Informs display devices how to display the current position of the laser tracer.Values which are less than 128 decimal are bit-mapped values and any combination of these values is considered a valid value.  For example communicat...";
CM_ BO_ 2365485822 "Laser Leveling System Blade Control";
CM_ SG_ 2365485822 BladeControlMode "Blade Control Mode: Allows the user to select the type of blade control for the land leveling system.  00000000b = Manual mode00000001b = Automatic mode00000010b = Inactive automatic modeAll other values Reserved";
CM_ SG_ 2365485822 BladeControlModeLeft "Blade Control Mode - Left: Indicate if the land leveling system's automatic control is active or inactive for the elevation sensor on the left side of the blade.  The left notation is applicable to grading machines such tractors and motor graders whe...";
CM_ SG_ 2365485822 BladeControlModeRight "Blade Control Mode - Right: Indicate if the land leveling system's automatic control is active or inactive for the elevation sensor on the right side of the blade.  The left notation is applicable to grading machines such tractors and motor graders w...";
CM_ SG_ 2365485822 BladeDurationandDirection "Blade Duration and Direction: Used to indicate the duration and direction that the land leveling system blade moves.Negative values indicate move the blade up, positive values indicate move the blade down, zero indicates no change.";
CM_ SG_ 2365485822 LandLevelingSystemEnableStatus "Land Leveling System Enable Status: Communicate the enable/disable status of the Land Leveling System.00b = Disabled01b = Enabled10b = Error11b = Not available / Not installed";
CM_ BO_ 2365486078 "Laser Receiver Mast Position";
CM_ SG_ 2365486078 MastPosition "Mast Position: Used to monitor the position of the sensor attached to the land leveling mast.Negative values indicate below current position, positive values are above current position, zero indicates no change.";
CM_ BO_ 2365486334 "Modify Leveling System Control Set Point";
CM_ SG_ 2365486334 BldHghtStPntHghRsltn "Blade Height Set Point (High Resolution): High resolution for the laser guided blade set point.  The high resolution required for more accurate control and 'accurate' unit conversions.Negative values are below grade, positive values are above grade, ...";
CM_ SG_ 2365486334 ModifyLevelingSystemSetPoint "Modify Leveling System Set Point: Used to control and coordinate the set point for the leveling system.Operating Range: -3200 to +3200 mm, negative values are below current position, positive values are above current position, zero is no change.Param...";
CM_ BO_ 2365486590 "Laser Leveling System Vertical Deviation";
CM_ SG_ 2365486590 AbsoluteLaserStrikePosition "Absolute Laser Strike Position: Laser Strike location on the survey type  laser receiver.";
CM_ SG_ 2365486590 LaserReceiverType "Laser Receiver Type: Identifies which type of Laser Receiver transmitted the message.0 = Reserved 1 = Linear Laser Receiver2 = 1 Meter Survey Receiver3 = 2 Meter Survey Receiver4 = 2.5 Meter Survey Receiver5 to 250 = Reserved";
CM_ SG_ 2365486590 LaserStrikeDataLatency "Laser Strike Data Latency: Time from laser strike to CAN message transmission.  This parameter will be reported by survey receiver type devices only. Byte 3 (SPN 2576) of  PGN 65141 identifies the type of Laser Receiver.";
CM_ SG_ 2365486590 LaserStrikeVerticalDeviation "Laser Strike Vertical Deviation: The calculated distance from the laser strike position to the current land leveling system reference point.Negative values indicate below grade, positive values are above grade, zero is on gradeParameter specific para...";
CM_ BO_ 2431649790 "Forward Lane Image 1";
CM_ SG_ 2431649790 DriverAlertnessWarning "Driver Alertness Warning: Indicates when a distracted driving condition is detected. This signal can be used independent of the technology and ECU used to estimate the distracted driver condition.000b = No distracted driving condition detected001b = ...";
CM_ SG_ 2431649790 LaneDepartureImminentLeftSide "Lane Departure Imminent, Left Side: Indicates departure imminent on left side of lane.00b = Not imminent01b = Imminent10b = Reserved11b = Not used";
CM_ SG_ 2431649790 LaneDepartureImminentRightSide "Lane Departure Imminent, Right Side: Indicates departure imminent on right side of lane.00b = Not imminent01b = Imminent10b = Reserved11b = Not Used";
CM_ SG_ 2431649790 LaneDepartureLeft "Lane Departure Left: Indicates that the middle of vehicle departs the lane on the left side. The parameter indicates that the vehicle is changing the lane to the left.00b = Middle of the vehicle does not depart the lane to the left side01b = Middle o...";
CM_ SG_ 2431649790 LaneDepartureRight "Lane Departure Right: Indicates that the middle of vehicle departs the lane on the right side. The parameter indicates that the vehicle is changing the lane to the right.00b = Middle of the vehicle does not depart the lane to the right side01b = Midd...";
CM_ SG_ 2431649790 LftSdLnDprtrAstlWrnngCmmnd "Left Side Lane Departure Acoustical Warning Command: Indicates that the forward lane imaging system is commanding an acoustical warning for the lane departure on the left side of the vehicle.Used for driving acoustical alert devices with minimal inte...";
CM_ SG_ 2431649790 LftSdLnDprtrOptlWrnngCmmnd "Left Side Lane Departure Optical Warning Command: Indicates that the forward lane imaging system is commanding an optical warning for the lane departure on the left side of the vehicle.Used for driving optical alert devices with minimal internal logi...";
CM_ SG_ 2431649790 RghtSdLnDprtrAstlWrnngCmmnd "Right Side Lane Departure Acoustical Warning Command: Indicates that the forward lane imaging system is commanding an acoustical warning for the lane departure on the right side of the vehicle.Used for driving acoustical alert devices with minimal in...";
CM_ SG_ 2431649790 RghtSdLnDprtrOptlWrnngCmmnd "Right Side Lane Departure Optical Warning Command: Indicates that the forward lane imaging system is commanding an optical warning for the lane departure on the right side of the vehicle.Used for driving optical alert devices with minimal internal lo...";
CM_ SG_ 2431649790 RghtSdLnDprtrHptWrnngCmmnd "Right Side Lane Departure Haptic Warning Command: Indicates that the forward lane imaging system is commanding an haptic warning for the lane departure on the right side of the vehicle.Used for driving haptic alert devices with minimal internal logic...";
CM_ SG_ 2431649790 LftSdLnDprtrHptWrnngCmmnd "Left Side Lane Departure Haptic Warning Command: Indicates that the forward lane imaging system is commanding an haptic warning for the lane departure on the left side of the vehicle.Used for driving haptic alert devices with minimal internal logic (...";
CM_ BO_ 2431654654 "Engine Throttle / Fuel Actuator Control Command";
CM_ SG_ 2431654654 EngnFlAttr1CntrlCmmnd "Engine Fuel Actuator 1 Control Command: The control command to fuel actuator 1, normalized to percent, where 0% represents fully closed and 100% represents fully open. In applications where the fuel actuator controls to differential pressure, 0% repr...";
CM_ SG_ 2431654654 EngnFlAttr2CntrlCmmnd "Engine Fuel Actuator 2 Control Command: The control command to fuel actuator 2, normalized to percent, where 0% represents fully closed and 100% represents fully open. Typically, this fuel actuator is used to regulate low pressure natural gas flow ra...";
CM_ SG_ 2431654654 EngnThrttlAttr1CntrlCmmnd "Engine Throttle Actuator 1 Control Command: The control command to throttle actuator 1, normalized to percent, where 0% represents fully closed and 100% represents fully open.  Typically, this throttle actuator is used to regulate air or air / fuel m...";
CM_ SG_ 2431654654 EngnThrttlAttr2CntrlCmmnd "Engine Throttle Actuator 2 Control Command: The control command to throttle actuator 2, normalized to percent, where 0% represents fully closed and 100% represents fully open.  Typically, this throttle actuator is used to regulate air or air / fuel m...";
CM_ BO_ 2431661054 "Aftertreatment 1 SCR Ammonia Information 2";
CM_ SG_ 2431661054 Aftrtrtmnt1SCRIntrmdtNH3 "Aftertreatment 1 SCR Intermediate NH3: The amount of NH3 in the exhaust aftertreatment system measured by a NH3 sensor at an intermediate point in the SCR system, represented in NH3 molecule parts per million non-NH3 molecules in exhaust bank 1.";
CM_ SG_ 2431661054 Aftrtrtmnt1SCRIntrmdtNH3RdngStl "Aftertreatment 1 SCR Intermediate NH3 Reading Stable: Indicates that the NH3 reading of the aftertreatment SCR intermediate NH3 sensor is stable as determined by the manufacturer's control software in exhaust bank 1.00b = Reading is not stable01b = R...";
CM_ SG_ 2431661054 Atttt1SCRItdtNH3SsHtCt "Aftertreatment 1 SCR Intermediate NH3 Sensor Heater Control: Indicates the heater status in the warm-up process. Upon receiving a power-up command, the NH3 sensor ramps up according to a manufacturer defined profile. The Preheat 1, Preheat 2, and Aut...";
CM_ SG_ 2431661054 Atttt1SCRItdtNH3SsHtPFMI "Aftertreatment 1 SCR Intermediate NH3 Sensor Heater Preliminary FMI: Used to identify the applicable J1939-73 FMI detected in the heater of the outlet NH3 exhaust sensor by the manufacturer’s sensor control software in exhaust bank 1. In the case of ...";
CM_ SG_ 2431661054 Atttt1SCRItdtNH3SsPFMI "Aftertreatment 1 SCR Intermediate NH3 Sensor Preliminary FMI: Used to identify the applicable J1939-73 FMI detected in the aftertreatment SCR intermediate NH3 sensor by the manufacturer’s sensor control software in exhaust bank 1. In the case of mult...";
CM_ SG_ 2431661054 Atttt1SCRItdtNH3SsPwIR "Aftertreatment 1 SCR Intermediate NH3 Sensor Power In Range: Indicates that the power supplied to the aftertreatment SCR intermediate NH3 sensor is within the manufacturer's specification in exhaust bank 1.00b = Power is not in range01b = Power is in...";
CM_ SG_ 2431661054 Atttt1SCRItdtNH3SstTpt "Aftertreatment 1 SCR Intermediate NH3 Sensor at Temperature: Indicates that the heater element of the aftertreatment SCR intermediate NH3 sensor is within the manufacturer's specified range for accurate measurements in exhaust bank 1.00b = Heater ele...";
CM_ BO_ 2431661310 "Aftertreatment 2 SCR Ammonia Information 2";
CM_ SG_ 2431661310 Aftrtrtmnt2SCRIntrmdtNH3 "Aftertreatment 2 SCR Intermediate NH3: The amount of NH3 in the exhaust aftertreatment system measured by a NH3 sensor at an intermediate point in the SCR system, represented in NH3 molecule parts per million non-NH3 molecules in exhaust bank 2.";
CM_ SG_ 2431661310 Aftrtrtmnt2SCRIntrmdtNH3RdngStl "Aftertreatment 2 SCR Intermediate NH3 Reading Stable: Indicates that the NH3 reading of the aftertreatment SCR intermediate NH3 sensor is stable as determined by the manufacturer's control software in exhaust bank 2.00b = Reading is not stable01b = R...";
CM_ SG_ 2431661310 Atttt2SCRItdtNH3SsHtCt "Aftertreatment 2 SCR Intermediate NH3 Sensor Heater Control: Indicates the heater status in the warm-up process. Upon receiving a power-up command, the NH3 sensor ramps up according to a manufacturer defined profile. The Preheat 1, Preheat 2, and Aut...";
CM_ SG_ 2431661310 Atttt2SCRItdtNH3SsHtPFMI "Aftertreatment 2 SCR Intermediate NH3 Sensor Heater Preliminary FMI: Used to identify the applicable J1939-73 FMI detected in the heater of the SCR intermediate NH3 exhaust sensor by the manufacturer’s sensor control software in exhaust bank 2. In th...";
CM_ SG_ 2431661310 Atttt2SCRItdtNH3SsPFMI "Aftertreatment 2 SCR Intermediate NH3 Sensor Preliminary FMI: Used to identify the applicable J1939-73 FMI detected in the aftertreatment SCR intermediate NH3 sensor by the manufacturer’s sensor control software in exhaust bank 2. In the case of mult...";
CM_ SG_ 2431661310 Atttt2SCRItdtNH3SsPwIR "Aftertreatment 2 SCR Intermediate NH3 Sensor Power In Range: Indicates that the power supplied to the aftertreatment SCR intermediate NH3 sensor is within the manufacturer's specification in exhaust bank 2.00b = Heater element is not in range01b = He...";
CM_ SG_ 2431661310 Atttt2SCRItdtNH3SstTpt "Aftertreatment 2 SCR Intermediate NH3 Sensor at Temperature: Indicates that the heater element of the aftertreatment SCR intermediate NH3 sensor is within the manufacturer's specified range for accurate measurements in exhaust bank 2.00b = Heater ele...";
CM_ BO_ 2431708670 "Engine Start Control";
CM_ SG_ 2431708670 EngineStartAbortRequest "Engine Start Abort Request: Indicates the sender's desire to abort an engine start. This signal is used by requesters and consenters to request that the arbitrator cancel an engine start that is in progress.The sender of this signal may increase the ...";
CM_ SG_ 2431708670 EngineStartConsent "Engine Start Consent: Indicates the sender's consent to start the engine for different start types. An operator-requested engine start is a start that is initiated directly by the operator (i.e. via the key switch). An automatic engine start is one t...";
CM_ SG_ 2431708670 EngineStartControlChecksum "Engine Start Control Checksum: Checksum to allow detection of data integrity issues. The receiving node shall calculate the checksum and compare its calculated value with the received checksum. In case of a mismatch the message shall be discarded.The...";
CM_ SG_ 2431708670 EngineStarter1Feedback "Engine Starter 1 Feedback: Feedback of the current state of first engine starter. This signal is intended to be used by the arbitrator as feedback to its command signal (SPN 7753).Additional details regarding the starter state may be available in SPN...";
CM_ SG_ 2431708670 EngineStarter2Feedback "Engine Starter 2 Feedback: Feedback of the current state of second engine starter. This signal is intended to be used by the arbitrator as feedback to its command signal (SPN 7753).Additional details regarding the starter state may be available in SP...";
CM_ SG_ 2431708670 EngineStartRequest "Engine Start Request: Indicates the sender's desire to start the engine. The engine start arbitrator latches this signal and, if possible, completes the engine start regardless of a change of state of this signal. Use Engine Start Abort Request (SPN ...";
CM_ SG_ 2431708670 EngnStrtCntrlMssgCntr "Engine Start Control Message Counter: Message counter to allow detection of data integrity issues. The counter is incremented every time a device sends out the Engine Start Control message. When the counter has reached a value of 15 it starts over at...";
CM_ SG_ 2431708670 TrnsmssnShftSltrRqstdVhlDrtn "Transmission Shift Selector Requested Vehicle Direction: This parameter indicates the direction selected by the operator via the active transmission shift selector.Some regulations (e.g., Federal Motor Vehicle Safety Standards 102) require specific E...";
CM_ BO_ 2431710718 "Engine Start Arbitrator";
CM_ SG_ 2431710718 AtmtEngnStrtCnsntSmmr "Automatic Engine Start Consent Summary: Arbitrator's summary of the consent statuses of all devices which the arbitrator considers for automatic start requests. The purpose of this parameter is for requesters to determine if an automatic start reques...";
CM_ SG_ 2431710718 EngineStartArbitratorChecksum "Engine Start Arbitrator Checksum: Checksum to allow detection of data integrity issues. The receiving node shall calculate the checksum and compare its calculated value with the received checksum. In case of a mismatch the message shall be discarded....";
CM_ SG_ 2431710718 EngineStartControlMessageRate "Engine Start Control Message Rate: This signal is sent by the arbitrator to control the rate at which other participants send the Engine Start Control Message (ENGSC). The arbitrator sets this signal to the slower rate after the first engine start at...";
CM_ SG_ 2431710718 EngineStarterCommand "Engine Starter Command: Command from the arbitrator to the engine starter controller(s).The arbitrator takes input from consenters and requesters to initiate an engine start. This signal is used by the arbitrator to command the first or second starte...";
CM_ SG_ 2431710718 EngineStartRequestLatchStatus "Engine Start Request Latch Status: Indicates the arbitrator's latch status for engine start requests. All unlatched states shall transition to state 0 – Start Request not received after 1000 ms unless a different state becomes more appropriate in the...";
CM_ SG_ 2431710718 EngnStrtArtrtrMssgCntr "Engine Start Arbitrator Message Counter: Message counter to allow detection of data integrity issues. The counter is incremented every time a device sends out the Engine Start Control message. When the counter has reached a value of 15 it starts over...";
CM_ SG_ 2431710718 OprtrEngnStrtCnsntSmmr "Operator Engine Start Consent Summary: Arbitrator's summary of the consent statuses of all devices which the arbitrator considers for operator start requests. The purpose of this parameter is for requesters to determine if an operator start request w...";
CM_ BO_ 2431717886 "Gaseous Fuel Pressure 3";
CM_ SG_ 2431717886 EngnFlVlv1DffrntlPrssrHghRsltn "Engine Fuel Valve 1 Differential Pressure (High Resolution): The differential pressure between the intake and the outlet of the first or only gaseous fuel valve.See SPN 1391 for alternate range and resolution.";
CM_ SG_ 2431717886 EngnGssFlSpplFltrDffrntlPrssr "Engine Gaseous Fuel Supply Filter Differential Pressure: Change in gaseous fuel delivery pressure, measured across the filter, due to accumulation of solid or semisolid matter on the filter element.";
CM_ SG_ 2431717886 EngnGssFlSpplFltrIntkPrssr "Engine Gaseous Fuel Supply Filter Intake Pressure: Pressure of gaseous fuel supply measured at the intake of gaseous fuel supply filter.";
CM_ BO_ 2431719166 "Well Stimulation Pump System 3";
CM_ SG_ 2431719166 WellStimulationPumpFlowRate "Well Stimulation Pump Flow Rate: The amount of fluid that is being pumped by the well stimulation pump.";
CM_ SG_ 2431719166 WellStimulationPumpRodLoad "Well Stimulation Pump Rod Load: The load on the plungers of the well stimulation pump.";
CM_ SG_ 2431719166 WllStmltnPmpCvttnStts "Well Stimulation Pump Cavitation Status: Indicates the level of cavitation detected on the well stimulation pump.000b = No Cavitation001b = Low010b = Medium011b = High100b = Reserved101b = Reserved110b = Error111b = Not Available";
CM_ SG_ 2431719166 WllStmltnPmpFldEndVlvLk "Well Stimulation Pump Fluid End Valve Leak: Indicates the leakage detected in the well stimulation pump fluid end.00b = No Leak Detected01b = Leak Detected10b = Error11b = Not Available";
CM_ SG_ 2431719166 WllStmltnPmpRtdRdLdPrnt "Well Stimulation Pump Rated Rod Load Percent: Parameter which represents the ratio of the calculated rod load (reference SPN 8648) divided by the rated rod load of the pump * 100.";
CM_ BO_ 2432471038 "Alternate Fuel 3";
CM_ SG_ 2432471038 EngnFlVprzr1DshrgTmprtr "Engine Fuel Vaporizer 1 Discharge Temperature: The temperature of the fuel in its gaseous state at the outlet of the first fuel vaporizer";
CM_ SG_ 2432471038 EngnGssFlSpplPrssr1ExtnddRng "Engine Gaseous Fuel Supply Pressure 1 (Extended Range): Pressure of gaseous fuel supply to fuel metering device in systems where the pressure range defined for SPN 159 is not sufficient.";
CM_ SG_ 2432471038 GssFlAmltrTmprtr "Gaseous Fuel Accumulator Temperature: Gaseous fuel temperature at the outlet of the Gas Filter.";
CM_ SG_ 2432471038 EGssFSppPssRtCtCd "Engine Gaseous Fuel Supply Pressure Regulator Control Command: The command to the fuel pressure regulator which regulates the pressure of gaseous fuel supply to the engine. This command is normalized to percent, where 0% nominally represents fully cl...";
CM_ BO_ 2432492542 "Engine Exhaust Brake Control";
CM_ SG_ 2432492542 EngnExhstBrkAttrCmmnd "Engine Exhaust Brake Actuator Command: The control command applied to the engine exhaust brake actuator, where 0% represents no braking and 100% represents full braking.";
CM_ SG_ 2432492542 EngnTrhrgr1TrnDsrdOtltPrssr "Engine Turbocharger 1 Turbine Desired Outlet Pressure: The desired gage pressure of the combustion by-products exiting the turbine side of the turbocharger 1 at the current engine operating conditions.";
CM_ SG_ 2432492542 EngnTrhrgr1TrnOtltPrssr "Engine Turbocharger 1 Turbine Outlet Pressure: Gage pressure of the combustion by-products exiting the turbine side of the turbocharger 1.";
CM_ SG_ 2432492542 EngnTrhrgr2TrnDsrdOtltPrssr "Engine Turbocharger 2 Turbine Desired Outlet Pressure: The desired gage pressure of the combustion by-products exiting the turbine side of the turbocharger 2 at the current engine operating conditions.";
CM_ SG_ 2432492542 EngnTrhrgr2TrnOtltPrssr "Engine Turbocharger 2 Turbine Outlet Pressure: Gage pressure of the combustion by-products exiting the turbine side of the turbocharger 2.";
CM_ BO_ 2432499198 "Electronic Engine Controller 9";
CM_ SG_ 2432499198 CmmnddEngnFlInjtnCntrlPrssr "Commanded Engine Fuel Injection Control Pressure: Provides the commanded set point value for the engine fuel injection control pressure.";
CM_ SG_ 2432499198 CommandedEngineFuelRailPressure "Commanded Engine Fuel Rail Pressure: Provides the commanded set point value for the engine fuel rail gage pressure";
CM_ SG_ 2432499198 EngnExhstGsRrltn2Vlv2Pstn "Engine Exhaust Gas Recirculation 2 Valve 2 Position: The position of the second exhaust gas recirculation valve of EGR 2 expressed as a percentage of full travel. 0% means the valve is closed and no exhaust gas is flowing into the air stream. 100% me...";
CM_ SG_ 2432499198 EngnExhstGsRrltn2VlvPstn "Engine Exhaust Gas Recirculation 2 Valve Position: Position of EGR2 valve expressed as a percentage of full travel. 0% means the valve is closed and no exhaust gas is flowing into the air stream. 100% means the valve is fully opened.";
CM_ BO_ 2432520702 "Aftercooler Coolant Control Valve Command";
CM_ SG_ 2432520702 AftrlrClntThrmsttMd "Aftercooler Coolant Thermostat Mode: Specifies if the aftercooler coolant thermostat valve will operate in temperature control mode or position control mode.00b = temperature control mode01b = position control mode (used for service only)10b = reserv...";
CM_ SG_ 2432520702 DsrdAftrlrClntIntkTmprtr "Desired Aftercooler Coolant Intake Temperature: Indicates the desired temperature of the fluid in the low temperature aftercooler circuit to an electronic thermostat.  If the aftercooler coolant thermostat valve is operating in position control mode ...";
CM_ SG_ 2432520702 DsrdAftrlrClntThrmsttOpnng "Desired Aftercooler Coolant Thermostat Opening: Used to transmit the desired position of the low temperature aftercooler temperature control valve.  0% represents the thermostat allows flow to completely bypass the aftercooler and 100% represents the...";
CM_ SG_ 2432520702 EngnChrgArClrBpssVlv1Cmmnd "Engine Charge Air Cooler Bypass Valve 1 Command: Desired percentage of charge air cooler Bypass Valve 1 opening. 0% means no air is bypassed. 100% means full bypass capacity.";
CM_ SG_ 2432520702 EngnChrgArClrBpssVlv2Cmmnd "Engine Charge Air Cooler Bypass Valve 2 Command: Desired percentage of charge air cooler Bypass Valve 2 opening. 0% means no air is bypassed. 100% means full bypass capacity.";
CM_ BO_ 2432520958 "Engine Coolant Control Valve Command";
CM_ SG_ 2432520958 DsrdEngnClntPmpOtltTmprtr "Desired Engine Coolant Pump Outlet Temperature: Desired engine coolant temperature of the engine to an electronic thermostat.  If the electronic thermostat valve is operating in position control mode (see SPN 4195)  then transmit FFh.";
CM_ SG_ 2432520958 DsrdEngnClntThrmsttOpnng "Desired Engine Coolant Thermostat Opening: Indicates the desired position of the engine coolant control valve.   0% represents the thermostat allows flow to completely bypass the radiator and 100% represents the flow is fully through the radiator.  I...";
CM_ SG_ 2432520958 EngineCoolantThermostatMode "Engine Coolant Thermostat Mode: Specifies if the engine coolant thermostat valve will operate in temperature control mode or position control mode.00b = temperature control mode01b = position control mode (used for service only)10b = reserved11b = do...";
CM_ SG_ 2432520958 EngnAxlrClrSpplVlv1AttrCmmnd "Engine Auxiliary Cooler Supply Valve 1 Actuator Command: The control command applied to the engine auxiliary cooler supply valve 1 actuator, where 0% represents closed and 100% represents open.See SPN 4197 for primary engine thermostat valve.";
CM_ SG_ 2432520958 EngnAxlrClrSpplVlv2AttrCmmnd "Engine Auxiliary Cooler Supply Valve 2 Actuator Command: The control command applied to the engine auxiliary cooler supply valve 2 actuator, where 0% represents closed and 100% represents open.";
CM_ BO_ 2432541438 "Fuel Information 3 (Gaseous)";
CM_ SG_ 2432541438 EngineFuel1Temperature2 "Engine Fuel 1 Temperature 2: Second Temperature measurement of fuel (or gas) of the first fuel type. See SPN 174 for first fuel temperature measurement.";
CM_ SG_ 2432541438 EngnFlSstm2GsMssFlwRt "Engine Fuel System 2 Gas Mass Flow Rate: Gas mass flow rate delivered to an engine through its second fuel control system, using standard convention for determining position.In a system with two fuel system control valves, left/front is #1 (SPN 1241)...";
CM_ SG_ 2432541438 EngnFlVlv2IntkAsltPrssr "Engine Fuel Valve 2 Intake Absolute Pressure: Absolute pressure of gas on intake side of the second fuel system control valve, using standard convention for determining position.In a system with two fuel system control valves, left/front is #1 (SPN 1...";
CM_ SG_ 2432541438 EngnFlVlv2OtltAsltPrssr "Engine Fuel Valve 2 Outlet Absolute Pressure: Absolute pressure of gas on outlet side of the second fuel system control valve.  See SPN 2980 for the first or only fuel system control valve.";
CM_ BO_ 2432541694 "Electronic Engine Controller 6";
CM_ SG_ 2432541694 EngnTrhrgrCmprssrBpssAttr1Cmmnd "Engine Turbocharger Compressor Bypass Actuator 1 Command: The command to a compressor bypass actuator, normalized to percent, where 0% nominally represents fully closed and 100% represents fully open.  Typically, the turbocharger compressor bypass ac...";
CM_ SG_ 2432541694 EngnTrhrgrCmprssrBpssAttr1Pstn "Engine Turbocharger Compressor Bypass Actuator 1 Position: Measures the position of the turbocharger compressor bypass actuator, where 0% represents bypass fully closed and 100% represents bypass fully open.  Typically, the compressor bypass is used ...";
CM_ SG_ 2432541694 EngnTrhrgrCmprssrBpssAttr2Cmmnd "Engine Turbocharger Compressor Bypass Actuator 2 Command: The command to a compressor bypass actuator 2, normalized to percent, where 0% nominally represents fully closed and 100% represents fully open. Typically, the turbocharger compressor bypass a...";
CM_ SG_ 2432541694 EngnVrlGmtrTrhrgrAttr1 "Engine Variable Geometry Turbocharger Actuator #1: Actuator that controls the variable geometry turbocharger geometry.The control command to the actuator, normalized to percent, where 0% nominally represents fully closed (smallest turbocharger geomet...";
CM_ SG_ 2432541694 ETCpssBpssAtt1DsdPst "Engine Turbocharger Compressor Bypass Actuator 1 Desired Position: The requested position of the Engine Turbocharger Compressor Bypass actuator by the engine ECU, where 0% represents bypass fully closed and 100% represents bypass fully open.This is t...";
CM_ SG_ 2432541694 ETCpssBpssAtt1PFMI "Engine Turbocharger Compressor Bypass Actuator 1 Preliminary FMI: Used to identify the applicable J1939-73 FMI detected in the Engine Turbocharger Compressor Bypass Actuator 1 by the manufacturers software.  When there is multiple failures, the most ...";
CM_ SG_ 2432541694 ETCpssBpssAtt1TptStts "Engine Turbocharger Compressor Bypass Actuator 1 Temperature Status: Used to identify the status of the Engine Turbocharger Compresssor Bypass Actuator 1 drive circuitry temperature.  Temperature excursions may affect the torque output.000b = High Mo...";
CM_ BO_ 2432593918 "Adaptive Cruise Control 1";
CM_ SG_ 2432593918 ACCDistanceAlertSignal "ACC Distance Alert Signal: Signal to indicate to the operator that the ACC system is not able to maintain the distance to the target. Example: Target stopping rapidly. This signal may be used to activate warning sounds or indicators.00b = ACC DAS Not...";
CM_ SG_ 2432593918 ACCSystemShutoffWarning "ACC System Shutoff Warning: Signal to warn the driver of system deactivation due to non-driver actions. Example: Attempting to control vehicle speed below or above limits of ACC. This signal may be used to activate warning sounds or indicators.00b = ...";
CM_ SG_ 2432593918 ACCTargetDetected "ACC Target Detected: Signal to indicate to the driver that the ACC system has detected a target. 00b = No targets detected01b = Target detected10b = Reserved11b = Take no action";
CM_ SG_ 2432593918 AdaptiveCruiseControlMode "Adaptive Cruise Control Mode: This parameter is used to indicate the current state, or mode, of operation by the Adaptive Cruise Control (ACC) device. The states characterize independent system states (e.g., it is not possible to express distance con...";
CM_ SG_ 2432593918 AdaptiveCruiseControlSetSpeed "Adaptive Cruise Control Set Speed: Value of the desired (chosen) velocity of the adaptive cruise control system.";
CM_ SG_ 2432593918 Adptvrsntrlstdstnmd "Adaptive cruise control set distance mode: Selected distance mode for adaptive cruise control. 000b = ACC Distance mode #1 (largest distance)001b = ACC Distance mode #2010b = ACC Distance mode #3011b = ACC Distance mode #4100b = ACC Distance mode #5 ...";
CM_ SG_ 2432593918 Distancetoforwardvehicle "Distance to forward vehicle: Distance to the preceding vehicle situated within 250 m in the same lane and moving in the same direction.The value of FFh indicates that no vehicle is detected.";
CM_ SG_ 2432593918 ForwardCollisionWarning "Forward Collision Warning: This parameter indicates if a collision is imminent and strong driver reaction either by braking hard or by an avoidance maneuver are imperative to prevent a collision.  00b = No warning01b = Collision is imminent10b = Erro...";
CM_ SG_ 2432593918 Roadcurvature "Road curvature: Estimated value of the current road curvature for use by the adaptive cruise control system.  Positive values are used for left curves.  Curvature is the inverse of the radius and is zero for straight roads.";
CM_ SG_ 2432593918 Speedofforwardvehicle "Speed of forward vehicle: Absolute velocity of the preceding vehicle situated within 250 m in the same lane and moving in the same direction.The value of FFh indicates that no vehicle is detected.";
CM_ BO_ 2432595710 "Laser Leveling System Vertical Position Display Data";
CM_ SG_ 2432595710 DisplayDeadbands "Display Deadbands: Sets Display Deadbands mode.0000b = Narrow = +/- 4.5mm0001b = Standard = +/- 12mm0010b = Wide = +/- 24mm0011b to 1110b = Reserved1111b = Not Available";
CM_ SG_ 2432595710 LEDDisplayData1 "LED Display Data #1: Informs display devices how to display the current vertical position.Values which are less than 128 decimal are bit-mapped values and any combination of these values is considered a valid value.  For example communicating the Hig...";
CM_ SG_ 2432595710 LEDDisplayDeadbandControl "LED Display Deadband Control: This parameter informs the system what the selected Display deadband will be.0000b = +/- 4.5 mm  (0.015 feet, 0.18 inches)0001b = +/- 12 mm   (0.040 feet, 0.45 inches)0010b = +/- 24 mm   (0.080 feet, 0.96 inches)0011b = ...";
CM_ SG_ 2432595710 LEDDisplayModeControl "LED Display Mode Control: This parameter informs the system what the selected Display mode will be.0000b = Center On-Grade Display Mode 1 ( 5 CHANNEL )0001b = Offset On-Grade Display Mode 0010b = Center On-Grade Display Mode 2 ( 7 CHANNEL )0011b to 1...";
CM_ SG_ 2432595710 LEDPatternControl "LED Pattern Control: Sets LED Pattern control mode on laser leveling systems.0000b = 5 Channel0001b = Offset0010b = 7 Channel0011b to 1110b = Reserved1111b = Not Available";
CM_ BO_ 2498776830 "Engine Cylinder 1 Combustion Average Information";
CM_ SG_ 2498776830 EngnClndr1AvrgCmstnDrtn "Engine Cylinder 1 Average Combustion Duration: Average duration of combustion calculated over defined number of combustion cycles for engine cylinder 1 with reference to the crank angle.  Combustion duration is the difference between end of combustio...";
CM_ SG_ 2498776830 EngnClndr1AvrgCntrfCmstnTmng "Engine Cylinder 1 Average Center of Combustion Timing: Average timing calculated over defined number of combustion cycles for the center of combustion in engine cylinder 1 with reference to the crank angle.  Center of Combustion is used to indicate t...";
CM_ SG_ 2498776830 EngnClndr1AvrgStrtfCmstnTmng "Engine Cylinder 1 Average Start of Combustion Timing: Average start of combustion timing calculated over defined number of combustion cycles for engine cylinder 1 with reference to the crank angle.  When the combustion happens after the TDC (Top Dead...";
CM_ SG_ 2498776830 EngnClndr1IndtdMnEfftvPrssr "Engine Cylinder 1 Indicated Mean Effective Pressure: Average cylinder pressure calculated over defined number of combustion cycles for engine cylinder 1.   Negative range is to cover thermodynamic behavior during misfire.";
CM_ BO_ 2498777086 "Engine Cylinder 2 Combustion Average Information";
CM_ SG_ 2498777086 EngnClndr2AvrgCmstnDrtn "Engine Cylinder 2 Average Combustion Duration: Average duration of combustion calculated over defined number of combustion cycles for engine cylinder 2 with reference to the crank angle.  Combustion duration is the difference between end of combustio...";
CM_ SG_ 2498777086 EngnClndr2AvrgCntrfCmstnTmng "Engine Cylinder 2 Average Center of Combustion Timing: Average timing calculated over defined number of combustion cycles for the center of combustion in engine cylinder 2 with reference to the crank angle.  Center of Combustion is used to indicate t...";
CM_ SG_ 2498777086 EngnClndr2AvrgStrtfCmstnTmng "Engine Cylinder 2 Average Start of Combustion Timing: Average start of combustion timing calculated over defined number of combustion cycles for engine cylinder 2 with reference to the crank angle.  When the combustion happens after the TDC (Top Dead...";
CM_ SG_ 2498777086 EngnClndr2IndtdMnEfftvPrssr "Engine Cylinder 2 Indicated Mean Effective Pressure: Average cylinder pressure calculated over defined number of combustion cycles for engine cylinder 2.  Negative range is to cover thermodynamic behavior during misfire.";
CM_ BO_ 2498777342 "Engine Cylinder 3 Combustion Average Information";
CM_ SG_ 2498777342 EngnClndr3AvrgCmstnDrtn "Engine Cylinder 3 Average Combustion Duration: Average duration of combustion calculated over defined number of combustion cycles for engine cylinder 3 with reference to the crank angle.  Combustion duration is the difference between end of combustio...";
CM_ SG_ 2498777342 EngnClndr3AvrgCntrfCmstnTmng "Engine Cylinder 3 Average Center of Combustion Timing: Average timing calculated over defined number of combustion cycles for the center of combustion in engine cylinder 3 with reference to the crank angle.  Center of Combustion is used to indicate t...";
CM_ SG_ 2498777342 EngnClndr3AvrgStrtfCmstnTmng "Engine Cylinder 3 Average Start of Combustion Timing: Average start of combustion timing calculated over defined number of combustion cycles for engine cylinder 3 with reference to the crank angle.  When the combustion happens after the TDC (Top Dead...";
CM_ SG_ 2498777342 EngnClndr3IndtdMnEfftvPrssr "Engine Cylinder 3 Indicated Mean Effective Pressure: Average cylinder pressure calculated over defined number of combustion cycles for engine cylinder 3.  Negative range is to cover thermodynamic behavior during misfire.";
CM_ BO_ 2498777598 "Engine Cylinder 4 Combustion Average Information";
CM_ SG_ 2498777598 EngnClndr4AvrgCmstnDrtn "Engine Cylinder 4 Average Combustion Duration: Average duration of combustion calculated over defined number of combustion cycles for engine cylinder 4 with reference to the crank angle.  Combustion duration is the difference between end of combustio...";
CM_ SG_ 2498777598 EngnClndr4AvrgCntrfCmstnTmng "Engine Cylinder 4 Average Center of Combustion Timing: Average timing calculated over defined number of combustion cycles for the center of combustion in engine cylinder 4 with reference to the crank angle.  Center of Combustion is used to indicate t...";
CM_ SG_ 2498777598 EngnClndr4AvrgStrtfCmstnTmng "Engine Cylinder 4 Average Start of Combustion Timing: Average start of combustion timing calculated over defined number of combustion cycles for engine cylinder 4 with reference to the crank angle.  When the combustion happens after the TDC (Top Dead...";
CM_ SG_ 2498777598 EngnClndr4IndtdMnEfftvPrssr "Engine Cylinder 4 Indicated Mean Effective Pressure: Average cylinder pressure calculated over defined number of combustion cycles for engine cylinder 4.  Negative range is to cover thermodynamic behavior during misfire.";
CM_ BO_ 2498777854 "Engine Cylinder 5 Combustion Average Information";
CM_ SG_ 2498777854 EngnClndr5AvrgCmstnDrtn "Engine Cylinder 5 Average Combustion Duration: Average duration of combustion calculated over defined number of combustion cycles for engine cylinder 5 with reference to the crank angle.  Combustion duration is the difference between end of combustio...";
CM_ SG_ 2498777854 EngnClndr5AvrgCntrfCmstnTmng "Engine Cylinder 5 Average Center of Combustion Timing: Average timing calculated over defined number of combustion cycles for the center of combustion in engine cylinder 5 with reference to the crank angle.  Center of Combustion is used to indicate t...";
CM_ SG_ 2498777854 EngnClndr5AvrgStrtfCmstnTmng "Engine Cylinder 5 Average Start of Combustion Timing: Average start of combustion timing calculated over defined number of combustion cycles for engine cylinder 5 with reference to the crank angle.  When the combustion happens after the TDC (Top Dead...";
CM_ SG_ 2498777854 EngnClndr5IndtdMnEfftvPrssr "Engine Cylinder 5 Indicated Mean Effective Pressure: Average cylinder pressure calculated over defined number of combustion cycles for engine cylinder 5.  Negative range is to cover thermodynamic behavior during misfire.";
CM_ BO_ 2498778110 "Engine Cylinder 6 Combustion Average Information";
CM_ SG_ 2498778110 EngnClndr6AvrgCmstnDrtn "Engine Cylinder 6 Average Combustion Duration: Average duration of combustion calculated over defined number of combustion cycles for engine cylinder 6 with reference to the crank angle.  Combustion duration is the difference between end of combustio...";
CM_ SG_ 2498778110 EngnClndr6AvrgCntrfCmstnTmng "Engine Cylinder 6 Average Center of Combustion Timing: Average timing calculated over defined number of combustion cycles for the center of combustion in engine cylinder 6 with reference to the crank angle.  Center of Combustion is used to indicate t...";
CM_ SG_ 2498778110 EngnClndr6AvrgStrtfCmstnTmng "Engine Cylinder 6 Average Start of Combustion Timing: Average start of combustion timing calculated over defined number of combustion cycles for engine cylinder 6 with reference to the crank angle.  When the combustion happens after the TDC (Top Dead...";
CM_ SG_ 2498778110 EngnClndr6IndtdMnEfftvPrssr "Engine Cylinder 6 Indicated Mean Effective Pressure: Average cylinder pressure calculated over defined number of combustion cycles for engine cylinder 6.  Negative range is to cover thermodynamic behavior during misfire.";
CM_ BO_ 2498778366 "Engine Cylinder 7 Combustion Average Information";
CM_ SG_ 2498778366 EngnClndr7AvrgCmstnDrtn "Engine Cylinder 7 Average Combustion Duration: Average duration of combustion calculated over defined number of combustion cycles for engine cylinder 7 with reference to the crank angle.  Combustion duration is the difference between end of combustio...";
CM_ SG_ 2498778366 EngnClndr7AvrgCntrfCmstnTmng "Engine Cylinder 7 Average Center of Combustion Timing: Average timing calculated over defined number of combustion cycles for the center of combustion in engine cylinder 7 with reference to the crank angle.  Center of Combustion is used to indicate t...";
CM_ SG_ 2498778366 EngnClndr7AvrgStrtfCmstnTmng "Engine Cylinder 7 Average Start of Combustion Timing: Average start of combustion timing calculated over defined number of combustion cycles for engine cylinder 7 with reference to the crank angle.  When the combustion happens after the TDC (Top Dead...";
CM_ SG_ 2498778366 EngnClndr7IndtdMnEfftvPrssr "Engine Cylinder 7 Indicated Mean Effective Pressure: Average cylinder pressure calculated over defined number of combustion cycles for engine cylinder 7.  Negative range is to cover thermodynamic behavior during misfire.";
CM_ BO_ 2498778622 "Engine Cylinder 8 Combustion Average Information";
CM_ SG_ 2498778622 EngnClndr8AvrgCmstnDrtn "Engine Cylinder 8 Average Combustion Duration: Average duration of combustion calculated over defined number of combustion cycles for engine cylinder 8 with reference to the crank angle.  Combustion duration is the difference between end of combustio...";
CM_ SG_ 2498778622 EngnClndr8AvrgCntrfCmstnTmng "Engine Cylinder 8 Average Center of Combustion Timing: Average timing calculated over defined number of combustion cycles for the center of combustion in engine cylinder 8 with reference to the crank angle.  Center of Combustion is used to indicate t...";
CM_ SG_ 2498778622 EngnClndr8AvrgStrtfCmstnTmng "Engine Cylinder 8 Average Start of Combustion Timing: Average start of combustion timing calculated over defined number of combustion cycles for engine cylinder 8 with reference to the crank angle.  When the combustion happens after the TDC (Top Dead...";
CM_ SG_ 2498778622 EngnClndr8IndtdMnEfftvPrssr "Engine Cylinder 8 Indicated Mean Effective Pressure: Average cylinder pressure calculated over defined number of combustion cycles for engine cylinder 8.  Negative range is to cover thermodynamic behavior during misfire.";
CM_ BO_ 2498778878 "Engine Cylinder 9 Combustion Average Information";
CM_ SG_ 2498778878 EngnClndr9AvrgCmstnDrtn "Engine Cylinder 9 Average Combustion Duration: Average duration of combustion calculated over defined number of combustion cycles for engine cylinder 9 with reference to the crank angle.  Combustion duration is the difference between end of combustio...";
CM_ SG_ 2498778878 EngnClndr9AvrgCntrfCmstnTmng "Engine Cylinder 9 Average Center of Combustion Timing: Average timing calculated over defined number of combustion cycles for the center of combustion in engine cylinder 9 with reference to the crank angle.  Center of Combustion is used to indicate t...";
CM_ SG_ 2498778878 EngnClndr9AvrgStrtfCmstnTmng "Engine Cylinder 9 Average Start of Combustion Timing: Average start of combustion timing calculated over defined number of combustion cycles for engine cylinder 9 with reference to the crank angle.  When the combustion happens after the TDC (Top Dead...";
CM_ SG_ 2498778878 EngnClndr9IndtdMnEfftvPrssr "Engine Cylinder 9 Indicated Mean Effective Pressure: Average cylinder pressure calculated over defined number of combustion cycles for engine cylinder 9.  Negative range is to cover thermodynamic behavior during misfire.";
CM_ BO_ 2498779134 "Engine Cylinder 10 Combustion Average Information";
CM_ SG_ 2498779134 EngnClndr10AvrgCmstnDrtn "Engine Cylinder 10 Average Combustion Duration: Average duration of combustion calculated over defined number of combustion cycles for engine cylinder 10 with reference to the crank angle.  Combustion duration is the difference between end of combust...";
CM_ SG_ 2498779134 EngnClndr10AvrgCntrfCmstnTmng "Engine Cylinder 10 Average Center of Combustion Timing: Average timing calculated over defined number of combustion cycles for the center of combustion in engine cylinder 10 with reference to the crank angle.  Center of Combustion is used to indicate...";
CM_ SG_ 2498779134 EngnClndr10AvrgStrtfCmstnTmng "Engine Cylinder 10 Average Start of Combustion Timing: Average start of combustion timing calculated over defined number of combustion cycles for engine cylinder 10 with reference to the crank angle.  When the combustion happens after the TDC (Top De...";
CM_ SG_ 2498779134 EngnClndr10IndtdMnEfftvPrssr "Engine Cylinder 10 Indicated Mean Effective Pressure: Average cylinder pressure calculated over defined number of combustion cycles for engine cylinder 10.  Negative range is to cover thermodynamic behavior during misfire.";
CM_ BO_ 2498779390 "Engine Cylinder 11 Combustion Average Information";
CM_ SG_ 2498779390 EngnClndr11AvrgCmstnDrtn "Engine Cylinder 11 Average Combustion Duration: Average duration of combustion calculated over defined number of combustion cycles for engine cylinder 11 with reference to the crank angle.  Combustion duration is the difference between end of combust...";
CM_ SG_ 2498779390 EngnClndr11AvrgCntrfCmstnTmng "Engine Cylinder 11 Average Center of Combustion Timing: Average timing calculated over defined number of combustion cycles for the center of combustion in engine cylinder 11 with reference to the crank angle.  Center of Combustion is used to indicate...";
CM_ SG_ 2498779390 EngnClndr11AvrgStrtfCmstnTmng "Engine Cylinder 11 Average Start of Combustion Timing: Average start of combustion timing calculated over defined number of combustion cycles for engine cylinder 11 with reference to the crank angle.  When the combustion happens after the TDC (Top De...";
CM_ SG_ 2498779390 EngnClndr11IndtdMnEfftvPrssr "Engine Cylinder 11 Indicated Mean Effective Pressure: Average cylinder pressure calculated over defined number of combustion cycles for engine cylinder 11.  Negative range is to cover thermodynamic behavior during misfire.";
CM_ BO_ 2498779646 "Engine Cylinder 12 Combustion Average Information";
CM_ SG_ 2498779646 EngnClndr12AvrgCmstnDrtn "Engine Cylinder 12 Average Combustion Duration: Average duration of combustion calculated over defined number of combustion cycles for engine cylinder 12 with reference to the crank angle.  Combustion duration is the difference between end of combust...";
CM_ SG_ 2498779646 EngnClndr12AvrgCntrfCmstnTmng "Engine Cylinder 12 Average Center of Combustion Timing: Average timing calculated over defined number of combustion cycles for the center of combustion in engine cylinder 12 with reference to the crank angle.  Center of Combustion is used to indicate...";
CM_ SG_ 2498779646 EngnClndr12AvrgStrtfCmstnTmng "Engine Cylinder 12 Average Start of Combustion Timing: Average start of combustion timing calculated over defined number of combustion cycles for engine cylinder 12 with reference to the crank angle.  When the combustion happens after the TDC (Top De...";
CM_ SG_ 2498779646 EngnClndr12IndtdMnEfftvPrssr "Engine Cylinder 12 Indicated Mean Effective Pressure: Average cylinder pressure calculated over defined number of combustion cycles for engine cylinder 12.  Negative range is to cover thermodynamic behavior during misfire.";
CM_ BO_ 2498779902 "Engine Cylinder 13 Combustion Average Information";
CM_ SG_ 2498779902 EngnClndr13AvrgCmstnDrtn "Engine Cylinder 13 Average Combustion Duration: Average duration of combustion calculated over defined number of combustion cycles for engine cylinder 13 with reference to the crank angle.  Combustion duration is the difference between end of combust...";
CM_ SG_ 2498779902 EngnClndr13AvrgCntrfCmstnTmng "Engine Cylinder 13 Average Center of Combustion Timing: Average timing calculated over defined number of combustion cycles for the center of combustion in engine cylinder 13 with reference to the crank angle.  Center of Combustion is used to indicate...";
CM_ SG_ 2498779902 EngnClndr13AvrgStrtfCmstnTmng "Engine Cylinder 13 Average Start of Combustion Timing: Average start of combustion timing calculated over defined number of combustion cycles for engine cylinder 13 with reference to the crank angle.  When the combustion happens after the TDC (Top De...";
CM_ SG_ 2498779902 EngnClndr13IndtdMnEfftvPrssr "Engine Cylinder 13 Indicated Mean Effective Pressure: Average cylinder pressure calculated over defined number of combustion cycles for engine cylinder 13.  Negative range is to cover thermodynamic behavior during misfire.";
CM_ BO_ 2498780158 "Engine Cylinder 14 Combustion Average Information";
CM_ SG_ 2498780158 EngnClndr14AvrgCmstnDrtn "Engine Cylinder 14 Average Combustion Duration: Average duration of combustion calculated over defined number of combustion cycles for engine cylinder 14 with reference to the crank angle.  Combustion duration is the difference between end of combust...";
CM_ SG_ 2498780158 EngnClndr14AvrgCntrfCmstnTmng "Engine Cylinder 14 Average Center of Combustion Timing: Average timing calculated over defined number of combustion cycles for the center of combustion in engine cylinder 14 with reference to the crank angle.  Center of Combustion is used to indicate...";
CM_ SG_ 2498780158 EngnClndr14AvrgStrtfCmstnTmng "Engine Cylinder 14 Average Start of Combustion Timing: Average start of combustion timing calculated over defined number of combustion cycles for engine cylinder 14 with reference to the crank angle.  When the combustion happens after the TDC (Top De...";
CM_ SG_ 2498780158 EngnClndr14IndtdMnEfftvPrssr "Engine Cylinder 14 Indicated Mean Effective Pressure: Average cylinder pressure calculated over defined number of combustion cycles for engine cylinder 14.  Negative range is to cover thermodynamic behavior during misfire.";
CM_ BO_ 2498780414 "Engine Cylinder 15 Combustion Average Information";
CM_ SG_ 2498780414 EngnClndr15AvrgCmstnDrtn "Engine Cylinder 15 Average Combustion Duration: Average duration of combustion calculated over defined number of combustion cycles for engine cylinder 15 with reference to the crank angle.  Combustion duration is the difference between end of combust...";
CM_ SG_ 2498780414 EngnClndr15AvrgCntrfCmstnTmng "Engine Cylinder 15 Average Center of Combustion Timing: Average timing calculated over defined number of combustion cycles for the center of combustion in engine cylinder 15 with reference to the crank angle.  Center of Combustion is used to indicate...";
CM_ SG_ 2498780414 EngnClndr15AvrgStrtfCmstnTmng "Engine Cylinder 15 Average Start of Combustion Timing: Average start of combustion timing calculated over defined number of combustion cycles for engine cylinder 15 with reference to the crank angle.  When the combustion happens after the TDC (Top De...";
CM_ SG_ 2498780414 EngnClndr15IndtdMnEfftvPrssr "Engine Cylinder 15 Indicated Mean Effective Pressure: Average cylinder pressure calculated over defined number of combustion cycles for engine cylinder 15.  Negative range is to cover thermodynamic behavior during misfire.";
CM_ BO_ 2498780670 "Engine Cylinder 16 Combustion Average Information";
CM_ SG_ 2498780670 EngnClndr16AvrgCmstnDrtn "Engine Cylinder 16 Average Combustion Duration: Average duration of combustion calculated over defined number of combustion cycles for engine cylinder 16 with reference to the crank angle.  Combustion duration is the difference between end of combust...";
CM_ SG_ 2498780670 EngnClndr16AvrgCntrfCmstnTmng "Engine Cylinder 16 Average Center of Combustion Timing: Average timing calculated over defined number of combustion cycles for the center of combustion in engine cylinder 16 with reference to the crank angle.  Center of Combustion is used to indicate...";
CM_ SG_ 2498780670 EngnClndr16AvrgStrtfCmstnTmng "Engine Cylinder 16 Average Start of Combustion Timing: Average start of combustion timing calculated over defined number of combustion cycles for engine cylinder 16 with reference to the crank angle.  When the combustion happens after the TDC (Top De...";
CM_ SG_ 2498780670 EngnClndr16IndtdMnEfftvPrssr "Engine Cylinder 16 Indicated Mean Effective Pressure: Average cylinder pressure calculated over defined number of combustion cycles for engine cylinder 16.  Negative range is to cover thermodynamic behavior during misfire.";
CM_ BO_ 2498780926 "Engine Cylinder 17 Combustion Average Information";
CM_ SG_ 2498780926 EngnClndr17AvrgCmstnDrtn "Engine Cylinder 17 Average Combustion Duration: Average duration of combustion calculated over defined number of combustion cycles for engine cylinder 17 with reference to the crank angle.  Combustion duration is the difference between end of combust...";
CM_ SG_ 2498780926 EngnClndr17AvrgCntrfCmstnTmng "Engine Cylinder 17 Average Center of Combustion Timing: Average timing calculated over defined number of combustion cycles for the center of combustion in engine cylinder 17 with reference to the crank angle.  Center of Combustion is used to indicate...";
CM_ SG_ 2498780926 EngnClndr17AvrgStrtfCmstnTmng "Engine Cylinder 17 Average Start of Combustion Timing: Average start of combustion timing calculated over defined number of combustion cycles for engine cylinder 17 with reference to the crank angle.  When the combustion happens after the TDC (Top De...";
CM_ SG_ 2498780926 EngnClndr17IndtdMnEfftvPrssr "Engine Cylinder 17 Indicated Mean Effective Pressure: Average cylinder pressure calculated over defined number of combustion cycles for engine cylinder 17.  Negative range is to cover thermodynamic behavior during misfire.";
CM_ BO_ 2498781182 "Engine Cylinder 18 Combustion Average Information";
CM_ SG_ 2498781182 EngnClndr18AvrgCmstnDrtn "Engine Cylinder 18 Average Combustion Duration: Average duration of combustion calculated over defined number of combustion cycles for engine cylinder 18 with reference to the crank angle.  Combustion duration is the difference between end of combust...";
CM_ SG_ 2498781182 EngnClndr18AvrgCntrfCmstnTmng "Engine Cylinder 18 Average Center of Combustion Timing: Average timing calculated over defined number of combustion cycles for the center of combustion in engine cylinder 18 with reference to the crank angle.  Center of Combustion is used to indicate...";
CM_ SG_ 2498781182 EngnClndr18AvrgStrtfCmstnTmng "Engine Cylinder 18 Average Start of Combustion Timing: Average start of combustion timing calculated over defined number of combustion cycles for engine cylinder 18 with reference to the crank angle.  When the combustion happens after the TDC (Top De...";
CM_ SG_ 2498781182 EngnClndr18IndtdMnEfftvPrssr "Engine Cylinder 18 Indicated Mean Effective Pressure: Average cylinder pressure calculated over defined number of combustion cycles for engine cylinder 18.  Negative range is to cover thermodynamic behavior during misfire.";
CM_ BO_ 2498781438 "Engine Cylinder 19 Combustion Average Information";
CM_ SG_ 2498781438 EngnClndr19AvrgCmstnDrtn "Engine Cylinder 19 Average Combustion Duration: Average duration of combustion calculated over defined number of combustion cycles for engine cylinder 19 with reference to the crank angle.  Combustion duration is the difference between end of combust...";
CM_ SG_ 2498781438 EngnClndr19AvrgCntrfCmstnTmng "Engine Cylinder 19 Average Center of Combustion Timing: Average timing calculated over defined number of combustion cycles for the center of combustion in engine cylinder 19 with reference to the crank angle.  Center of Combustion is used to indicate...";
CM_ SG_ 2498781438 EngnClndr19AvrgStrtfCmstnTmng "Engine Cylinder 19 Average Start of Combustion Timing: Average start of combustion timing calculated over defined number of combustion cycles for engine cylinder 19 with reference to the crank angle.  When the combustion happens after the TDC (Top De...";
CM_ SG_ 2498781438 EngnClndr19IndtdMnEfftvPrssr "Engine Cylinder 19 Indicated Mean Effective Pressure: Average cylinder pressure calculated over defined number of combustion cycles for engine cylinder 19.  Negative range is to cover thermodynamic behavior during misfire.";
CM_ BO_ 2498781694 "Engine Cylinder 20 Combustion Average Information";
CM_ SG_ 2498781694 EngnClndr20AvrgCmstnDrtn "Engine Cylinder 20 Average Combustion Duration: Average duration of combustion calculated over defined number of combustion cycles for engine cylinder 20 with reference to the crank angle.  Combustion duration is the difference between end of combust...";
CM_ SG_ 2498781694 EngnClndr20AvrgCntrfCmstnTmng "Engine Cylinder 20 Average Center of Combustion Timing: Average timing calculated over defined number of combustion cycles for the center of combustion in engine cylinder 20 with reference to the crank angle.  Center of Combustion is used to indicate...";
CM_ SG_ 2498781694 EngnClndr20AvrgStrtfCmstnTmng "Engine Cylinder 20 Average Start of Combustion Timing: Average start of combustion timing calculated over defined number of combustion cycles for engine cylinder 20 with reference to the crank angle.  When the combustion happens after the TDC (Top De...";
CM_ SG_ 2498781694 EngnClndr20IndtdMnEfftvPrssr "Engine Cylinder 20 Indicated Mean Effective Pressure: Average cylinder pressure calculated over defined number of combustion cycles for engine cylinder 20.  Negative range is to cover thermodynamic behavior during misfire.";
BA_DEF_ SG_  "SPN" INT 0 524287;
BA_DEF_ BO_  "VFrameFormat" ENUM  "StandardCAN","ExtendedCAN","reserved","J1939PG";
BA_DEF_DEF_  "SPN" 0;
BA_DEF_DEF_  "VFrameFormat" "J1939PG";
BA_ "SPN" SG_ 2365446142 Joystick1Button13PressedStatus 6731;
BA_ "SPN" SG_ 2365446142 Joystick1Button14PressedStatus 6732;
BA_ "SPN" SG_ 2365446142 Joystick1Button15PressedStatus 6733;
BA_ "SPN" SG_ 2365446142 Joystick1Button16PressedStatus 6734;
BA_ "SPN" SG_ 2365446142 Joystick1GripXAxisPosition 2662;
BA_ "SPN" SG_ 2365446142 Joystick1GripYAxisPosition 2663;
BA_ "SPN" SG_ 2365446142 Joystick1ThetaAxisPosition 2664;
BA_ "SPN" SG_ 2365446142 Jst1GpYAxsLvFwdPstvPstStts 2668;
BA_ "SPN" SG_ 2365446142 Jst1TtAxsCtCwsNtvPstStts 2674;
BA_ "SPN" SG_ 2365446142 Jstk1GrpXAxsDtntPstnStts 2682;
BA_ "SPN" SG_ 2365446142 Jstk1GrpXAxsLvrLftNgtvPstnStts 2672;
BA_ "SPN" SG_ 2365446142 Jstk1GrpXAxsLvrRghtPstvPstnStts 2667;
BA_ "SPN" SG_ 2365446142 Jstk1GrpXAxsNtrlPstnStts 2677;
BA_ "SPN" SG_ 2365446142 Jstk1GrpYAxsDtntPstnStts 2683;
BA_ "SPN" SG_ 2365446142 Jstk1GrpYAxsLvrBkNgtvPstnStts 2673;
BA_ "SPN" SG_ 2365446142 Jstk1GrpYAxsNtrlPstnStts 2678;
BA_ "SPN" SG_ 2365446142 Jstk1ThtAxsClkwsPstvPstnStts 2669;
BA_ "SPN" SG_ 2365446142 Jstk1ThtAxsDtntPstnStts 2684;
BA_ "SPN" SG_ 2365446142 Jstk1ThtAxsNtrlPstnStts 2679;
BA_ "SPN" SG_ 2365446398 Joystick2Button10PressedStatus 2731;
BA_ "SPN" SG_ 2365446398 Joystick2Button11PressedStatus 2732;
BA_ "SPN" SG_ 2365446398 Joystick2Button12PressedStatus 2733;
BA_ "SPN" SG_ 2365446398 Joystick2Button1PressedStatus 2722;
BA_ "SPN" SG_ 2365446398 Joystick2Button2PressedStatus 2723;
BA_ "SPN" SG_ 2365446398 Joystick2Button3PressedStatus 2724;
BA_ "SPN" SG_ 2365446398 Joystick2Button4PressedStatus 2725;
BA_ "SPN" SG_ 2365446398 Joystick2Button5PressedStatus 2726;
BA_ "SPN" SG_ 2365446398 Joystick2Button6PressedStatus 2727;
BA_ "SPN" SG_ 2365446398 Joystick2Button7PressedStatus 2728;
BA_ "SPN" SG_ 2365446398 Joystick2Button8PressedStatus 2729;
BA_ "SPN" SG_ 2365446398 Joystick2Button9PressedStatus 2730;
BA_ "SPN" SG_ 2365446398 Joystick2XAxisPosition 2697;
BA_ "SPN" SG_ 2365446398 Joystick2YAxisPosition 2698;
BA_ "SPN" SG_ 2365446398 Jstk2XAxsDtntPstnStts 2717;
BA_ "SPN" SG_ 2365446398 Jstk2XAxsLvrLftNgtvPstnStts 2707;
BA_ "SPN" SG_ 2365446398 Jstk2XAxsLvrRghtPstvPstnStts 2702;
BA_ "SPN" SG_ 2365446398 Jstk2XAxsNtrlPstnStts 2712;
BA_ "SPN" SG_ 2365446398 Jstk2YAxsDtntPstnStts 2718;
BA_ "SPN" SG_ 2365446398 Jstk2YAxsLvrBkNgtvPstnStts 2708;
BA_ "SPN" SG_ 2365446398 Jstk2YAxsLvrFrwrdPstvPstnStts 2703;
BA_ "SPN" SG_ 2365446398 Jstk2YAxsNtrlPstnStts 2713;
BA_ "SPN" SG_ 2365446654 Joystick2Button13PressedStatus 6735;
BA_ "SPN" SG_ 2365446654 Joystick2Button14PressedStatus 6736;
BA_ "SPN" SG_ 2365446654 Joystick2Button15PressedStatus 6737;
BA_ "SPN" SG_ 2365446654 Joystick2Button16PressedStatus 6738;
BA_ "SPN" SG_ 2365446654 Joystick2GripXAxisPosition 2699;
BA_ "SPN" SG_ 2365446654 Joystick2GripYAxisPosition 2700;
BA_ "SPN" SG_ 2365446654 Joystick2ThetaAxisPosition 2701;
BA_ "SPN" SG_ 2365446654 Jst2GpYAxsLvFwdPstvPstStts 2705;
BA_ "SPN" SG_ 2365446654 Jst2TtAxsCtCwsNtvPstStts 2711;
BA_ "SPN" SG_ 2365446654 Jstk2GrpXAxsDtntPstnStts 2719;
BA_ "SPN" SG_ 2365446654 Jstk2GrpXAxsLvrLftNgtvPstnStts 2709;
BA_ "SPN" SG_ 2365446654 Jstk2GrpXAxsLvrRghtPstvPstnStts 2704;
BA_ "SPN" SG_ 2365446654 Jstk2GrpXAxsNtrlPstnStts 2714;
BA_ "SPN" SG_ 2365446654 Jstk2GrpYAxsDtntPstnStts 2720;
BA_ "SPN" SG_ 2365446654 Jstk2GrpYAxsLvrBkNgtvPstnStts 2710;
BA_ "SPN" SG_ 2365446654 Jstk2GrpYAxsNtrlPstnStts 2715;
BA_ "SPN" SG_ 2365446654 Jstk2ThtAxsClkwsPstvPstnStts 2706;
BA_ "SPN" SG_ 2365446654 Jstk2ThtAxsDtntPstnStts 2721;
BA_ "SPN" SG_ 2365446654 Jstk2ThtAxsNtrlPstnStts 2716;
BA_ "SPN" SG_ 2365446910 Joystick3Button10PressedStatus 2768;
BA_ "SPN" SG_ 2365446910 Joystick3Button11PressedStatus 2769;
BA_ "SPN" SG_ 2365446910 Joystick3Button12PressedStatus 2770;
BA_ "SPN" SG_ 2365446910 Joystick3Button1PressedStatus 2759;
BA_ "SPN" SG_ 2365446910 Joystick3Button2PressedStatus 2760;
BA_ "SPN" SG_ 2365446910 Joystick3Button3PressedStatus 2761;
BA_ "SPN" SG_ 2365446910 Joystick3Button4PressedStatus 2762;
BA_ "SPN" SG_ 2365446910 Joystick3Button5PressedStatus 2763;
BA_ "SPN" SG_ 2365446910 Joystick3Button6PressedStatus 2764;
BA_ "SPN" SG_ 2365446910 Joystick3Button7PressedStatus 2765;
BA_ "SPN" SG_ 2365446910 Joystick3Button8PressedStatus 2766;
BA_ "SPN" SG_ 2365446910 Joystick3Button9PressedStatus 2767;
BA_ "SPN" SG_ 2365446910 Joystick3XAxisPosition 2734;
BA_ "SPN" SG_ 2365446910 Joystick3YAxisPosition 2735;
BA_ "SPN" SG_ 2365446910 Jstk3XAxsDtntPstnStts 2754;
BA_ "SPN" SG_ 2365446910 Jstk3XAxsLvrLftNgtvPstnStts 2744;
BA_ "SPN" SG_ 2365446910 Jstk3XAxsLvrRghtPstvPstnStts 2739;
BA_ "SPN" SG_ 2365446910 Jstk3XAxsNtrlPstnStts 2749;
BA_ "SPN" SG_ 2365446910 Jstk3YAxsDtntPstnStts 2755;
BA_ "SPN" SG_ 2365446910 Jstk3YAxsLvrBkNgtvPstnStts 2745;
BA_ "SPN" SG_ 2365446910 Jstk3YAxsLvrFrwrdPstvPstnStts 2740;
BA_ "SPN" SG_ 2365446910 Jstk3YAxsNtrlPstnStts 2750;
BA_ "SPN" SG_ 2365447166 Joystick3Button13PressedStatus 6739;
BA_ "SPN" SG_ 2365447166 Joystick3Button14PressedStatus 6740;
BA_ "SPN" SG_ 2365447166 Joystick3Button15PressedStatus 6741;
BA_ "SPN" SG_ 2365447166 Joystick3Button16PressedStatus 6742;
BA_ "SPN" SG_ 2365447166 Joystick3GripXAxisPosition 2736;
BA_ "SPN" SG_ 2365447166 Joystick3GripYAxisPosition 2737;
BA_ "SPN" SG_ 2365447166 Joystick3ThetaAxisPosition 2738;
BA_ "SPN" SG_ 2365447166 Jst3GpYAxsLvFwdPstvPstStts 2742;
BA_ "SPN" SG_ 2365447166 Jst3TtAxsCtCwsNtvPstStts 2748;
BA_ "SPN" SG_ 2365447166 Jstk3GrpXAxsDtntPstnStts 2756;
BA_ "SPN" SG_ 2365447166 Jstk3GrpXAxsLvrLftNgtvPstnStts 2746;
BA_ "SPN" SG_ 2365447166 Jstk3GrpXAxsLvrRghtPstvPstnStts 2741;
BA_ "SPN" SG_ 2365447166 Jstk3GrpXAxsNtrlPstnStts 2751;
BA_ "SPN" SG_ 2365447166 Jstk3GrpYAxsDtntPstnStts 2757;
BA_ "SPN" SG_ 2365447166 Jstk3GrpYAxsLvrBkNgtvPstnStts 2747;
BA_ "SPN" SG_ 2365447166 Jstk3GrpYAxsNtrlPstnStts 2752;
BA_ "SPN" SG_ 2365447166 Jstk3ThtAxsClkwsPstvPstnStts 2743;
BA_ "SPN" SG_ 2365447166 Jstk3ThtAxsDtntPstnStts 2758;
BA_ "SPN" SG_ 2365447166 Jstk3ThtAxsNtrlPstnStts 2753;
BA_ "SPN" SG_ 2365449982 HdrlBrkPrssrSpplSttCrt1 2582;
BA_ "SPN" SG_ 2365449982 HdrlBrkPrssrSpplSttCrt2 2583;
BA_ "SPN" SG_ 2365449982 HdrlBrkPrssrWrnngSttCrt1 2584;
BA_ "SPN" SG_ 2365449982 HdrlBrkPrssrWrnngSttCrt2 2585;
BA_ "SPN" SG_ 2365449982 HdrlBrkSstmAdlWrnngCmmnd 2930;
BA_ "SPN" SG_ 2365449982 HydraulicBrakeFluidLevelSwitch 2931;
BA_ "SPN" SG_ 2365449982 HydraulicBrakePressureCircuit1 2580;
BA_ "SPN" SG_ 2365449982 HydraulicBrakePressureCircuit2 2581;
BA_ "SPN" SG_ 2365450238 Bus1UtilityACPhaseDifference 2517;
BA_ "SPN" SG_ 2365450238 Bus1UtilityDeadBus 2535;
BA_ "SPN" SG_ 2365450238 Bus1UtilityFrequencyMatch 2533;
BA_ "SPN" SG_ 2365450238 Bus1UtilityInSync 2534;
BA_ "SPN" SG_ 2365450238 Bus1UtilityPhaseMatch 2531;
BA_ "SPN" SG_ 2365450238 Bus1UtilityVoltageMatch 2532;
BA_ "SPN" SG_ 2365450494 Bus1GeneratorACPhaseDifference 2516;
BA_ "SPN" SG_ 2365450494 Bus1GeneratorDeadBus 2530;
BA_ "SPN" SG_ 2365450494 Bus1GeneratorFrequencyMatch 2528;
BA_ "SPN" SG_ 2365450494 Bus1GeneratorInSync 2529;
BA_ "SPN" SG_ 2365450494 Bus1GeneratorPhaseMatch 2526;
BA_ "SPN" SG_ 2365450494 Bus1GeneratorVoltageMatch 2527;
BA_ "SPN" SG_ 2365450750 Bs1PhsCLnNtrlACRMSVltg 2515;
BA_ "SPN" SG_ 2365450750 Bus1PhaseCACFrequency 2507;
BA_ "SPN" SG_ 2365450750 Bus1PhaseCALineLineACRMSVoltage 2511;
BA_ "SPN" SG_ 2365451006 Bs1PhsBLnNtrlACRMSVltg 2514;
BA_ "SPN" SG_ 2365451006 Bus1PhaseBACFrequency 2506;
BA_ "SPN" SG_ 2365451006 Bus1PhaseBCLineLineACRMSVoltage 2510;
BA_ "SPN" SG_ 2365451262 Bs1PhsALnNtrlACRMSVltg 2513;
BA_ "SPN" SG_ 2365451262 Bus1PhaseAACFrequency 2505;
BA_ "SPN" SG_ 2365451262 Bus1PhaseABLineLineACRMSVoltage 2509;
BA_ "SPN" SG_ 2365451518 Bs1AvrgLnNtrlACRMSVltg 2512;
BA_ "SPN" SG_ 2365451518 Bus1AverageACFrequency 2504;
BA_ "SPN" SG_ 2365451518 Bus1AverageLineLineACRMSVoltage 2508;
BA_ "SPN" SG_ 2365451774 UtilityTotalkWHoursExport 2502;
BA_ "SPN" SG_ 2365451774 UtilityTotalkWHoursImport 2503;
BA_ "SPN" SG_ 2365452030 UtilityPhaseCPowerFactor 2501;
BA_ "SPN" SG_ 2365452030 UtilityPhaseCPowerFactorLagging 2525;
BA_ "SPN" SG_ 2365452030 UtilityPhaseCReactivePower 2493;
BA_ "SPN" SG_ 2365452286 UtilityPhaseCApparentPower 2497;
BA_ "SPN" SG_ 2365452286 UtilityPhaseCRealPower 2489;
BA_ "SPN" SG_ 2365452542 UtilityPhaseCACFrequency 2473;
BA_ "SPN" SG_ 2365452542 UtilityPhaseCACRMSCurrent 2485;
BA_ "SPN" SG_ 2365452542 UtltPhsCALnLnACRMSVltg 2477;
BA_ "SPN" SG_ 2365452542 UtltPhsCLnNtrlACRMSVltg 2481;
BA_ "SPN" SG_ 2365452798 UtilityPhaseBPowerFactor 2500;
BA_ "SPN" SG_ 2365452798 UtilityPhaseBPowerFactorLagging 2524;
BA_ "SPN" SG_ 2365452798 UtilityPhaseBReactivePower 2492;
BA_ "SPN" SG_ 2365453054 UtilityPhaseBApparentPower 2496;
BA_ "SPN" SG_ 2365453054 UtilityPhaseBRealPower 2488;
BA_ "SPN" SG_ 2365453310 UtilityPhaseBACFrequency 2472;
BA_ "SPN" SG_ 2365453310 UtilityPhaseBACRMSCurrent 2484;
BA_ "SPN" SG_ 2365453310 UtltPhsBCLnLnACRMSVltg 2476;
BA_ "SPN" SG_ 2365453310 UtltPhsBLnNtrlACRMSVltg 2480;
BA_ "SPN" SG_ 2365453566 UtilityPhaseAPowerFactor 2499;
BA_ "SPN" SG_ 2365453566 UtilityPhaseAPowerFactorLagging 2523;
BA_ "SPN" SG_ 2365453566 UtilityPhaseAReactivePower 2491;
BA_ "SPN" SG_ 2365453822 UtilityPhaseAApparentPower 2495;
BA_ "SPN" SG_ 2365453822 UtilityPhaseARealPower 2487;
BA_ "SPN" SG_ 2365454078 UtilityPhaseAACFrequency 2471;
BA_ "SPN" SG_ 2365454078 UtilityPhaseAACRMSCurrent 2483;
BA_ "SPN" SG_ 2365454078 UtltPhsABLnLnACRMSVltg 2475;
BA_ "SPN" SG_ 2365454078 UtltPhsALnNtrlACRMSVltg 2479;
BA_ "SPN" SG_ 2365454334 UtilityOverallPowerFactor 2498;
BA_ "SPN" SG_ 2365454334 UtilityTotalReactivePower 2490;
BA_ "SPN" SG_ 2365454334 UtltOvrllPwrFtrLggng 2522;
BA_ "SPN" SG_ 2365454590 UtilityTotalApparentPower 2494;
BA_ "SPN" SG_ 2365454590 UtilityTotalRealPower 2486;
BA_ "SPN" SG_ 2365454846 UtilityAverageACFrequency 2470;
BA_ "SPN" SG_ 2365454846 UtilityAverageACRMSCurrent 2482;
BA_ "SPN" SG_ 2365454846 UtltAvrgLnLnACRMSVltg 2474;
BA_ "SPN" SG_ 2365454846 UtltAvrgLnNtrlACRMSVltg 2478;
BA_ "SPN" SG_ 2365455102 GeneratorTotalkWHoursExport 2468;
BA_ "SPN" SG_ 2365455102 GeneratorTotalkWHoursImport 2469;
BA_ "SPN" SG_ 2365455358 GeneratorPhaseCPowerFactor 2467;
BA_ "SPN" SG_ 2365455358 GeneratorPhaseCReactivePower 2459;
BA_ "SPN" SG_ 2365455358 GnrtrPhsCPwrFtrLggng 2521;
BA_ "SPN" SG_ 2365455614 GeneratorPhaseCApparentPower 2463;
BA_ "SPN" SG_ 2365455614 GeneratorPhaseCRealPower 2455;
BA_ "SPN" SG_ 2365455870 GeneratorPhaseCACFrequency 2439;
BA_ "SPN" SG_ 2365455870 GeneratorPhaseCACRMSCurrent 2451;
BA_ "SPN" SG_ 2365455870 GnrtrPhsCALnLnACRMSVltg 2443;
BA_ "SPN" SG_ 2365455870 GnrtrPhsCLnNtrlACRMSVltg 2447;
BA_ "SPN" SG_ 2365456126 GeneratorPhaseBPowerFactor 2466;
BA_ "SPN" SG_ 2365456126 GeneratorPhaseBReactivePower 2458;
BA_ "SPN" SG_ 2365456126 GnrtrPhsBPwrFtrLggng 2520;
BA_ "SPN" SG_ 2365456382 GeneratorPhaseBApparentPower 2462;
BA_ "SPN" SG_ 2365456382 GeneratorPhaseBRealPower 2454;
BA_ "SPN" SG_ 2365456894 GeneratorPhaseAPowerFactor 2465;
BA_ "SPN" SG_ 2365456894 GeneratorPhaseAReactivePower 2457;
BA_ "SPN" SG_ 2365456894 GnrtrPhsAPwrFtrLggng 2519;
BA_ "SPN" SG_ 2365457150 GeneratorPhaseAApparentPower 2461;
BA_ "SPN" SG_ 2365457150 GeneratorPhaseARealPower 2453;
BA_ "SPN" SG_ 2365457406 GeneratorPhaseAACFrequency 2437;
BA_ "SPN" SG_ 2365457406 GeneratorPhaseAACRMSCurrent 2449;
BA_ "SPN" SG_ 2365457406 GnrtrPhsABLnLnACRMSVltg 2441;
BA_ "SPN" SG_ 2365457406 GnrtrPhsALnNtrlACRMSVltg 2445;
BA_ "SPN" SG_ 2365457662 GeneratorOverallPowerFactor 2464;
BA_ "SPN" SG_ 2365457662 GeneratorTotalReactivePower 2456;
BA_ "SPN" SG_ 2365457662 GnrtrOvrllPwrFtrLggng 2518;
BA_ "SPN" SG_ 2365457918 GeneratorTotalApparentPower 2460;
BA_ "SPN" SG_ 2365457918 GeneratorTotalRealPower 2452;
BA_ "SPN" SG_ 2365458174 GeneratorAverageACFrequency 2436;
BA_ "SPN" SG_ 2365458174 GeneratorAverageACRMSCurrent 2448;
BA_ "SPN" SG_ 2365458174 GnrtrAvrgLnLnACRMSVltg 2440;
BA_ "SPN" SG_ 2365458174 GnrtrAvrgLnNtrlACRMSVltg 2444;
BA_ "SPN" SG_ 2365473278 AlternateBeamHeadLightCommand 2351;
BA_ "SPN" SG_ 2365473278 BackUpLightandAlarmHornCommand 2391;
BA_ "SPN" SG_ 2365473278 CenterStopLightCommand 2375;
BA_ "SPN" SG_ 2365473278 HighBeamHeadLightCommand 2347;
BA_ "SPN" SG_ 2365473278 ImplementClearanceLightCommand 2383;
BA_ "SPN" SG_ 2365473278 ImplementMarkerLightCommand 2379;
BA_ "SPN" SG_ 2365473278 ImplementOEMOption1LightCommand 2395;
BA_ "SPN" SG_ 2365473278 ImplementOEMOption2LightCommand 2397;
BA_ "SPN" SG_ 2365473278 ImplementRearWorkLightCommand 2405;
BA_ "SPN" SG_ 2365473278 ImplmntLftFngWrkLghtCmmnd 2399;
BA_ "SPN" SG_ 2365473278 ImplmntLftFrwrdWrkLghtCmmnd 2597;
BA_ "SPN" SG_ 2365473278 ImplmntRghtFngWrkLghtCmmnd 2406;
BA_ "SPN" SG_ 2365473278 ImplmntRghtFrwrdWrkLghtCmmnd 2401;
BA_ "SPN" SG_ 2365473278 LeftStopLightCommand 2371;
BA_ "SPN" SG_ 2365473278 LeftTurnSignalLightsCommand 2367;
BA_ "SPN" SG_ 2365473278 LightingDataRequestCommand 2393;
BA_ "SPN" SG_ 2365473278 LowBeamHeadLightCommand 2349;
BA_ "SPN" SG_ 2365473278 RearFogLightCommand 2389;
BA_ "SPN" SG_ 2365473278 RightStopLightCommand 2373;
BA_ "SPN" SG_ 2365473278 RightTurnSignalLightsCommand 2369;
BA_ "SPN" SG_ 2365473278 RotatingBeaconLightCommand 2385;
BA_ "SPN" SG_ 2365473278 RunningLightCommand 2403;
BA_ "SPN" SG_ 2365473278 TractorClearanceLightCommand 2381;
BA_ "SPN" SG_ 2365473278 TractorFrontFogLightsCommand 2387;
BA_ "SPN" SG_ 2365473278 TractorMarkerLightCommand 2377;
BA_ "SPN" SG_ 2365473278 TrtrFrntHghMntdWrkLghtsCmmnd 2355;
BA_ "SPN" SG_ 2365473278 TrtrFrntLwMntdWrkLghtsCmmnd 2353;
BA_ "SPN" SG_ 2365473278 TrtrRrHghMntdWrkLghtsCmmnd 2361;
BA_ "SPN" SG_ 2365473278 TrtrRrLwMntdWrkLghtsCmmnd 2359;
BA_ "SPN" SG_ 2365473278 TrtrSdHghMntdWrkLghtsCmmnd 2365;
BA_ "SPN" SG_ 2365473278 TrtrSdLwMntdWrkLghtsCmmnd 2363;
BA_ "SPN" SG_ 2365473278 TrtrUndrsdMntdWrkLghtsCmmnd 2357;
BA_ "SPN" SG_ 2365478910 DamperStiffnessFrontAxle 1729;
BA_ "SPN" SG_ 2365478910 DamperStiffnessLiftTagAxle 1731;
BA_ "SPN" SG_ 2365478910 DamperStiffnessRearAxle 1730;
BA_ "SPN" SG_ 2365478910 EltrnShkAsrrCntrlMdFrntAxl 1833;
BA_ "SPN" SG_ 2365478910 EltrnShkAsrrCntrlMdLftTgAxl 1831;
BA_ "SPN" SG_ 2365478910 EltrnShkAsrrCntrlMdRrAxl 1832;
BA_ "SPN" SG_ 2365479678 AboveNominalLevelFrontAxle 1737;
BA_ "SPN" SG_ 2365479678 AboveNominalLevelRearAxle 1736;
BA_ "SPN" SG_ 2365479678 AllwLvlCntrlDrngBrkngStts 5294;
BA_ "SPN" SG_ 2365479678 BelowNominalLevelFrontAxle 1738;
BA_ "SPN" SG_ 2365479678 BelowNominalLevelRearAxle 1754;
BA_ "SPN" SG_ 2365479678 DoorRelease 1744;
BA_ "SPN" SG_ 2365479678 FrontAxleinBumperRange 1824;
BA_ "SPN" SG_ 2365479678 KneelingInformation 1742;
BA_ "SPN" SG_ 2365479678 LevelControlMode 1741;
BA_ "SPN" SG_ 2365479678 LiftAxle1Position 1743;
BA_ "SPN" SG_ 2365479678 LiftAxle2Position 1822;
BA_ "SPN" SG_ 2365479678 LiftingControlModeFrontAxle 1739;
BA_ "SPN" SG_ 2365479678 LiftingControlModeRearAxle 1756;
BA_ "SPN" SG_ 2365479678 LoweringControlModeFrontAxle 1740;
BA_ "SPN" SG_ 2365479678 LoweringControlModeRearAxle 1755;
BA_ "SPN" SG_ 2365479678 Memorylevel 5432;
BA_ "SPN" SG_ 2365479678 NominalLevelFrontAxle 1734;
BA_ "SPN" SG_ 2365479678 NominalLevelRearAxle 1733;
BA_ "SPN" SG_ 2365479678 RearAxleinBumperRange 1823;
BA_ "SPN" SG_ 2365479678 SecurityDevice 1746;
BA_ "SPN" SG_ 2365479678 SpdDpndntLvlCntrlStts 5296;
BA_ "SPN" SG_ 2365479678 SspnsnCntrlRfslInfrmtn 1827;
BA_ "SPN" SG_ 2365479678 SuspensionRemoteControl1 1826;
BA_ "SPN" SG_ 2365479678 SuspensionRemotecontrol2 1825;
BA_ "SPN" SG_ 2365479678 VehicleMotionInhibit 1745;
BA_ "SPN" SG_ 2365484286 Directionindicator 1619;
BA_ "SPN" SG_ 2365484286 Driver1TimeRelatedStates 1617;
BA_ "SPN" SG_ 2365484286 Driver1workingstate 1612;
BA_ "SPN" SG_ 2365484286 Driver2TimeRelatedStates 1618;
BA_ "SPN" SG_ 2365484286 Driver2workingstate 1613;
BA_ "SPN" SG_ 2365484286 Drivercarddriver1 1615;
BA_ "SPN" SG_ 2365484286 Drivercarddriver2 1616;
BA_ "SPN" SG_ 2365484286 Handlinginformation 1621;
BA_ "SPN" SG_ 2365484286 Systemevent 1622;
BA_ "SPN" SG_ 2365484286 Tachographoutputshaftspeed 1623;
BA_ "SPN" SG_ 2365484286 Tachographperformance 1620;
BA_ "SPN" SG_ 2365484286 Tachographvehiclespeed 1624;
BA_ "SPN" SG_ 2365484286 Vehiclemotion 1611;
BA_ "SPN" SG_ 2365484286 VehicleOverspeed 1614;
BA_ "SPN" SG_ 2365485566 LaserTracerHorizontalDeviation 1581;
BA_ "SPN" SG_ 2365485566 LaserTracerInformation 1583;
BA_ "SPN" SG_ 2365485566 LaserTracerTargetDeviation 1579;
BA_ "SPN" SG_ 2365485566 LaserTracerVerticalDistance 1580;
BA_ "SPN" SG_ 2365485566 LEDDisplayData2 1582;
BA_ "SPN" SG_ 2365485822 BladeControlMode 1578;
BA_ "SPN" SG_ 2365485822 BladeControlModeLeft 5407;
BA_ "SPN" SG_ 2365485822 BladeControlModeRight 5408;
BA_ "SPN" SG_ 2365485822 BladeDurationandDirection 1577;
BA_ "SPN" SG_ 2365485822 LandLevelingSystemEnableStatus 5409;
BA_ "SPN" SG_ 2365486078 MastPosition 1576;
BA_ "SPN" SG_ 2365486334 BldHghtStPntHghRsltn 1759;
BA_ "SPN" SG_ 2365486334 ModifyLevelingSystemSetPoint 1575;
BA_ "SPN" SG_ 2365486590 AbsoluteLaserStrikePosition 2794;
BA_ "SPN" SG_ 2365486590 LaserReceiverType 2576;
BA_ "SPN" SG_ 2365486590 LaserStrikeDataLatency 2793;
BA_ "SPN" SG_ 2365486590 LaserStrikeVerticalDeviation 1574;
BA_ "SPN" SG_ 2431649790 DriverAlertnessWarning 7473;
BA_ "SPN" SG_ 2431649790 LaneDepartureImminentLeftSide 1700;
BA_ "SPN" SG_ 2431649790 LaneDepartureImminentRightSide 1701;
BA_ "SPN" SG_ 2431649790 LaneDepartureLeft 3565;
BA_ "SPN" SG_ 2431649790 LaneDepartureRight 3566;
BA_ "SPN" SG_ 2431649790 LftSdLnDprtrAstlWrnngCmmnd 8138;
BA_ "SPN" SG_ 2431649790 LftSdLnDprtrOptlWrnngCmmnd 8136;
BA_ "SPN" SG_ 2431649790 RghtSdLnDprtrAstlWrnngCmmnd 8137;
BA_ "SPN" SG_ 2431649790 RghtSdLnDprtrOptlWrnngCmmnd 8135;
BA_ "SPN" SG_ 2431649790 RghtSdLnDprtrHptWrnngCmmnd 9749;
BA_ "SPN" SG_ 2431649790 LftSdLnDprtrHptWrnngCmmnd 9750;
BA_ "SPN" SG_ 2431654654 EngnFlAttr1CntrlCmmnd 633;
BA_ "SPN" SG_ 2431654654 EngnFlAttr2CntrlCmmnd 1244;
BA_ "SPN" SG_ 2431654654 EngnThrttlAttr1CntrlCmmnd 3464;
BA_ "SPN" SG_ 2431654654 EngnThrttlAttr2CntrlCmmnd 3465;
BA_ "SPN" SG_ 2431661054 Aftrtrtmnt1SCRIntrmdtNH3 5848;
BA_ "SPN" SG_ 2431661054 Aftrtrtmnt1SCRIntrmdtNH3RdngStl 5850;
BA_ "SPN" SG_ 2431661054 Atttt1SCRItdtNH3SsHtCt 5854;
BA_ "SPN" SG_ 2431661054 Atttt1SCRItdtNH3SsHtPFMI 5853;
BA_ "SPN" SG_ 2431661054 Atttt1SCRItdtNH3SsPFMI 5849;
BA_ "SPN" SG_ 2431661054 Atttt1SCRItdtNH3SsPwIR 5851;
BA_ "SPN" SG_ 2431661054 Atttt1SCRItdtNH3SstTpt 5852;
BA_ "SPN" SG_ 2431661310 Aftrtrtmnt2SCRIntrmdtNH3 5855;
BA_ "SPN" SG_ 2431661310 Aftrtrtmnt2SCRIntrmdtNH3RdngStl 5857;
BA_ "SPN" SG_ 2431661310 Atttt2SCRItdtNH3SsHtCt 5861;
BA_ "SPN" SG_ 2431661310 Atttt2SCRItdtNH3SsHtPFMI 5860;
BA_ "SPN" SG_ 2431661310 Atttt2SCRItdtNH3SsPFMI 5856;
BA_ "SPN" SG_ 2431661310 Atttt2SCRItdtNH3SsPwIR 5858;
BA_ "SPN" SG_ 2431661310 Atttt2SCRItdtNH3SstTpt 5859;
BA_ "SPN" SG_ 2431708670 EngineStartAbortRequest 7747;
BA_ "SPN" SG_ 2431708670 EngineStartConsent 7746;
BA_ "SPN" SG_ 2431708670 EngineStartControlChecksum 7751;
BA_ "SPN" SG_ 2431708670 EngineStarter1Feedback 7748;
BA_ "SPN" SG_ 2431708670 EngineStarter2Feedback 7749;
BA_ "SPN" SG_ 2431708670 EngineStartRequest 7745;
BA_ "SPN" SG_ 2431708670 EngnStrtCntrlMssgCntr 7750;
BA_ "SPN" SG_ 2431708670 TrnsmssnShftSltrRqstdVhlDrtn 7788;
BA_ "SPN" SG_ 2431710718 AtmtEngnStrtCnsntSmmr 7756;
BA_ "SPN" SG_ 2431710718 EngineStartArbitratorChecksum 7758;
BA_ "SPN" SG_ 2431710718 EngineStartControlMessageRate 7752;
BA_ "SPN" SG_ 2431710718 EngineStarterCommand 7753;
BA_ "SPN" SG_ 2431710718 EngineStartRequestLatchStatus 7754;
BA_ "SPN" SG_ 2431710718 EngnStrtArtrtrMssgCntr 7757;
BA_ "SPN" SG_ 2431710718 OprtrEngnStrtCnsntSmmr 7755;
BA_ "SPN" SG_ 2431717886 EngnFlVlv1DffrntlPrssrHghRsltn 8494;
BA_ "SPN" SG_ 2431717886 EngnGssFlSpplFltrDffrntlPrssr 12301;
BA_ "SPN" SG_ 2431717886 EngnGssFlSpplFltrIntkPrssr 12302;
BA_ "SPN" SG_ 2431719166 WellStimulationPumpFlowRate 8650;
BA_ "SPN" SG_ 2431719166 WellStimulationPumpRodLoad 8648;
BA_ "SPN" SG_ 2431719166 WllStmltnPmpCvttnStts 8649;
BA_ "SPN" SG_ 2431719166 WllStmltnPmpFldEndVlvLk 8651;
BA_ "SPN" SG_ 2431719166 WllStmltnPmpRtdRdLdPrnt 12811;
BA_ "SPN" SG_ 2432471038 EngnFlVprzr1DshrgTmprtr 6610;
BA_ "SPN" SG_ 2432471038 EngnGssFlSpplPrssr1ExtnddRng 6646;
BA_ "SPN" SG_ 2432471038 GssFlAmltrTmprtr 6815;
BA_ "SPN" SG_ 2432471038 EGssFSppPssRtCtCd 9649;
BA_ "SPN" SG_ 2432492542 EngnExhstBrkAttrCmmnd 5543;
BA_ "SPN" SG_ 2432492542 EngnTrhrgr1TrnDsrdOtltPrssr 5542;
BA_ "SPN" SG_ 2432492542 EngnTrhrgr1TrnOtltPrssr 5541;
BA_ "SPN" SG_ 2432492542 EngnTrhrgr2TrnDsrdOtltPrssr 5545;
BA_ "SPN" SG_ 2432492542 EngnTrhrgr2TrnOtltPrssr 5544;
BA_ "SPN" SG_ 2432499198 CmmnddEngnFlInjtnCntrlPrssr 5314;
BA_ "SPN" SG_ 2432499198 CommandedEngineFuelRailPressure 5313;
BA_ "SPN" SG_ 2432499198 EngnExhstGsRrltn2Vlv2Pstn 5263;
BA_ "SPN" SG_ 2432499198 EngnExhstGsRrltn2VlvPstn 5262;
BA_ "SPN" SG_ 2432520702 AftrlrClntThrmsttMd 4198;
BA_ "SPN" SG_ 2432520702 DsrdAftrlrClntIntkTmprtr 4199;
BA_ "SPN" SG_ 2432520702 DsrdAftrlrClntThrmsttOpnng 4200;
BA_ "SPN" SG_ 2432520702 EngnChrgArClrBpssVlv1Cmmnd 7421;
BA_ "SPN" SG_ 2432520702 EngnChrgArClrBpssVlv2Cmmnd 7422;
BA_ "SPN" SG_ 2432520958 DsrdEngnClntPmpOtltTmprtr 4196;
BA_ "SPN" SG_ 2432520958 DsrdEngnClntThrmsttOpnng 4197;
BA_ "SPN" SG_ 2432520958 EngineCoolantThermostatMode 4195;
BA_ "SPN" SG_ 2432520958 EngnAxlrClrSpplVlv1AttrCmmnd 5546;
BA_ "SPN" SG_ 2432520958 EngnAxlrClrSpplVlv2AttrCmmnd 5547;
BA_ "SPN" SG_ 2432541438 EngineFuel1Temperature2 3468;
BA_ "SPN" SG_ 2432541438 EngnFlSstm2GsMssFlwRt 3467;
BA_ "SPN" SG_ 2432541438 EngnFlVlv2IntkAsltPrssr 3466;
BA_ "SPN" SG_ 2432541438 EngnFlVlv2OtltAsltPrssr 3469;
BA_ "SPN" SG_ 2432541694 EngnTrhrgrCmprssrBpssAttr1Cmmnd 3470;
BA_ "SPN" SG_ 2432541694 EngnTrhrgrCmprssrBpssAttr1Pstn 3675;
BA_ "SPN" SG_ 2432541694 EngnTrhrgrCmprssrBpssAttr2Cmmnd 5369;
BA_ "SPN" SG_ 2432541694 EngnVrlGmtrTrhrgrAttr1 641;
BA_ "SPN" SG_ 2432541694 ETCpssBpssAtt1DsdPst 5366;
BA_ "SPN" SG_ 2432541694 ETCpssBpssAtt1PFMI 5367;
BA_ "SPN" SG_ 2432541694 ETCpssBpssAtt1TptStts 5368;
BA_ "SPN" SG_ 2432593918 ACCDistanceAlertSignal 1796;
BA_ "SPN" SG_ 2432593918 ACCSystemShutoffWarning 1797;
BA_ "SPN" SG_ 2432593918 ACCTargetDetected 1798;
BA_ "SPN" SG_ 2432593918 AdaptiveCruiseControlMode 1590;
BA_ "SPN" SG_ 2432593918 AdaptiveCruiseControlSetSpeed 1588;
BA_ "SPN" SG_ 2432593918 Adptvrsntrlstdstnmd 1589;
BA_ "SPN" SG_ 2432593918 Distancetoforwardvehicle 1587;
BA_ "SPN" SG_ 2432593918 ForwardCollisionWarning 5022;
BA_ "SPN" SG_ 2432593918 Roadcurvature 1591;
BA_ "SPN" SG_ 2432593918 Speedofforwardvehicle 1586;
BA_ "SPN" SG_ 2432595710 DisplayDeadbands 2577;
BA_ "SPN" SG_ 2432595710 LEDDisplayData1 1573;
BA_ "SPN" SG_ 2432595710 LEDDisplayDeadbandControl 1806;
BA_ "SPN" SG_ 2432595710 LEDDisplayModeControl 1805;
BA_ "SPN" SG_ 2432595710 LEDPatternControl 2578;
BA_ "SPN" SG_ 2498776830 EngnClndr1AvrgCmstnDrtn 6486;
BA_ "SPN" SG_ 2498776830 EngnClndr1AvrgCntrfCmstnTmng 6485;
BA_ "SPN" SG_ 2498776830 EngnClndr1AvrgStrtfCmstnTmng 6484;
BA_ "SPN" SG_ 2498776830 EngnClndr1IndtdMnEfftvPrssr 6483;
BA_ "SPN" SG_ 2498777086 EngnClndr2AvrgCmstnDrtn 6490;
BA_ "SPN" SG_ 2498777086 EngnClndr2AvrgCntrfCmstnTmng 6489;
BA_ "SPN" SG_ 2498777086 EngnClndr2AvrgStrtfCmstnTmng 6488;
BA_ "SPN" SG_ 2498777086 EngnClndr2IndtdMnEfftvPrssr 6487;
BA_ "SPN" SG_ 2498777342 EngnClndr3AvrgCmstnDrtn 6494;
BA_ "SPN" SG_ 2498777342 EngnClndr3AvrgCntrfCmstnTmng 6493;
BA_ "SPN" SG_ 2498777342 EngnClndr3AvrgStrtfCmstnTmng 6492;
BA_ "SPN" SG_ 2498777342 EngnClndr3IndtdMnEfftvPrssr 6491;
BA_ "SPN" SG_ 2498777598 EngnClndr4AvrgCmstnDrtn 6498;
BA_ "SPN" SG_ 2498777598 EngnClndr4AvrgCntrfCmstnTmng 6497;
BA_ "SPN" SG_ 2498777598 EngnClndr4AvrgStrtfCmstnTmng 6496;
BA_ "SPN" SG_ 2498777598 EngnClndr4IndtdMnEfftvPrssr 6495;
BA_ "SPN" SG_ 2498777854 EngnClndr5AvrgCmstnDrtn 6502;
BA_ "SPN" SG_ 2498777854 EngnClndr5AvrgCntrfCmstnTmng 6501;
BA_ "SPN" SG_ 2498777854 EngnClndr5AvrgStrtfCmstnTmng 6500;
BA_ "SPN" SG_ 2498777854 EngnClndr5IndtdMnEfftvPrssr 6499;
BA_ "SPN" SG_ 2498778110 EngnClndr6AvrgCmstnDrtn 6506;
BA_ "SPN" SG_ 2498778110 EngnClndr6AvrgCntrfCmstnTmng 6505;
BA_ "SPN" SG_ 2498778110 EngnClndr6AvrgStrtfCmstnTmng 6504;
BA_ "SPN" SG_ 2498778110 EngnClndr6IndtdMnEfftvPrssr 6503;
BA_ "SPN" SG_ 2498778366 EngnClndr7AvrgCmstnDrtn 6510;
BA_ "SPN" SG_ 2498778366 EngnClndr7AvrgCntrfCmstnTmng 6509;
BA_ "SPN" SG_ 2498778366 EngnClndr7AvrgStrtfCmstnTmng 6508;
BA_ "SPN" SG_ 2498778366 EngnClndr7IndtdMnEfftvPrssr 6507;
BA_ "SPN" SG_ 2498778622 EngnClndr8AvrgCmstnDrtn 6514;
BA_ "SPN" SG_ 2498778622 EngnClndr8AvrgCntrfCmstnTmng 6513;
BA_ "SPN" SG_ 2498778622 EngnClndr8AvrgStrtfCmstnTmng 6512;
BA_ "SPN" SG_ 2498778622 EngnClndr8IndtdMnEfftvPrssr 6511;
BA_ "SPN" SG_ 2498778878 EngnClndr9AvrgCmstnDrtn 6518;
BA_ "SPN" SG_ 2498778878 EngnClndr9AvrgCntrfCmstnTmng 6517;
BA_ "SPN" SG_ 2498778878 EngnClndr9AvrgStrtfCmstnTmng 6516;
BA_ "SPN" SG_ 2498778878 EngnClndr9IndtdMnEfftvPrssr 6515;
BA_ "SPN" SG_ 2498779134 EngnClndr10AvrgCmstnDrtn 6522;
BA_ "SPN" SG_ 2498779134 EngnClndr10AvrgCntrfCmstnTmng 6521;
BA_ "SPN" SG_ 2498779134 EngnClndr10AvrgStrtfCmstnTmng 6520;
BA_ "SPN" SG_ 2498779134 EngnClndr10IndtdMnEfftvPrssr 6519;
BA_ "SPN" SG_ 2498779390 EngnClndr11AvrgCmstnDrtn 6526;
BA_ "SPN" SG_ 2498779390 EngnClndr11AvrgCntrfCmstnTmng 6525;
BA_ "SPN" SG_ 2498779390 EngnClndr11AvrgStrtfCmstnTmng 6524;
BA_ "SPN" SG_ 2498779390 EngnClndr11IndtdMnEfftvPrssr 6523;
BA_ "SPN" SG_ 2498779646 EngnClndr12AvrgCmstnDrtn 6530;
BA_ "SPN" SG_ 2498779646 EngnClndr12AvrgCntrfCmstnTmng 6529;
BA_ "SPN" SG_ 2498779646 EngnClndr12AvrgStrtfCmstnTmng 6528;
BA_ "SPN" SG_ 2498779646 EngnClndr12IndtdMnEfftvPrssr 6527;
BA_ "SPN" SG_ 2498779902 EngnClndr13AvrgCmstnDrtn 6534;
BA_ "SPN" SG_ 2498779902 EngnClndr13AvrgCntrfCmstnTmng 6533;
BA_ "SPN" SG_ 2498779902 EngnClndr13AvrgStrtfCmstnTmng 6532;
BA_ "SPN" SG_ 2498779902 EngnClndr13IndtdMnEfftvPrssr 6531;
BA_ "SPN" SG_ 2498780158 EngnClndr14AvrgCmstnDrtn 6538;
BA_ "SPN" SG_ 2498780158 EngnClndr14AvrgCntrfCmstnTmng 6537;
BA_ "SPN" SG_ 2498780158 EngnClndr14AvrgStrtfCmstnTmng 6536;
BA_ "SPN" SG_ 2498780158 EngnClndr14IndtdMnEfftvPrssr 6535;
BA_ "SPN" SG_ 2498780414 EngnClndr15AvrgCmstnDrtn 6542;
BA_ "SPN" SG_ 2498780414 EngnClndr15AvrgCntrfCmstnTmng 6541;
BA_ "SPN" SG_ 2498780414 EngnClndr15AvrgStrtfCmstnTmng 6540;
BA_ "SPN" SG_ 2498780414 EngnClndr15IndtdMnEfftvPrssr 6539;
BA_ "SPN" SG_ 2498780670 EngnClndr16AvrgCmstnDrtn 6546;
BA_ "SPN" SG_ 2498780670 EngnClndr16AvrgCntrfCmstnTmng 6545;
BA_ "SPN" SG_ 2498780670 EngnClndr16AvrgStrtfCmstnTmng 6544;
BA_ "SPN" SG_ 2498780670 EngnClndr16IndtdMnEfftvPrssr 6543;
BA_ "SPN" SG_ 2498780926 EngnClndr17AvrgCmstnDrtn 6550;
BA_ "SPN" SG_ 2498780926 EngnClndr17AvrgCntrfCmstnTmng 6549;
BA_ "SPN" SG_ 2498780926 EngnClndr17AvrgStrtfCmstnTmng 6548;
BA_ "SPN" SG_ 2498780926 EngnClndr17IndtdMnEfftvPrssr 6547;
BA_ "SPN" SG_ 2498781182 EngnClndr18AvrgCmstnDrtn 6554;
BA_ "SPN" SG_ 2498781182 EngnClndr18AvrgCntrfCmstnTmng 6553;
BA_ "SPN" SG_ 2498781182 EngnClndr18AvrgStrtfCmstnTmng 6552;
BA_ "SPN" SG_ 2498781182 EngnClndr18IndtdMnEfftvPrssr 6551;
BA_ "SPN" SG_ 2498781438 EngnClndr19AvrgCmstnDrtn 6558;
BA_ "SPN" SG_ 2498781438 EngnClndr19AvrgCntrfCmstnTmng 6557;
BA_ "SPN" SG_ 2498781438 EngnClndr19AvrgStrtfCmstnTmng 6556;
BA_ "SPN" SG_ 2498781438 EngnClndr19IndtdMnEfftvPrssr 6555;
BA_ "SPN" SG_ 2498781694 EngnClndr20AvrgCmstnDrtn 6562;
BA_ "SPN" SG_ 2498781694 EngnClndr20AvrgCntrfCmstnTmng 6561;
BA_ "SPN" SG_ 2498781694 EngnClndr20AvrgStrtfCmstnTmng 6560;
BA_ "SPN" SG_ 2498781694 EngnClndr20IndtdMnEfftvPrssr 6559;
